VERSION ""

NS_ :

BS_:

BU_: EBOOST_HS CGM_HS BSM_HS HCP_B_HS AVM_HS PFAF_HS LVMPC_HS DCDC_HS TRCM_HS AMP_HS VICM2_HS FICM_HS ARS_HS MCP_B_HS MCP_A_HS ICCM_OBD_HS SAS_HS ACCM_HS VLBS_HS EBCM_OBD_HS HCP_T_HS EDI_HS HPCC_HS VITM_OBD_HS VICM_HS HCP_HS APPS_HS ICCM_HS EOCM_F_HS GPCM_HS VCM_HS HMIM_HS VES_HS Dummy_HS MCP_C_HS ONSTAR_HS EPS_HS TestTool_HS MCP_HS BCP_HS ALC_HS AHL_AFL_HS SADS_HS EPB_HS FCM_HS TCCM_HS RDCM_HS PTO_HS EBCM_HS ACC_HS BCM_HS TCM_HS ECM_HS
VAL_TABLE_ vt_BooleanValues 1 "true" 0 "false" ;
VAL_TABLE_ ChrgSysAudblIndRq 7 "Unused and Reserved3" 6 "Unused and Reserved2" 5 "Unused and Reserved1" 4 "Sequence 4" 3 "Sequence 3" 2 "Sequence 2" 1 "Sequence 1" 0 "Inactive" ;
VAL_TABLE_ EngPstnSnsngOpMode 2 "CAM Failed" 1 "Crank Failed" 0 "Normal" ;
VAL_TABLE_ EASSI_StrtTyp 7 "Type G" 6 "Type F" 5 "Type E" 4 "Type D" 3 "Type C" 2 "Type B" 1 "Type A" 0 "No Start" ;
VAL_TABLE_ EASSI_StrtStpSt 3 "Engine Stopping" 2 "Engine Starting" 1 "Engine Running" 0 "Engine Off" ;
VAL_TABLE_ TEPI_TrnsEngdPrFlwSt 7 "Unused and Reserved4" 6 "Unused and Reserved3" 5 "Unused and Reserved2" 4 "Unused and Reserved1" 3 "Reverse Engaged" 2 "Drive Engaged" 1 "No Powerflow" 0 "Unavailable " ;
VAL_TABLE_ TransActlRng 15 "Unused and Reserved2" 14 "Unused and Reserved1" 13 "Fourth Drive Position" 12 "Between Third and Fourth Drive Position" 11 "Third Drive Position" 10 "Between Second and Third Drive Position" 9 "Second Drive Position" 8 "Between First and Second Drive Position" 7 "First Drive Position" 6 "Between Neutral and First Drive Position" 5 "Neutral Position" 4 "Between Reverse and Neutral" 3 "Reverse Position" 2 "Between Park and Reverse" 1 "Park Position" 0 "Unknown Position" ;
VAL_TABLE_ ElcTransRngRq 7 "Unused and Reserved" 6 "Manual Range" 5 "Low Range" 4 "Drive" 3 "Neutral" 2 "Reverse" 1 "Park" 0 "No Request" ;
VAL_TABLE_ ESBR_AutoBrkgRqTyp 3 "Unused and Reserved" 2 "Hold Deny Driver Release" 1 "Hold Allow Driver Release" 0 "Release" ;
VAL_TABLE_ ESBR_AutoBrkgRqd 1 "Braking Requested" 0 "Braking Not Requested " ;
VAL_TABLE_ PndgTrnsfrCsRngShft 3 "Shift Out of Neutral Range" 2 "Shift Out of Low Range" 1 "Shift Out of High Range" 0 "None" ;
VAL_TABLE_ EngDetPndTrnCsRngShf 3 "Shift Out of Neutral Range" 2 "Shift Out of Low Range" 1 "Shift Out of High Range" 0 "None" ;
VAL_TABLE_ ElecShfRngDisp 15 "Unused & Reserved" 14 "Unused & Reserved" 13 "Unused & Reserved" 12 "Park Requested And Denied" 11 "Drive Requested And In Progress" 10 "Neutral Requested And In Progress" 9 "Reverse Requested And In Progress" 8 "Park Requested And In Progress" 7 "Reserved" 6 "Manual Nominal" 5 "Low Nominal" 4 "Drive Nominal" 3 "Neutral Nominal" 2 "Reverse Nominal" 1 "Park Nominal" 0 "No Display " ;
VAL_TABLE_ AVHSwtchStats 1 "Active" 0 "Not Active" ;
VAL_TABLE_ ThrmlRefCompStatFdbck 3 "Invalid" 2 "Inoperative" 1 "Degraded Operation" 0 "Normal Operation" ;
VAL_TABLE_ ManTransIndReq 3 "Indication 3" 2 "Indication 2" 1 "Indication 1" 0 "No Indication" ;
VAL_TABLE_ BCS2ERDTC_SysDesigntr 15 "U3-Network Codes Reserved" 14 "U2-Network Codes Reserved" 13 "U1-Network Codes MFG Controlled" 12 "U0-Network Codes SAE Controlled" 11 "B3-Body Codes Reserved" 10 "B2-Body Codes Reserved" 9 "B1-Body Codes MFG Controlled" 8 "B0-Body Codes SAE Controlled" 7 "C3-Chassis Codes Reserved" 6 "C2-Chassis Codes Reserved" 5 "C1-Chassis Codes MFG Controlled" 4 "C0-Chassis Codes SAE Controlled" 3 "P3-Powertrain Codes Reserved" 2 "P2-Powertrain Codes Reserved" 1 "P1-Powertrain Codes MFG Controlled" 0 "P0-Powertrain Codes SAE Controlled" ;
VAL_TABLE_ BCS1ERDTC_SysDesigntr 15 "U3-Network Codes Reserved" 14 "U2-Network Codes Reserved" 13 "U1-Network Codes MFG Controlled" 12 "U0-Network Codes SAE Controlled" 11 "B3-Body Codes Reserved" 10 "B2-Body Codes Reserved" 9 "B1-Body Codes MFG Controlled" 8 "B0-Body Codes SAE Controlled" 7 "C3-Chassis Codes Reserved" 6 "C2-Chassis Codes Reserved" 5 "C1-Chassis Codes MFG Controlled" 4 "C0-Chassis Codes SAE Controlled" 3 "P3-Powertrain Codes Reserved" 2 "P2-Powertrain Codes Reserved" 1 "P1-Powertrain Codes MFG Controlled" 0 "P0-Powertrain Codes SAE Controlled" ;
VAL_TABLE_ TIDCTR_TrqIntvTyp 3 "Reserved" 2 "Minimum Limit" 1 "Maximum Limit" 0 "No Request" ;
VAL_TABLE_ TIDCTR_TrqRespTyp 3 "Automatic Actuator Selection" 2 "Maximum Range" 1 "Pleasability Limited" 0 "Inactive" ;
VAL_TABLE_ ExtHlStrAssCsStRq 2 "Standard Hold" 1 "Extended Hold" 0 "No Action" ;
VAL_TABLE_ ExtHlStrAssCsCrStVal 2 "Standard Hold" 1 "Extended Hold" 0 "No Action" ;
VAL_TABLE_ BSMCT_Mult 3 "Multiplier Factor 256" 2 "Multiplier Factor 64" 1 "Multiplier Factor 8" 0 "Multiplier Factor 1" ;
VAL_TABLE_ CDP_HVDevShtdnCdARCSt 2 "Indeterminate" 1 "Fault" 0 "No Fault" ;
VAL_TABLE_ CDP_CmpSpdReqARCSt 2 "Indeterminate" 1 "Fault" 0 "No Fault" ;
VAL_TABLE_ CDSP_CmpOvrTmpSt 2 "Indeterminate" 1 "Fault" 0 "No Fault" ;
VAL_TABLE_ CDSP_CmpHVAbnrlOrVltSt 2 "Indeterminate" 1 "Fault" 0 "No Fault" ;
VAL_TABLE_ CDSP_CmpHVUndrVltgSt 2 "Indeterminate" 1 "Fault" 0 "No Fault" ;
VAL_TABLE_ CDSP_CmpHVOvrVltgSt 2 "Indeterminate" 1 "Fault" 0 "No Fault" ;
VAL_TABLE_ CDSP_CmpHVOvrCrntSt 2 "Indeterminate" 1 "Fault" 0 "No Fault" ;
VAL_TABLE_ CDSP_CmpIntShdwnFltSt 2 "Indeterminate" 1 "Fault" 0 "No Fault" ;
VAL_TABLE_ CDSP_CmpIntRecblFltSt 2 "Indeterminate" 1 "Fault" 0 "No Fault" ;
VAL_TABLE_ CDSP_CmpOpOvrldSt 2 "Indeterminate" 1 "Fault" 0 "No Fault" ;
VAL_TABLE_ CDSP_CmpDrCrctFltSt 2 "Indeterminate" 1 "Fault" 0 "No Fault" ;
VAL_TABLE_ CDSP_CmpMtrPerfFltSt 2 "Indeterminate" 1 "Fault" 0 "No Fault" ;
VAL_TABLE_ CDSP_CmpEEPROMFltSt 2 "Indeterminate" 1 "Fault" 0 "No Fault" ;
VAL_TABLE_ CDSP_CmpROMFltSt 2 "Indeterminate" 1 "Fault" 0 "No Fault" ;
VAL_TABLE_ CDSP_CmpRAMFltSt 2 "Indeterminate" 1 "Fault" 0 "No Fault" ;
VAL_TABLE_ CSSP_CmpIGBTTpOtRgLSt 2 "Indeterminate" 1 "Fault" 0 "No Fault" ;
VAL_TABLE_ CSSP_CmpIGBTTpOtRgHSt 2 "Indeterminate" 1 "Fault" 0 "No Fault" ;
VAL_TABLE_ CSSP_CmpCPUTmpOtRgLSt 2 "Indeterminate" 1 "Fault" 0 "No Fault" ;
VAL_TABLE_ CSSP_CmpCPUTmpOtRgHSt 2 "Indeterminate" 1 "Fault" 0 "No Fault" ;
VAL_TABLE_ CSSP_CmpHVSnsOtRgLSt 2 "Indeterminate" 1 "Fault" 0 "No Fault" ;
VAL_TABLE_ CSSP_CmpHVSnsOtRgHSt 2 "Indeterminate" 1 "Fault" 0 "No Fault" ;
VAL_TABLE_ CSSP_CmpPhCrntOtRgLSt 2 "Indeterminate" 1 "Fault" 0 "No Fault" ;
VAL_TABLE_ CSSP_CmpPhCrntOtRgHSt 2 "Indeterminate" 1 "Fault" 0 "No Fault" ;
VAL_TABLE_ PrtdEPBSwStat 3 "Active" 2 "Apply" 1 "Release" 0 "Not Active" ;
VAL_TABLE_ EBrkAstStat 7 "Faulted" 6 "Temporarily Failed" 5 "Not Used" 4 "Not Used" 3 "Not Used" 2 "Normal" 1 "Initializing" 0 "Not Initialized" ;
VAL_TABLE_ AdptCruzCtrlStg 7 "Performance Mode 7" 6 "Performance Mode 6" 5 "Performance Mode 5" 4 "Performance Mode 4" 3 "Performance Mode 3" 2 "Performance Mode 2" 1 "Performance Mode 1" 0 "No Action" ;
VAL_TABLE_ GFHBObjDirTrk8 1 "Ahead Traffic" 0 "Incoming Traffic" ;
VAL_TABLE_ GFHBObjDirTrk7 1 "Ahead Traffic" 0 "Incoming Traffic" ;
VAL_TABLE_ GFHBObjDirTrk6 1 "Ahead Traffic" 0 "Incoming Traffic" ;
VAL_TABLE_ GFHBObjDirTrk5 1 "Ahead Traffic" 0 "Incoming Traffic" ;
VAL_TABLE_ GFHBObjDirTrk4 1 "Ahead Traffic" 0 "Incoming Traffic" ;
VAL_TABLE_ GFHBObjDirTrk3 1 "Ahead Traffic" 0 "Incoming Traffic" ;
VAL_TABLE_ GFHBObjDirTrk2 1 "Ahead Traffic" 0 "Incoming Traffic" ;
VAL_TABLE_ GFHBObjDirTrk1 1 "Ahead Traffic" 0 "Incoming Traffic" ;
VAL_TABLE_ GFHBFwVsnRelLaneTrk8 3 "Left Lane" 2 "Right Lane" 1 "Host Lane" 0 "Unknown" ;
VAL_TABLE_ GFHBFwVsnRelLaneTrk7 3 "Left Lane" 2 "Right Lane" 1 "Host Lane" 0 "Unknown" ;
VAL_TABLE_ GFHBFwVsnRelLaneTrk6 3 "Left Lane" 2 "Right Lane" 1 "Host Lane" 0 "Unknown" ;
VAL_TABLE_ GFHBFwVsnRelLaneTrk5 3 "Left Lane" 2 "Right Lane" 1 "Host Lane" 0 "Unknown" ;
VAL_TABLE_ GFHBFwVsnRelLaneTrk4 3 "Left Lane" 2 "Right Lane" 1 "Host Lane" 0 "Unknown" ;
VAL_TABLE_ GFHBFwVsnRelLaneTrk3 3 "Left Lane" 2 "Right Lane" 1 "Host Lane" 0 "Unknown" ;
VAL_TABLE_ GFHBFwVsnRelLaneTrk2 3 "Left Lane" 2 "Right Lane" 1 "Host Lane" 0 "Unknown" ;
VAL_TABLE_ GFHBFwVsnRelLaneTrk1 3 "Left Lane" 2 "Right Lane" 1 "Host Lane" 0 "Unknown" ;
VAL_TABLE_ GFHBFwVsnMesStatTrk8 3 "Measured this cycle" 2 "Latent track not detected this cycle" 1 "New Object" 0 "No Object" ;
VAL_TABLE_ GFHBFwVsnMesStatTrk7 3 "Measured this cycle" 2 "Latent track not detected this cycle" 1 "New Object" 0 "No Object" ;
VAL_TABLE_ GFHBFwVsnMesStatTrk6 3 "Measured this cycle" 2 "Latent track not detected this cycle" 1 "New Object" 0 "No Object" ;
VAL_TABLE_ GFHBFwVsnMesStatTrk5 3 "Measured this cycle" 2 "Latent track not detected this cycle" 1 "New Object" 0 "No Object" ;
VAL_TABLE_ GFHBFwVsnMesStatTrk4 3 "Measured this cycle" 2 "Latent track not detected this cycle" 1 "New Object" 0 "No Object" ;
VAL_TABLE_ GFHBFwVsnMesStatTrk3 3 "Measured this cycle" 2 "Latent track not detected this cycle" 1 "New Object" 0 "No Object" ;
VAL_TABLE_ GFHBFwVsnMesStatTrk2 3 "Measured this cycle" 2 "Latent track not detected this cycle" 1 "New Object" 0 "No Object" ;
VAL_TABLE_ GFHBFwVsnMesStatTrk1 3 "Measured this cycle" 2 "Latent track not detected this cycle" 1 "New Object" 0 "No Object" ;
VAL_TABLE_ GFHBFwVsnCnfdncTrk8 3 "Confident" 2 "Speculative" 1 "Highly Speculative" 0 "Invalid" ;
VAL_TABLE_ GFHBFwVsnCnfdncTrk7 3 "Confident" 2 "Speculative" 1 "Highly Speculative" 0 "Invalid" ;
VAL_TABLE_ GFHBFwVsnCnfdncTrk6 3 "Confident" 2 "Speculative" 1 "Highly Speculative" 0 "Invalid" ;
VAL_TABLE_ GFHBFwVsnCnfdncTrk5 3 "Confident" 2 "Speculative" 1 "Highly Speculative" 0 "Invalid" ;
VAL_TABLE_ GFHBFwVsnCnfdncTrk4 3 "Confident" 2 "Speculative" 1 "Highly Speculative" 0 "Invalid" ;
VAL_TABLE_ GFHBFwVsnCnfdncTrk3 3 "Confident" 2 "Speculative" 1 "Highly Speculative" 0 "Invalid" ;
VAL_TABLE_ GFHBFwVsnCnfdncTrk2 3 "Confident" 2 "Speculative" 1 "Highly Speculative" 0 "Invalid" ;
VAL_TABLE_ GFHBFwVsnCnfdncTrk1 0 "Invalid" 3 "Confident" 2 "Speculative" 1 "Highly Speculative" ;
VAL_TABLE_ GFHBFVsnObjTypTrkRev8 12 "Cluster Object" 11 "Child Close to Danger Zone" 10 "Pedestrian Moving Out of Danger Zone" 9 "Pedestrian Moving Into Danger Zone" 8 "Pedestrian Standing Outside Danger Zone" 7 "No Object Present" 6 "Fixed Roadside Object" 5 "Fixed Overhead Object" 4 "Pedestrian" 3 "Motorcycle/ Bicycle" 2 "Large Vehicle (Semi)" 1 "4 Wheel Vehicle (Car)" 0 "Unknown" ;
VAL_TABLE_ GFHBFVsnObjTypTrkRev7 12 "Cluster Object" 11 "Child Close to Danger Zone" 10 "Pedestrian Moving Out of Danger Zone" 9 "Pedestrian Moving Into Danger Zone" 8 "Pedestrian Standing Outside Danger Zone" 7 "No Object Present" 6 "Fixed Roadside Object" 5 "Fixed Overhead Object" 4 "Pedestrian" 3 "Motorcycle/ Bicycle" 2 "Large Vehicle (Semi)" 1 "4 Wheel Vehicle (Car)" 0 "Unknown" ;
VAL_TABLE_ GFHBFVsnObjTypTrkRev6 12 "Cluster Object" 11 "Child Close to Danger Zone" 10 "Pedestrian Moving Out of Danger Zone" 9 "Pedestrian Moving Into Danger Zone" 8 "Pedestrian Standing Outside Danger Zone" 7 "No Object Present" 6 "Fixed Roadside Object" 5 "Fixed Overhead Object" 4 "Pedestrian" 3 "Motorcycle/ Bicycle" 2 "Large Vehicle (Semi)" 1 "4 Wheel Vehicle (Car)" 0 "Unknown" ;
VAL_TABLE_ GFHBFVsnObjTypTrkRev5 12 "Cluster Object" 11 "Child Close to Danger Zone" 10 "Pedestrian Moving Out of Danger Zone" 9 "Pedestrian Moving Into Danger Zone" 8 "Pedestrian Standing Outside Danger Zone" 7 "No Object Present" 6 "Fixed Roadside Object" 5 "Fixed Overhead Object" 4 "Pedestrian" 3 "Motorcycle/ Bicycle" 2 "Large Vehicle (Semi)" 1 "4 Wheel Vehicle (Car)" 0 "Unknown" ;
VAL_TABLE_ GFHBFVsnObjTypTrkRev4 12 "Cluster Object" 11 "Child Close to Danger Zone" 10 "Pedestrian Moving Out of Danger Zone" 9 "Pedestrian Moving Into Danger Zone" 8 "Pedestrian Standing Outside Danger Zone" 7 "No Object Present" 6 "Fixed Roadside Object" 5 "Fixed Overhead Object" 4 "Pedestrian" 3 "Motorcycle/ Bicycle" 2 "Large Vehicle (Semi)" 1 "4 Wheel Vehicle (Car)" 0 "Unknown" ;
VAL_TABLE_ GFHBFVsnObjTypTrkRev3 12 "Cluster Object" 11 "Child Close to Danger Zone" 10 "Pedestrian Moving Out of Danger Zone" 9 "Pedestrian Moving Into Danger Zone" 8 "Pedestrian Standing Outside Danger Zone" 7 "No Object Present" 6 "Fixed Roadside Object" 5 "Fixed Overhead Object" 4 "Pedestrian" 3 "Motorcycle/ Bicycle" 2 "Large Vehicle (Semi)" 1 "4 Wheel Vehicle (Car)" 0 "Unknown" ;
VAL_TABLE_ GFHBFVsnObjTypTrkRev2 12 "Cluster Object" 11 "Child Close to Danger Zone" 10 "Pedestrian Moving Out of Danger Zone" 9 "Pedestrian Moving Into Danger Zone" 8 "Pedestrian Standing Outside Danger Zone" 7 "No Object Present" 6 "Fixed Roadside Object" 5 "Fixed Overhead Object" 4 "Pedestrian" 3 "Motorcycle/ Bicycle" 2 "Large Vehicle (Semi)" 1 "4 Wheel Vehicle (Car)" 0 "Unknown" ;
VAL_TABLE_ GFHBFVsnObjTypTrkRev1 12 "Cluster Object" 11 "Child Close to Danger Zone" 10 "Pedestrian Moving Out of Danger Zone" 9 "Pedestrian Moving Into Danger Zone" 8 "Pedestrian Standing Outside Danger Zone" 7 "No Object Present" 6 "Fixed Roadside Object" 5 "Fixed Overhead Object" 4 "Pedestrian" 3 "Motorcycle/ Bicycle" 2 "Large Vehicle (Semi)" 1 "4 Wheel Vehicle (Car" 0 "Unknown" ;
VAL_TABLE_ SpdLmtrSttngTypAct 3 "Reserved" 2 "Auto" 1 "Manual" 0 "Off" ;
VAL_TABLE_ SetSpdLmtRchd 3 "Reserved" 2 "Low limit reached" 1 "High limit reached" 0 "No limit reached" ;
VAL_TABLE_ HybCrpCstCrvRq 7 "Creep Coast Curve 7" 6 "Creep Coast Curve 6" 5 "Creep Coast Curve 5" 4 "Creep Coast Curve 4" 3 "Creep Coast Curve 3" 2 "Creep Coast Curve 2" 1 "Creep Coast Curve 1" 0 "Creep Coast Curve 0" ;
VAL_TABLE_ CrpCstCrvCmd 7 "Creep Coast Curve 7" 6 "Creep Coast Curve 6" 5 "Creep Coast Curve 5" 4 "Creep Coast Curve 4" 3 "Creep Coast Curve 3" 2 "Creep Coast Curve 2" 1 "Creep Coast Curve 1" 0 "Creep Coast Curve 0" ;
VAL_TABLE_ RdGasFuelDevDisStat 3 "Reserved" 2 "Fault" 1 "Not Faulted" 0 "Indeterminate" ;
VAL_TABLE_ RdDistFuelMdReq 5 "Fault Transition Required" 4 "Fault Transition Requested" 3 "FICM" 2 "Dual" 1 "ECM" 0 "Indeterminate" ;
VAL_TABLE_ RdDistFuelMdCmdRes 3 "FICM" 2 "Dual" 1 "ECM" 0 "Indeterminate" ;
VAL_TABLE_ RdAltFuelSysStat 3 "Reserved" 2 "Fuel System Ready" 1 "Fuel System Priming" 0 "Fuel System Inactive" ;
VAL_TABLE_ RdDistFuelMdCmd 3 "FICM" 2 "Dual" 1 "ECM" 0 "Indeterminate" ;
VAL_TABLE_ PetrolFuelSysReqAval 3 "Not Available" 2 "Fault Transition Required" 1 "Fault Transition Requests" 0 "Available" ;
VAL_TABLE_ AltFuelInjHCmdLwRes 1 "FICM" 0 "ECM" ;
VAL_TABLE_ AltFuelInjGCmdLwRes 1 "FICM" 0 "ECM" ;
VAL_TABLE_ AltFuelInjFCmdLwRes 1 "FICM" 0 "ECM" ;
VAL_TABLE_ AltFuelInjECmdLwRes 1 "FICM" 0 "ECM" ;
VAL_TABLE_ AltFuelInjDCmdLwRes 1 "FICM" 0 "ECM" ;
VAL_TABLE_ AltFuelInjCCmdLwRes 1 "FICM" 0 "ECM" ;
VAL_TABLE_ AltFuelInjBCmdLwRes 1 "FICM" 0 "ECM" ;
VAL_TABLE_ AltFuelInjACmdLwRes 1 "FICM" 0 "ECM" ;
VAL_TABLE_ AdptPsngrSeatStng 7 "Performance Mode 7" 6 "Performance Mode 6" 5 "Performance Mode 5" 4 "Performance Mode 4" 3 "Performance Mode 3" 2 "Performance Mode 2" 1 "Performance Mode 1" 0 "No Action" ;
VAL_TABLE_ AdptDrvrSeatStng 7 "Performance Mode 7" 6 "Performance Mode 6" 5 "Performance Mode 5" 4 "Performance Mode 4" 3 "Performance Mode 3" 2 "Performance Mode 2" 1 "Performance Mode 1" 0 "No Action" ;
VAL_TABLE_ NAHrDisChrgM 1 "Use Data" 0 "Don't Use Data" ;
VAL_TABLE_ NAHrChgM 1 "Use Data" 0 "Don't Use Data" ;
VAL_TABLE_ MinCrnkCrntVltStat 1 "Use Data" 0 "Don't Use Data" ;
VAL_TABLE_ BattTempM 1 "Use Data" 0 "Don't Use Data" ;
VAL_TABLE_ BatVltHiResM 1 "Use Data" 0 "Don't Use Data" ;
VAL_TABLE_ BatCrntExtRngM 1 "Use Data" 0 "Don't Use Data" ;
VAL_TABLE_ CRL_Cnfdnc 7 "Reserved4" 6 "Reserved3" 5 "Reserved2" 4 "Reserved1" 3 "Best" 2 "Marking Present" 1 "Weak Marking" 0 "No Lane" ;
VAL_TABLE_ CLL_Cnfdnc 7 "Reserved4" 6 "Reserved3" 5 "Reserved2" 4 "Reserved1" 3 "Best" 2 "Marking Present" 1 "Weak Marking" 0 "No Lane" ;
VAL_TABLE_ PerfMdMainMenuType 7 "Reserved" 6 "Reserved" 5 "Reserved" 4 "Reserved" 3 "Main Menu Type 3" 2 "Main Menu Type 2" 1 "Main Menu Type 1" 0 "No Action" ;
VAL_TABLE_ PMVSS_Trans 7 "Visualization Type 7" 6 "Visualization Type 6" 5 "Visualization Type 5" 4 "Visualization Type 4" 3 "Visualization Type 3" 2 "Visualization Type 2" 1 "Visualization Type 1" 0 "No Action" ;
VAL_TABLE_ PMVSS_Susp 7 "Visualization Type 7" 6 "Visualization Type 6" 5 "Visualization Type 5" 4 "Visualization Type 4" 3 "Visualization Type 3" 2 "Visualization Type 2" 1 "Visualization Type 1" 0 "No Action" ;
VAL_TABLE_ PMVSS_Strng 7 "Visualization Type 7" 6 "Visualization Type 6" 5 "Visualization Type 5" 4 "Visualization Type 4" 3 "Visualization Type 3" 2 "Visualization Type 2" 1 "Visualization Type 1" 0 "No Action" ;
VAL_TABLE_ PMVSS_Snd 7 "Visualization Type 7" 6 "Visualization Type 6" 5 "Visualization Type 5" 4 "Visualization Type 4" 3 "Visualization Type 3" 2 "Visualization Type 2" 1 "Visualization Type 1" 0 "No Action" ;
VAL_TABLE_ PMVSS_PsngrSeat 7 "Visualization Type 7" 6 "Visualization Type 6" 5 "Visualization Type 5" 4 "Visualization Type 4" 3 "Visualization Type 3" 2 "Visualization Type 2" 1 "Visualization Type 1" 0 "No Action" ;
VAL_TABLE_ PMVSS_Exhst 7 "Visualization Type 7" 6 "Visualization Type 6" 5 "Visualization Type 5" 4 "Visualization Type 4" 3 "Visualization Type 3" 2 "Visualization Type 2" 1 "Visualization Type 1" 0 "No Action" ;
VAL_TABLE_ PMVSS_Eng 7 "Visualization Type 7" 6 "Visualization Type 6" 5 "Visualization Type 5" 4 "Visualization Type 4" 3 "Visualization Type 3" 2 "Visualization Type 2" 1 "Visualization Type 1" 0 "No Action" ;
VAL_TABLE_ PMVSS_DrvrSeat 7 "Visualization Type 7" 6 "Visualization Type 6" 5 "Visualization Type 5" 4 "Visualization Type 4" 3 "Visualization Type 3" 2 "Visualization Type 2" 1 "Visualization Type 1" 0 "No Action" ;
VAL_TABLE_ PMVSS_Drvln 7 "Visualization Type 7" 6 "Visualization Type 6" 5 "Visualization Type 5" 4 "Visualization Type 4" 3 "Visualization Type 3" 2 "Visualization Type 2" 1 "Visualization Type 1" 0 "No Action" ;
VAL_TABLE_ PMVSS_Disps 7 "Visualization Type 7" 6 "Visualization Type 6" 5 "Visualization Type 5" 4 "Visualization Type 4" 3 "Visualization Type 3" 2 "Visualization Type 2" 1 "Visualization Type 1" 0 "No Action" ;
VAL_TABLE_ PMVSS_AdptCrsCnt 7 "Visualization Type 7" 6 "Visualization Type 6" 5 "Visualization Type 5" 4 "Visualization Type 4" 3 "Visualization Type 3" 2 "Visualization Type 2" 1 "Visualization Type 1" 0 "No Action" ;
VAL_TABLE_ PsngStPerfMdCsStReq 7 "Auto" 6 "Performance Mode 6" 5 "Performance Mode 5" 4 "Performance Mode 4" 3 "Performance Mode 3" 2 "Performance Mode 2" 1 "Performance Mode 1" 0 "No Action" ;
VAL_TABLE_ PsngStPerfMdCsCrStVal 7 "Auto" 6 "Performance Mode 6" 5 "Performance Mode 5" 4 "Performance Mode 4" 3 "Performance Mode 3" 2 "Performance Mode 2" 1 "Performance Mode 1" 0 "No Action" ;
VAL_TABLE_ DrvrStPerfMdCsStReq 7 "Auto" 6 "Performance Mode 6" 5 "Performance Mode 5" 4 "Performance Mode 4" 3 "Performance Mode 3" 2 "Performance Mode 2" 1 "Performance Mode 1" 0 "No Action" ;
VAL_TABLE_ DrvrStPerfMdCsCrStVal 7 "Auto" 6 "Performance Mode 6" 5 "Performance Mode 5" 4 "Performance Mode 4" 3 "Performance Mode 3" 2 "Performance Mode 2" 1 "Performance Mode 1" 0 "No Action" ;
VAL_TABLE_ DrvStyPerfMdCsStReq 7 "Performance Mode 7" 6 "Performance Mode 6" 5 "Performance Mode 5" 4 "Performance Mode 4" 3 "Performance Mode 3" 2 "Performance Mode 2" 1 "Performance Mode 1" 0 "No Action" ;
VAL_TABLE_ DrvStyPerfMdCsCrStVal 7 "Performance Mode 7" 6 "Performance Mode 6" 5 "Performance Mode 5" 4 "Performance Mode 4" 3 "Performance Mode 3" 2 "Performance Mode 2" 1 "Performance Mode 1" 0 "No Action" ;
VAL_TABLE_ ACCPerfMdCsStReq 7 "Auto" 6 "Performance Mode 6" 5 "Performance Mode 5" 4 "Performance Mode 4" 3 "Performance Mode 3" 2 "Performance Mode 2" 1 "Performance Mode 1" 0 "No Action" ;
VAL_TABLE_ ACCPerfMdCsCrStVal 7 "Auto" 6 "Performance Mode 6" 5 "Performance Mode 5" 4 "Performance Mode 4" 3 "Performance Mode 3" 2 "Performance Mode 2" 1 "Performance Mode 1" 0 "No Action" ;
VAL_TABLE_ TCTPIR_DrvNotfn 15 "Indication 15" 14 "Indication 14" 13 "Indication 13" 12 "Indication 12" 11 "Indication 11" 10 "Indication 10" 9 "Indication 9" 8 "Indication 8" 7 "Indication 7" 6 "Indication 6" 5 "Indication 5" 4 "Indication 4" 3 "Indication 3" 2 "Indication 2" 1 "Indication 1" 0 "No Indication" ;
VAL_TABLE_ PltfrmEngSpdCmmndSt 3 "Request Denied" 2 "Lost Arbitration" 1 "Request Honored" 0 "No Request" ;
VAL_TABLE_ TrStPTGrdBrkDsMdOvr 3 "Unused and Reserved" 2 "To Grade Braking Disable" 1 "To Not Grade Braking Disable" 0 "No Override" ;
VAL_TABLE_ HiPresFuelPmpCntMd 6 "Zero Flow Mode" 5 "Noise Control Max Mode" 4 "Noise Control Disable Mode" 3 "Start Mode" 2 "Normal Mode" 1 "DFCO Mode" 0 "Disable Mode" ;
VAL_TABLE_ ClmtCtrlHtrEngRunRq 1 "Engine Run Requested" 0 "No Action" ;
VAL_TABLE_ TrnsStWntrMdOvrd 2 "Override To Winter" 1 "Override To Not Winter" 0 "No Override" ;
VAL_TABLE_ TrnsStTwHaulMdOvrd 2 "Override To Tow Haul" 1 "Override To Not Tow Haul" 0 "No Override" ;
VAL_TABLE_ TrnsStSprtMdOvrd 2 "Override To Sport" 1 "Override To Not Sport" 0 "No Override" ;
VAL_TABLE_ TrnsStEconMdOvrd 2 "Override To Economy" 1 "Override To Not Economy" 0 "No Override" ;
VAL_TABLE_ StgSysPerfMdRq 7 "Performance Mode 7" 6 "Performance Mode 6" 5 "Performance Mode 5" 4 "Performance Mode 4" 3 "Performance Mode 3" 2 "Performance Mode 2" 1 "Performance Mode 1" 0 "No Action" ;
VAL_TABLE_ SndEnhcmtPerfMdRq 7 "Performance Mode 7" 6 "Performance Mode 6" 5 "Performance Mode 5" 4 "Performance Mode 4" 3 "Performance Mode 3" 2 "Performance Mode 2" 1 "Performance Mode 1" 0 "No Action" ;
VAL_TABLE_ RideCntrlPerfMdRq 7 "Performance Mode 7" 6 "Performance Mode 6" 5 "Performance Mode 5" 4 "Performance Mode 4" 3 "Performance Mode 3" 2 "Performance Mode 2" 1 "Performance Mode 1" 0 "No Action" ;
VAL_TABLE_ ExhstPerfMdRq 7 "Performance Mode 7" 6 "Performance Mode 6" 5 "Performance Mode 5" 4 "Performance Mode 4" 3 "Performance Mode 3" 2 "Performance Mode 2" 1 "Performance Mode 1" 0 "No Action" ;
VAL_TABLE_ DsplyPerfMdRq 7 "Performance Mode 7" 6 "Performance Mode 6" 5 "Performance Mode 5" 4 "Performance Mode 4" 3 "Performance Mode 3" 2 "Performance Mode 2" 1 "Performance Mode 1" 0 "No Action" ;
VAL_TABLE_ DiffPerfMdRq 7 "Performance Mode 7" 6 "Performance Mode 6" 5 "Performance Mode 5" 4 "Performance Mode 4" 3 "Performance Mode 3" 2 "Performance Mode 2" 1 "Performance Mode 1" 0 "No Action" ;
VAL_TABLE_ AWDPerfMdRq 7 "Performance Mode 7" 6 "Performance Mode 6" 5 "Performance Mode 5" 4 "Performance Mode 4" 3 "Performance Mode 3" 2 "Performance Mode 2" 1 "Performance Mode 1" 0 "No Action" ;
VAL_TABLE_ RdHVltBatPckVltM 1 "Use Data" 0 "Don't Use Data" ;
VAL_TABLE_ RdHVltBatPckCrntM 1 "Use Data" 0 "Don't Use Data" ;
VAL_TABLE_ RdHVltBatMinClVltM 1 "Use Data" 0 "Don't Use Data" ;
VAL_TABLE_ RdHVltBatMaxClVltM 1 "Use Data" 0 "Don't Use Data" ;
VAL_TABLE_ AFRP_SnsTyp 3 "Gauge Pressure" 2 "Absolute Pressure" 1 "Pressure Relative Manifold Vacuum" 0 "Not Supported" ;
VAL_TABLE_ FICMDS3_DTCStatus 4 "Diagnostic Failed" 3 "Diagnostic Passed" 2 "No Status to Report" 1 "Critically Disabled" 0 "Not Supported" ;
VAL_TABLE_ FICMDS2_DTCStatus 4 "Diagnostic Failed" 3 "Diagnostic Passed" 2 "No Status to Report" 1 "Critically Disabled" 0 "Not Supported" ;
VAL_TABLE_ FICMDS1_DTCStatus 4 "Diagnostic Failed" 3 "Diagnostic Passed" 2 "No Status to Report" 1 "Critically Disabled" 0 "Not Supported" ;
VAL_TABLE_ PropSysOffTmeM 1 "Use Data" 0 "Don't Use Data" ;
VAL_TABLE_ OffBrdChrgOffTmeM 1 "Use Data" 0 "Don't Use Data" ;
VAL_TABLE_ BattThrmlCondOffTmeM 1 "Use Data" 0 "Don't Use Data" ;
VAL_TABLE_ CrsSecSwStat 15 "Unused and Reserved 7" 14 "Unused and Reserved 6" 13 "Unused and Reserved 5" 12 "Unused and Reserved 4" 11 "Unused and Reserved 3" 10 "Unused and Reserved 2" 9 "Between Ranges" 8 "Short to Power" 7 "Open/Short to Ground" 6 "Speed Decrease High" 5 "Speed Increase High" 4 "Gap Up" 3 "Gap Down" 2 "Unused and Reserved 1" 1 "No Activation" 0 "Indeterminate" ;
VAL_TABLE_ EDADS_RcmndtFwdGr 15 "Unused and Reserved 7" 14 "Unused and Reserved 6" 13 "Unused and Reserved 5" 12 "Unused and Reserved 4" 11 "Unused and Reserved 3" 10 "Unused and Reserved 2" 9 "Unused and Reserved 1" 8 "Eighth Gear" 7 "Seventh Gear" 6 "Sixth Gear" 5 "Fifth Gear" 4 "Fourth Gear" 3 "Third Gear" 2 "Second Gear" 1 "First Gear" 0 "None" ;
VAL_TABLE_ EDADS_CrntFwdMsdG 15 "Unused and Reserved 7" 14 "Unused and Reserved 6" 13 "Unused and Reserved 5" 12 "Unused and Reserved 4" 11 "Unused and Reserved 3" 10 "Unused and Reserved 2" 9 "Unused and Reserved 1" 8 "Eighth Gear" 7 "Seventh Gear" 6 "Sixth Gear" 5 "Fifth Gear" 4 "Fourth Gear" 3 "Third Gear" 2 "Second Gear" 1 "First Gear" 0 "None" ;
VAL_TABLE_ EDADS_ShftIndStat 2 "No Shift" 1 "Shift Up" 0 "Shift Down" ;
VAL_TABLE_ GPCMDS2_DTCStatus 4 "Diagnostic Failed" 3 "Diagnostic Passed" 2 "No Status to Report" 1 "Critically Disabled" 0 "Not Supported" ;
VAL_TABLE_ EngPwrCnfg 15 "Configuration 15" 14 "Configuration 14" 13 "Configuration 13" 12 "Configuration 12" 11 "Configuration 11" 10 "Configuration 10" 9 "Configuration 9" 8 "Configuration 8" 7 "Configuration 7" 6 "Configuration 6" 5 "Configuration 5" 4 "Configuration 4" 3 "Configuration 3" 2 "Configuration 2" 1 "Configuration 1" 0 "Default" ;
VAL_TABLE_ CTSS_StbltyLvl 7 "Level 7" 6 "Level 6" 5 "Level 5" 4 "Level 4" 3 "Level 3" 2 "Level 2" 1 "Level 1" 0 "Level 0" ;
VAL_TABLE_ CTSS_StbltyTyp 7 "Unused and Reserved 4" 6 "Unused and Reserved 3" 5 "Unused and Reserved 2" 4 "Unused and Reserved 1" 3 "Torque Increase Pending" 2 "Torque Decrease Pending" 1 "Torque High Pulsation" 0 "Normal Stability" ;
VAL_TABLE_ DslExhFldWrngIdRqER 15 "Warning Level 15" 14 "Warning Level 14" 13 "Warning Level 13" 12 "Warning Level 12" 11 "Warning Level 11" 10 "Warning Level 10" 9 "Warning Level 9" 8 "Warning Level 8" 7 "Warning Level 7" 6 "Warning Level 6" 5 "Warning Level 5" 4 "Warning Level 4" 3 "Warning Level 3" 2 "Warning Level 2" 1 "Warning Level 1" 0 "No Indication" ;
VAL_TABLE_ DslExhFldQlyWrngIReq 15 "Warning Level 15" 14 "Warning Level 14" 13 "Warning Level 13" 12 "Warning Level 12" 11 "Warning Level 11" 10 "Warning Level 10" 9 "Warning Level 9" 8 "Warning Level 8" 7 "Warning Level 7" 6 "Warning Level 6" 5 "Warning Level 5" 4 "Warning Level 4" 3 "Warning Level 3" 2 "Warning Level 2" 1 "Warning Level 1" 0 "No Indication" ;
VAL_TABLE_ DslExNxEmWrngIndRq 15 "Warning Level 15" 14 "Warning Level 14" 13 "Warning Level 13" 12 "Warning Level 12" 11 "Warning Level 11" 10 "Warning Level 10" 9 "Warning Level 9" 8 "Warning Level 8" 7 "Warning Level 7" 6 "Warning Level 6" 5 "Warning Level 5" 4 "Warning Level 4" 3 "Warning Level 3" 2 "Warning Level 2" 1 "Warning Level 1" 0 "No Indication" ;
VAL_TABLE_ DslExFldTpWrngIndRq 15 "Warning Level 15" 14 "Warning Level 14" 13 "Warning Level 13" 12 "Warning Level 12" 11 "Warning Level 11" 10 "Warning Level 10" 9 "Warning Level 9" 8 "Warning Level 8" 7 "Warning Level 7" 6 "Warning Level 6" 5 "Warning Level 5" 4 "Warning Level 4" 3 "Warning Level 3" 2 "Warning Level 2" 1 "Warning Level 1" 0 "No Indication" ;
VAL_TABLE_ DslExFldCnWrngIndRq 15 "Warning Level 15" 14 "Warning Level 14" 13 "Warning Level 13" 12 "Warning Level 12" 11 "Warning Level 11" 10 "Warning Level 10" 9 "Warning Level 9" 8 "Warning Level 8" 7 "Warning Level 7" 6 "Warning Level 6" 5 "Warning Level 5" 4 "Warning Level 4" 3 "Warning Level 3" 2 "Warning Level 2" 1 "Warning Level 1" 0 "No Indication" ;
VAL_TABLE_ DrvSelMdSw3Sta 1 "Active" 0 "Inactive" ;
VAL_TABLE_ DrvSelMdSw2Sta 1 "Active" 0 "Inactive" ;
VAL_TABLE_ DrvSelMd8Stat 1 "Active" 0 "Inactive" ;
VAL_TABLE_ DrvSelMd7Stat 1 "Active" 0 "Inactive" ;
VAL_TABLE_ DrvSelMd6Stat 1 "Active" 0 "Inactive" ;
VAL_TABLE_ DrvSelMd5Stat 1 "Active" 0 "Inactive" ;
VAL_TABLE_ DrvSelMd4Stat 1 "Active" 0 "Inactive" ;
VAL_TABLE_ DrvSelMd3Stat 1 "Active" 0 "Inactive" ;
VAL_TABLE_ DrvSelMd2Stat 1 "Active" 0 "Inactive" ;
VAL_TABLE_ A6ERRAlrmReq 2 "Cancel Alarm" 1 "Set Alarm" 0 "No Action" ;
VAL_TABLE_ MntnceMdDsplyRq 15 "Unused and Reserved" 14 "Continue FM" 13 "Force FM" 12 "FM 1 Day Warning" 11 "FM 2 Day Warning" 10 "FM 3 Day Warning" 9 "FM 4 Day Warning" 8 "FM 5 Day Warning" 7 "Continue EM" 6 "Force EM" 5 "EM 1 Day Warning" 4 "EM 2 Day Warning" 3 "EM 3 Day Warning" 2 "EM 4 Day Warning" 1 "EM 5 Day Warning" 0 "No Request" ;
VAL_TABLE_ HybACCompRq 3 "Reserved" 2 "Disengage" 1 "Engage" 0 "No Action" ;
VAL_TABLE_ TrnsInpDvcStat 7 "Unused and Reserved 5" 6 "Unused and Reserved 4" 5 "Unused and Reserved 3" 4 "Unused and Reserved 2" 3 "Unused and Reserved 1" 2 "Permanent Isolation" 1 "Temporary Isolation" 0 "Normal Control" ;
VAL_TABLE_ AuxClntHtrVlvStat 7 "Unused and Reserved 2" 6 "De-Aeration Routine Active" 5 "Diagnostic Override" 4 "Re-Calibration" 3 "Fault Active" 2 "Engine Link" 1 "Transition" 0 "Engine Bypass" ;
VAL_TABLE_ DrvSelMdSw1Sta 1 "Active" 0 "Inactive" ;
VAL_TABLE_ DrvSelMd1Stat 1 "Active" 0 "Inactive" ;
VAL_TABLE_ ETC_EngOpMd 1 "Half Cylinders" 0 "All cylinders" ;
VAL_TABLE_ EngCntrlUtldTrnCsRng 3 "Neutral" 2 "Unused and Reserved" 1 "Low" 0 "High" ;
VAL_TABLE_ CSTATRS_ReqStat 6 "Control System Failure Permanent" 5 "Control System Failure Temporary" 4 "Serial Data Failure Permanent" 3 "Serial Data Failure Temporary" 2 "Lost Arbitration" 1 "Request Honored" 0 "No Request" ;
VAL_TABLE_ CSTATRS_LmtgStat 3 "Rate and Value Limited" 2 "Value Limited" 1 "Rate Limited" 0 "Not Limited" ;
VAL_TABLE_ PTTrnsfrCseMd 3 "Neutral" 2 "4 Wheel Drive Low" 1 "4 Wheel Drive High" 0 "2 Wheel Drive High" ;
VAL_TABLE_ TrnsHybEngSrtStpOvrd 2 "Engine Off" 1 "Engine On" 0 "No Override" ;
VAL_TABLE_ EngCntrlDtrmdTrfCRng 3 "Neutral" 2 "Unused and Reserved" 1 "Low" 0 "High" ;
VAL_TABLE_ ElecPrkBrkAvailStat 7 "Unused and Reserved 3" 6 "Unused and Reserved 2" 5 "Unused and Reserved 1" 4 "Unavailable, Failed other" 3 "Unavailable, Failed Released" 2 "Unavailable, Failed Applied" 1 "Available, Not Failed" 0 "Unavailable, Not Failed" ;
VAL_TABLE_ ElecPrkBrkApplStat 3 "Park Brake Application in Progress" 2 "Park brake Released" 1 "Park Brake Applied" 0 "Unknown" ;
VAL_TABLE_ BCHR_BattCrntRwVlMu 3 "Multiplier Factor 256" 2 "Multiplier Factor 64" 1 "Multiplier Factor 8" 0 "Multiplier Factor 1" ;
VAL_TABLE_ BattSOXStat 1 "Use SOC,SOH, & SOF" 0 "Don't Use SOC,SOH, & SOF" ;
VAL_TABLE_ CSPATR_TrqIntrvnTyp 3 "Minimum and Maximum Limit" 2 "Minimum Limit" 1 "Maximum Limit" 0 "No Intervention" ;
VAL_TABLE_ CSPATR_TrqRqTyp 0 "Absolute Torque Request" ;
VAL_TABLE_ ChsSysAxlTqRqRspTyp 4 "Braking Torque Request" 3 "Automatic Actuator Selection" 2 "Maximum Range Request" 1 "Pleasability Limited Request" 0 "Inactive" ;
VAL_TABLE_ EngOffTmPTM 1 "Use Data" 0 "Don't Use Data" ;
VAL_TABLE_ HybMdDisp 15 "Engine Charging Battery While Idle" 14 "Engine Charging Battery Moving" 13 "Engine Power Load Sharing" 12 "Battery Power Load Sharing" 11 "Undetermined" 10 "Charging With Engine On" 9 "Charging With Engine Off" 8 "Hybrid Power 4WD" 7 "Hybrid Power 2WD" 6 "Engine Power 4WD" 5 "Engine Power 2WD" 4 "Battery Power 4WD" 3 "Battery Power 2WD" 2 "Auto Stop" 1 "Engine Idle" 0 "Default / Accessory" ;
VAL_TABLE_ PerfTrcTrqRqStat 6 "Control System Failure Permanent" 5 "Control System Failure Temporary" 4 "Serial Data Failure Permanent" 3 "Serial Data Failure Temporary" 2 "Lost Arbitration" 1 "Request Honored" 0 "No Request" ;
VAL_TABLE_ PTTR_TrqRedRlzSugg 1 "Transient Optimized" 0 "No Suggestion" ;
VAL_TABLE_ PTTR_TrqInvTyp 1 "Maximum Limit" 0 "No Intervention" ;
VAL_TABLE_ PerfTrcTrqLmtStat 3 "Rate & Value Limited" 2 "Value Limited" 1 "Rate Limited" 0 "Not Limited" ;
VAL_TABLE_ PerfTrcEngSpdRqStat 6 "Control System Failure Permanent" 5 "Control System Failure Temporary" 4 "Serial Data Failure Permanent" 3 "Serial Data Failure Temporary" 2 "Lost Arbitration" 1 "Request Honored" 0 "No Request" ;
VAL_TABLE_ PTESR_EngSpdCntlRs 3 "Stability Optimized Cond 2" 2 "Stability Optimized Cond 1" 1 "Transient Optimized" 0 "No Suggestion" ;
VAL_TABLE_ PTESR_EngSpdIntTyp 1 "Engine Speed Max Limit" 0 "No Intervention" ;
VAL_TABLE_ PerfTrcEngSpdLmtStat 3 "Rate & Value Limited" 2 "Value Limited" 1 "Rate Limited" 0 "Not Limited" ;
VAL_TABLE_ TPCTR_TrqIntrvnTyp 3 "Unused and Reserved" 2 "Minimum Limit" 1 "Maximum Limit" 0 "No Request" ;
VAL_TABLE_ EngCrsCntrlMode 5 "Tap" 4 "Coast" 3 "Accel" 2 "Resume" 1 "Engaged" 0 "Inactive" ;
VAL_TABLE_ EngPrdctTrqTnsRqStat 7 "Unused and Reserved" 6 "Control System Failure Permanent" 5 "Control System Failure Temporary" 4 "Serial Data Failure Permanent" 3 "Serial Data Failure Temporary" 2 "Lost Arbitration" 1 "Request Honored" 0 "No Request" ;
VAL_TABLE_ EngPrdctTrqTnsRqLmS 7 "Unused and Reserved 4" 6 "Unused and Reserved 3" 5 "Unused and Reserved 2" 4 "Unused and Reserved 1" 3 "Value Limited High" 2 "Value Limited Low" 1 "Rate Limited" 0 "Not Limited" ;
VAL_TABLE_ EngImmTrqTnsRqStat 0 "No Request" 7 "Unused and Reserved" 6 "Control System Failure Permanent" 5 "Control System Failure Temporary" 4 "Serial Data Failure Permanent" 3 "Serial Data Failure Temporary" 2 "Lost Arbitration" 1 "Request Honored" ;
VAL_TABLE_ EngImmTrqTnsRqLmSt 7 "Unused and Reserved 4" 6 "Unused and Reserved 3" 5 "Unused and Reserved 2" 4 "Unused and Reserved 1" 3 "Value Limited High" 2 "Value Limited Low" 1 "Rate Limited" 0 "Not Limited" ;
VAL_TABLE_ CrsSpdLmtrSwStat 9 "Between Ranges" 8 "Short to Power" 7 "Open/Short to Ground" 6 "Cancel" 5 "Cruise On/Off" 4 "SL/SW On/Off/GAP" 3 "Set" 2 "Resume" 1 "No Activation" 0 "Indeterminate" ;
VAL_TABLE_ RrAxlSta 3 "Permanently Failed" 2 "Temporary Limited" 1 "Temporary Inhibit" 0 "Normal" ;
VAL_TABLE_ SecAxlStat 3 "Permanently Failed" 2 "Temporary Limited" 1 "Temporary Inhibit" 0 "Normal" ;
VAL_TABLE_ HESSI_EngStrtTyp 9 "Compression Test" 8 "Auto Start Generic" 7 "Auto Start Aggressive" 6 "Auto Start Normal" 5 "Auto Start Smooth" 4 "Key Start Generic" 3 "Key Start Low Power B" 2 "Key Start Low Power" 1 "Key Start Normal" 0 "No Start" ;
VAL_TABLE_ HESSI_EngStrtStpMd 7 "Start Failed" 6 "Stop Pending" 5 "Disable Fuel" 4 "Producing Torque" 3 "Enable Fuel" 2 "Start Pending" 1 "Immediate Stop" 0 "Stop" ;
VAL_TABLE_ HybDFCOReq 1 "DFCO Requested" 0 "DFCO Not Requested" ;
VAL_TABLE_ EngCntlSenPTRlyVltM 1 "Use Data" 0 "Don't Use Data" ;
VAL_TABLE_ GPCMDS_DTCStatus 4 "Diagnostic Failed" 3 "Diagnostic Passed" 2 "No Status to Report" 1 "Critically Disabled" 0 "Not Supported" ;
VAL_TABLE_ IQAI_InjIdInd 7 "Injector 8" 6 "Injector 7" 5 "Injector 6" 4 "Injector 5" 3 "Injector 4" 2 "Injector 3" 1 "Injector 2" 0 "Injector 1" ;
VAL_TABLE_ IQAI_DataStat 1 "IQA Data Byte Stored" 0 "IQA Data Byte Not Stored" ;
VAL_TABLE_ ACCATC_DrvAstdGoSt 2 "Apply Acc Pedal or Resume Sw To Go" 1 "Apply Accel Pedal to Go" 0 "Not Stopped" ;
VAL_TABLE_ WhlSlpSt 3 "Slip Detection Fault" 2 "Positive Slip Detected" 1 "Negative Slip Detected" 0 "No Slip Detected" ;
VAL_TABLE_ EnhSvVehTopSpdLmR 2 "Inactive" 1 "Active" 0 "No Action" ;
VAL_TABLE_ ACCmEngRunReq 1 "Engine Run Requested" 0 "No Action" ;
VAL_TABLE_ FuelMdSwAct 1 "True" 0 "False" ;
VAL_TABLE_ FuelMdStat 3 "Alternative Fuel Cut-off Active" 2 "Liquified Petroleum Gas Mode" 1 "Natural Gas Mode" 0 "Gasoline Mode" ;
VAL_TABLE_ WrmUpShftPtrnRq 1 "Active" 0 "Inactive" ;
VAL_TABLE_ EngCntrlRunCrnkTrmSt 1 "Active" 0 "Inactive" ;
VAL_TABLE_ ACCATC_ACCTyp 2 "Full Speed Range ACC with Booster" 1 "Full Speed Range ACC" 0 "Adaptive Cruise Control" ;
VAL_TABLE_ ACCATCS_RqStat 4 "Request Suspended Till Driver Input" 3 "Request Denied" 2 "Lost Arbitration" 1 "Request Honored" 0 "No Request" ;
VAL_TABLE_ ACCATCS_LmtgStat 3 "Request Rate Limited" 2 "Request Value Limited Maximum" 1 "Request Value Limited Minimum" 0 "Request Not Limited" ;
VAL_TABLE_ EPBSysWrnIndReq 3 "Flash Rate #2 Indication" 2 "Flash Rate #1 Indication" 1 "Continuous Indication" 0 "No Indication" ;
VAL_TABLE_ ClmnLckStat 2 "Locked unsuccessful" 1 "Unlocked" 0 "Locked" 3 "Unlocked unsuccessful" ;
VAL_TABLE_ VehSpeSta 3 "Invalid" 2 "Fast" 1 "Slow" 0 "Stationary" ;
VAL_TABLE_ DslPartFltrClngAlgActM 1 "Use Data" 0 "Don't Use Data" ;
VAL_TABLE_ SecAxlOpeMod 3 "Active All Wheel Drive (High)" 2 "4 Wheel Drive Low Locked" 1 "4 Wheel Drive High Locked" 0 "2 Wheel Drive High" 15 "Neutral" 14 "Unknown" 7 "2 Wheel Drive Low" 6 "Active All Wheel Drive (Low)" 5 "4 Wheel Drive Low Open" 4 "4 Wheel Drive High Open" ;
VAL_TABLE_ SecAxlCtrlMod 1 "External" 0 "Internal" ;
VAL_TABLE_ RrAxlOpeMod 3 "Unknown" 2 "Locked" 1 "Active" 0 "Open" ;
VAL_TABLE_ RrAxlCtrlMod 1 "External" 0 "Internal" ;
VAL_TABLE_ EPBSwSta 3 "Active" 2 "Apply" 1 "Release" 0 "NotActive" ;
VAL_TABLE_ EPBSta 2 "Fault" 1 "Applied" 0 "Released" ;
VAL_TABLE_ FlPmpEDscOtptCmdSta 1 "Fuel Pump Enabled" 0 "Fuel Pump Disabled" ;
VAL_TABLE_ TransTUDMdStat 2 "Electronic Range Select Active" 1 "Driver Shift Control Active" 0 "No Activation" ;
VAL_TABLE_ TrnShftPtrnActStat 6 "PT Protection Pattern Active" 5 "PT Non-Protection Pattern Active" 4 "Shift Pattern 4 Active" 3 "Shift Pattern 3 Active" 2 "Shift Pattern 2 Active" 1 "Shift Pattern 1 Active" 0 "Default Shift Pattern Active" ;
VAL_TABLE_ EPBSysAudWarnReq 2 "Warning #2" 1 "Warning #1" 0 "Off" ;
VAL_TABLE_ NotEventSta 2 "Pretensioner Deployment Event" 1 "Near Deployment Event" 0 "No Event" 3 "Airbag Deployment Event" ;
VAL_TABLE_ VehMovSta 4 "Invalid" 3 "Reverse" 2 "Forward" 1 "Neutral" 0 "Parked" ;
VAL_TABLE_ PFTrnsTUDSwSt 3 "Illegal Up/Down Switch State Active" 2 "Decrement Switch Active" 1 "Increment Switch Active" 0 "No Activation" ;
VAL_TABLE_ PFTrnsTUDEnSwSt 3 "Illegal Enable Switch State" 2 "Electronic Range Select Enable Sw" 1 "Driver Shift Control Enable Switch" 0 "No Activation" ;
VAL_TABLE_ AuxHtrRq 1 "On" 0 "Off" ;
VAL_TABLE_ TrnsEngdState 3 "Operating State Not Reached" 2 "Transmission Engaged in Reverse" 1 "Transmission Engaged in Forward" 0 "Transmission Not Engaged" ;
VAL_TABLE_ EPBSysDspMsgReq 7 "Message #7" 6 "Message #6" 5 "Message #5" 4 "Message #4" 3 "Message #3" 2 "Message #2" 1 "Message #1" 0 "Off" ;
VAL_TABLE_ OtsdAmbtLtLvlStat 2 "Day" 1 "Night" 0 "Unknown" ;
VAL_TABLE_ RdSpdCatType 3 "all speed categories 0 - 50 km/h" 2 "all speed categories 51-80 km/h" 1 "all speed categories 81-130 km/h" 0 "all speed categories > 130 km/h" ;
VAL_TABLE_ LnCat 3 "Four Or More Lanes" 2 "Two Or Three Lanes" 1 "One lane" 0 "no info available" ;
VAL_TABLE_ FncRdClass 7 "COLLECTOR" 6 "ALLEY" 5 "ARTERIAL" 4 "HIGHWAY" 3 "PED-MALL" 2 "FREEWAY" 1 "SFREEWAY" 0 "LOCAL (Residential Road)" ;
VAL_TABLE_ CustomizationSettingRequest 7 "Auto" 6 "Performance Mode 6" 5 "Performance Mode 5" 4 "Performance Mode 4" 3 "Performance Mode 3" 2 "Performance Mode 2" 1 "Performance Mode 1" 0 "No Action" ;
VAL_TABLE_ RstrCustFctrDef 1 "Restore Defaults" 0 "No Action" ;
VAL_TABLE_ PFTrnsTUDSecSwSt 3 "Illegal Up/Down Switch State Active" 2 "Decrement Switch Active" 1 "Increment Switch Active" 0 "No Activation" ;
VAL_TABLE_ AdvFrntLghtSysIndRq 7 "Indication 7" 6 "Indication 6" 5 "Indication 5" 4 "Indication 4" 3 "Indication 3" 2 "Indication 2" 1 "Indication 1" 0 "No Indication" ;
VAL_TABLE_ CustomizationCurrentSettingValue 7 "Auto" 6 "Performance Mode 6" 5 "Performance Mode 5" 4 "Performance Mode 4" 3 "Performance Mode 3" 0 "No Action" 1 "Performance Mode 1" 2 "Performance Mode 2" ;
VAL_TABLE_ EPBSysStatIndReq 3 "Flash Rate 2 Indication" 2 "Flash Rate 1 Indication" 1 "Continuous Indication" 0 "No Indication" ;
VAL_TABLE_ AllNodesVNA 1 "Activate Virtual Network" 0 "No Activation" ;
VAL_TABLE_ ClntCircPmpRq 1 "On" 0 "Off" ;
VAL_TABLE_ ImoIdSt 1 "Info valid" 0 "No info" ;
VAL_TABLE_ LrnEnvIdSt 1 "Info_valid" 0 "No_info" ;
VAL_TABLE_ EnvIdRspSt4 3 "Environment_id_request" 2 "Incorrect_immo_id" 1 "Info_valid" 0 "No_info" ;
VAL_TABLE_ VDAvailability 1 "VirtualDeviceAvailable" 0 "VirtualDeviceUnavailable" ;
VAL_TABLE_ AlrmStat 4 "Arming Delay" 3 "Alarm Active" 2 "Disarmed" 1 "Armed" 0 "Off" ;
VAL_TABLE_ RstVTDTmprDtctd 1 "Reset" 0 "No Action" ;
VAL_TABLE_ RstIllDrIdDevDtctd 1 "Reset" 0 "No Action" ;
VAL_TABLE_ RstDrIdDevLrnd 1 "Reset" 0 "No Action" ;
VAL_TABLE_ CldrMth 12 "December" 11 "November" 10 "October" 9 "September" 8 "August" 7 "July" 6 "June" 5 "May" 4 "April" 3 "March" 2 "February" 1 "January" 0 "Unknown" ;
VAL_TABLE_ TrnSwAct 2 "Right" 1 "Left" 0 "No Activation" ;
VAL_TABLE_ VehHghtStat 4 "Maximum Height" 3 "Kneeling Height" 2 "Aerodynamic Height" 1 "Normal Design Ride Height" 0 "Unknown" ;
VAL_TABLE_ HdlmpBmSelectStat 2 "High Beams" 1 "Low Beams" 0 "Unknown" ;
VAL_TABLE_ ACSAlarm9 2 "Expired" 1 "Active" 0 "Inactive" ;
VAL_TABLE_ ACSAlarm8 2 "Expired" 1 "Active" 0 "Inactive" ;
VAL_TABLE_ ACSAlarm7 2 "Expired" 1 "Active" 0 "Inactive" ;
VAL_TABLE_ ACSAlarm6 2 "Expired" 1 "Active" 0 "Inactive" ;
VAL_TABLE_ ACSAlarm5 2 "Expired" 1 "Active" 0 "Inactive" ;
VAL_TABLE_ ACSAlarm4 2 "Expired" 1 "Active" 0 "Inactive" ;
VAL_TABLE_ ACSAlarm3 2 "Expired" 1 "Active" 0 "Inactive" ;
VAL_TABLE_ ACSAlarm2 2 "Expired" 1 "Active" 0 "Inactive" ;
VAL_TABLE_ ACSAlarm15 2 "Expired" 1 "Active" 0 "Inactive" ;
VAL_TABLE_ ACSAlarm14 2 "Expired" 1 "Active" 0 "Inactive" ;
VAL_TABLE_ ACSAlarm13 2 "Expired" 1 "Active" 0 "Inactive" ;
VAL_TABLE_ ACSAlarm12 2 "Expired" 1 "Active" 0 "Inactive" ;
VAL_TABLE_ ACSAlarm11 2 "Expired" 1 "Active" 0 "Inactive" ;
VAL_TABLE_ ACSAlarm10 2 "Expired" 1 "Active" 0 "Inactive" ;
VAL_TABLE_ ACSAlarm1 2 "Expired" 1 "Active" 0 "Inactive" ;
VAL_TABLE_ ACSAlarm0 2 "Expired" 1 "Active" 0 "Inactive" ;
VAL_TABLE_ ACCHdwyStg 7 "Headway Setting 7" 6 "Headway Setting 6" 5 "Headway Setting 5" 4 "Headway Setting 4" 3 "Headway Setting 3" 2 "Headway Setting 2" 1 "Headway Setting 1" 0 "Minimum Headway Setting" ;
VAL_TABLE_ VehStabEnhmntMd 2 "Competitive" 1 "Normal" 0 "Off" ;
VAL_TABLE_ VehStabEnhmntStat 4 "Not Ready" 3 "Warming Up" 2 "Fault" 1 "Active" 0 "Inactive" ;
VAL_TABLE_ TCSysOpMd 2 "Off Road" 1 "Normal" 0 "Off" ;
VAL_TABLE_ TCSysOpStat 2 "Fault" 1 "Active" 0 "Inactive" ;
VAL_TABLE_ HillDscntCntlSysStat 4 "Temporarily Inhibited" 3 "Failed" 2 "Active" 1 "Enabled" 0 "Normal" ;
VAL_TABLE_ EnrgMgtLdShdRq 4 "Load Shed Level 4" 3 "Load Shed Level 3" 2 "Load Shed Level 2" 1 "Load Shed Level 1" 0 "No Load Shedding" ;
VAL_TABLE_ DrId 7 "Unknown" 6 "Driver #7" 5 "Driver #6" 4 "Driver #5" 3 "Driver #4" 2 "Driver #3" 1 "Driver #2" 0 "Driver #1" ;
VAL_TABLE_ TireRRPrsStat 5 "High" 4 "Low - Extended Mobility" 3 "Low" 2 "Low - Service Now" 1 "Nominal" 0 "Unknown" ;
VAL_TABLE_ TireRFPrsStat 5 "High" 4 "Low - Extended Mobility" 3 "Low" 2 "Low - Service Now" 1 "Nominal" 0 "Unknown" ;
VAL_TABLE_ TireLRPrsStat 5 "High" 4 "Low - Extended Mobility" 3 "Low" 2 "Low - Service Now" 1 "Nominal" 0 "Unknown" ;
VAL_TABLE_ TireLFPrsStat 5 "High" 4 "Low - Extended Mobility" 3 "Low" 2 "Low - Service Now" 1 "Nominal" 0 "Unknown" ;
VAL_TABLE_ DTCI_DTCFaultType 3 "Type C" 2 "Type B" 1 "Type A" 0 "Not Supported" ;
VAL_TABLE_ DistRollCntAvgDrvnSrc 1 "Wheel Speed" 0 "Transmission Output Speed" ;
VAL_TABLE_ VehSpdAvgDrvnSrc 1 "Wheel Speed" 0 "Transmission Output Speed" ;
VAL_TABLE_ TORSLstTransType 3 "Undefined" 2 "Falling Transition" 1 "Rising Transition" 0 "Single Edge Sensor" ;
VAL_TABLE_ TORSRotDir 3 "Undefined" 2 "Reverse" 1 "Forward" 0 "Unknown" ;
VAL_TABLE_ TrnsThrmlMngmntStat 2 "Driver Intervention Requested" 1 "Countermeasures Active" 0 "Normal" ;
VAL_TABLE_ TrnsSftMdStat 3 "Automatic Grade Braking Mode" 2 "Lift-Foot Cornering Mode" 1 "Performance Mode" 0 "No Override Mode" ;
VAL_TABLE_ TrnsRngInhbtStat 4 "Diagnostic Inhibit Active" 3 "Driveline Not Engaged" 2 "Transmission Range Re-Selection Req" 1 "Transmission Inhibit Active" 0 "No Range Inhibit Active" ;
VAL_TABLE_ DrvtShftCntrlTrgtGear 8 "Eighth Gear" 7 "Seventh Gear" 6 "Sixth Gear" 5 "Fifth Gear" 4 "Fourth Gear" 3 "Third Gear" 2 "Second Gear" 1 "First Gear" 0 "Not Supported" ;
VAL_TABLE_ StrWhlAngSenCalStat 2 "Calibrated" 1 "Estimated" 0 "Unknown" ;
VAL_TABLE_ PTOTGRReqdGear 8 "Eighth Gear" 7 "Seventh Gear" 6 "Sixth Gear" 5 "Fifth Gear" 4 "Fourth Gear" 3 "Third Gear" 2 "Second Gear" 1 "First Gear" 0 "No Action" ;
VAL_TABLE_ PTOTGRReqType 3 "Hold Gear" 2 "Min Gear Request" 1 "Max Gear Request" 0 "No Action" ;
VAL_TABLE_ PTORmtEngStrtReq 1 "PTO Remote Start Requested" 0 "PTO Remote Start Not Requested" ;
VAL_TABLE_ FSERDTC_SysDes 15 "U3-Network Codes Reserved" 14 "U2-Network Codes Reserved" 13 "U1-Network Codes MFG Controlled" 12 "U0-Network Codes SAE Controlled" 11 "B3-Body Codes Reserved" 10 "B2-Body Codes Reserved" 9 "B1-Body Codes MFG Controlled" 8 "B0-Body Codes SAE Controlled" 7 "C3-Chassis Codes Reserved" 6 "C2-Chassis Codes Reserved" 5 "C1-Chassis Codes MFG Controlled" 4 "C0-Chassis Codes SAE Controlled" 3 "P3-Powertrain Codes Reserved" 2 "P2-Powertrain Codes Reserved" 1 "P1-Powertrain Codes MFG Controlled" 0 "P0-Powertrain Codes SAE Controlled" ;
VAL_TABLE_ EngFuelCntlState 2 "Stoichiometric Closed Loop" 1 "Non-Stoichiometric Closed Loop" 0 "Open Loop" ;
VAL_TABLE_ EngTrqRdFlrSt 4 "Torq Reduction Communication Failed" 3 "Torque Reduction Limited" 2 "Torque Reduction Permanently Failed" 1 "Torque Reduction Temporarily Failed" 0 "Torque Reduction OK" ;
VAL_TABLE_ ParkNeutralSwStat 1 "Not Park/Neutral" 0 "Park/Neutral" ;
VAL_TABLE_ EngBrkStat 2 "Active Absorbing Torque" 1 "Active Not Absorbing Torque" 0 "Inactive" ;
VAL_TABLE_ ETGRReqdGear 8 "Eighth Gear" 7 "Seventh Gear" 6 "Sixth Gear" 5 "Fifth Gear" 4 "Fourth Gear" 3 "Third Gear" 2 "Second Gear" 1 "First Gear" 0 "No Action" ;
VAL_TABLE_ ETGRReqType 0 "No Action" 3 "Hold Gear" 2 "Min Gear Request" 1 "Max Gear Request" ;
VAL_TABLE_ OAT_PT_EstM 1 "Use Data" 0 "Don't Use Data" ;
VAL_TABLE_ ACCompCmnd 1 "On" 0 "Off" ;
VAL_TABLE_ EngEmsRelMalfIndReq 4 "Flashing 0.5 Hertz Indication" 3 "Flashing 2 Hertz Indication" 2 "Flashing 1 Hertz Indication" 1 "No Indication" 0 "Continuous Indication" ;
VAL_TABLE_ EngCylDeactMd 3 "Reactivation In Progress" 2 "Half of Total Cylinders Active" 1 "Deactivation In Progress" 0 "All Cylinders Active" ;
VAL_TABLE_ PltfrmEngSpdCmdInhtRq 1 "Inhibit Platform Eng. Speed Control" 0 "Allow Platform Engine Speed Control" ;
VAL_TABLE_ PT_BrkPedDscrtInpStat 1 "Brake Applied" 0 "Brake Not Applied" ;
VAL_TABLE_ EngSpdStat 3 "Invalid" 1 "Degraded Operation" 0 "Normal Operation" ;
VAL_TABLE_ TrnsCyDactTransStat 2 "Ready for Half of TotalCylinders" 1 "Ready for All Cylinders" 0 "Not Ready" ;
VAL_TABLE_ ACCompSysVDM 1 "Use Data" 0 "Don't Use Data" ;
VAL_TABLE_ BkupPwrModeMstrVDM 1 "Use Data" 0 "Don't Use Data" ;
VAL_TABLE_ PrkBrkVDM 1 "Use Data" 0 "Don't Use Data" ;
VAL_TABLE_ DispMeasSys 1 "English" 0 "Metric" ;
VAL_TABLE_ ACCompModReq 3 "No Action" 2 "Engage" 1 "Disengage" 0 "Disengage Immediately" ;
VAL_TABLE_ TransNtrlCntrlMdStat 3 "Exiting Neutral Control" 2 "Neutral Control Active" 1 "Entering Neutral Control" 0 "Neutral Control Not Active" ;
VAL_TABLE_ TrnsShftLvrPos 15 "Lever Position Unknown" 11 "Forward Range H" 10 "Forward Range G" 9 "Forward Range F" 8 "Forward Range E" 7 "Forward Range D" 6 "Forward Range C" 5 "Forward Range B" 4 "Forward Range A" 3 "Neutral Range" 2 "Reverse Range" 1 "Park Range" 0 "Between Ranges" ;
VAL_TABLE_ TrnsTrqCnvCltCmndMd 7 "Not Supported" 3 "Locked" 2 "Controlled Slip" 1 "Transitioning" 0 "Unlocked" ;
VAL_TABLE_ AutoTransComndGear 15 "Park Gear" 14 "Reverse Gear" 13 "Neutral Gear" 12 "CVT Forward Gear" 11 "EVT Mode 2" 10 "EVT Mode 1" 8 "Eighth Gear" 7 "Seventh Gear" 6 "Sixth Gear" 5 "Fifth Gear" 4 "Fourth Gear" 3 "Third Gear" 2 "Second Gear" 1 "First Gear" 0 "Not Supported" ;
VAL_TABLE_ AutoTransGrSftDirect 2 "Downshift in Progress" 1 "Upshift in Progress" 0 "No Shift in Progress" ;
VAL_TABLE_ TransEstGear 15 "Park Gear" 14 "Reverse Gear" 13 "Neutral Gear" 12 "CVT Forward Gear" 11 "EVT Mode 2" 10 "EVT Mode 1" 8 "Eighth Gear" 7 "Seventh Gear" 6 "Sixth Gear" 5 "Fifth Gear" 4 "Fourth Gear" 3 "Third Gear" 2 "Second Gear" 1 "First Gear" 0 "Not Supported" ;
VAL_TABLE_ TERDTC_SysDes 15 "U3-Network Codes Reserved" 14 "U2-Network Codes Reserved" 13 "U1-Network Codes MFG Controlled" 12 "U0-Network Codes SAE Controlled" 11 "B3-Body Codes Reserved" 10 "B2-Body Codes Reserved" 9 "B1-Body Codes MFG Controlled" 8 "B0-Body Codes SAE Controlled" 7 "C3-Chassis Codes Reserved" 6 "C2-Chassis Codes Reserved" 5 "C1-Chassis Codes MFG Controlled" 4 "C0-Chassis Codes SAE Controlled" 3 "P3-Powertrain Codes Reserved" 2 "P2-Powertrain Codes Reserved" 1 "P1-Powertrain Codes MFG Controlled" 0 "P0-Powertrain Codes SAE Controlled" ;
VAL_TABLE_ TESR_EngSpdCntlRsp 3 "Stability Optimized Condition 2" 2 "Stability Optimized Condition 1" 1 "Transient Optimized" 0 "No Suggestion" ;
VAL_TABLE_ TESR_EngSpdIntTyp 3 "Engine Speed Max and Min Limit" 2 "Engine Speed Min Limit" 1 "Engine Speed Max Limit" 0 "No Intervention" ;
VAL_TABLE_ TTRLT_TqRdnRlznSgg 3 "Stability Optimized 2" 2 "Stability Optimized 1" 1 "Transient Optimized" 0 "No Suggestion" ;
VAL_TABLE_ TTRLT_TorqInvntnTyp 2 "Minimum Limit" 1 "Maximum Limit" 0 "No Intervention" ;
VAL_TABLE_ TTRST_TorqInvntnTyp 1 "Maximum Limit" 0 "No Intervention" ;
VAL_TABLE_ PTORmStMsEngStRq 1 "PTO Remote Start Requested" 0 "PTO Remote Start Not Requested" ;
VAL_TABLE_ PFESpdCmdSwDIntg 2 "Failure Detected" 1 "Data Invalid" 0 "Data Valid" ;
VAL_TABLE_ RmVehStrRq 1 "Remote Start Requested" 0 "Remote Start Not Requested" ;
VAL_TABLE_ VehSpdCntlSystmType 2 "Adaptive Cruise Control" 1 "Conventional Cruise Control" 0 "No Vehicle Speed Control" ;
VAL_TABLE_ PF_MinIdlBstLvlReq 3 "Boost Level 3" 2 "Boost Level 2" 1 "Boost Level 1" 0 "No Boost Requested" ;
VAL_TABLE_ PltfrmEngSpdCmdSysTp 6 "Auto Elevated Idle" 5 "Enhanced Fast Idle" 4 "Fast Idle" 3 "Mobile Variable PTO" 2 "Stationary Variable PTO" 1 "Stationary PTO" 0 "No Platform Eng. Speed Command Sys." ;
VAL_TABLE_ ThrtlPrgrsnReq 2 "Map C" 1 "Map B" 0 "Map A" ;
VAL_TABLE_ PMMAccTrmSt 1 "Active" 0 "Inactive" ;
VAL_TABLE_ PMMRunCrkTrmSt 1 "Active" 0 "Inactive" ;
VAL_TABLE_ SysBkUpPwrMd 3 "Crank Request" 2 "Run" 1 "Accessory" 0 "Off" ;
VAL_TABLE_ SysPwrMd 3 "Crank Request" 2 "Run" 1 "Accessory" 0 "Off" ;
VAL_TABLE_ ImmblzrPreRelPswdStat 1 "Information Valid" 0 "No Information" ;
VAL_TABLE_ AdptCrsGapSwAct 2 "Increase Gap" 1 "Decrease Gap" 0 "No Activation" ;
VAL_TABLE_ CrsCntrlSwStSwDataIntgty 3 "Illegal Range" 2 "Failure Detected" 1 "Data Invalid" 0 "Data Valid" ;
VAL_TABLE_ CrsCntCncRq 1 "Cancel" 0 "Do Not Cancel" ;
VAL_TABLE_ WhlSpdSnsgDTCStat 4 "Diagnostic Failed" 3 "Diagnostic Passed" 2 "No Status to Report" 1 "Critically Disabled" 0 "Not Supported" ;
VAL_TABLE_ SprTireSt 2 "Spare Detected" 1 "No Spare Detected" 0 "Undetermined" ;
VAL_TABLE_ BSTGRReqdGear 8 "Eighth Gear" 7 "Seventh Gear" 6 "Sixth Gear" 5 "Fifth Gear" 4 "Fourth Gear" 3 "Third Gear" 2 "Second Gear" 1 "First Gear" 0 "No Action" ;
VAL_TABLE_ BSTGRReqType 3 "Hold Gear" 2 "Min Gear Request" 1 "Max Gear Request" 0 "No Action" ;
VAL_TABLE_ VhDynCntlSysSt 7 "Driver Disabled" 6 "Enhanced Operation" 5 "Calibrating" 4 "Warming Up" 3 "Permanently Failed" 2 "Temporarily Inhibited" 1 "Reduced Function" 0 "Normal Operation" ;
VAL_TABLE_ TracCntrlSysDrIntnt 1 "Enabled" 0 "Disabled" ;
VAL_TABLE_ ValidityStates 1 "Invalid" 0 "Valid" ;
VAL_TABLE_ MainLghtSw 3 "HEADLAMP" 2 "PARKLAMP" 1 "OFF" 0 "AUTO" ;
VAL_TABLE_ ExhPrsRgVlvPos 1 "Closed" 0 "Open" ;
VAL_TABLE_ CSETRER_TqIntvnTyp 2 "Increase Torque" 1 "Reduce Torque" 0 "No Intervention" ;

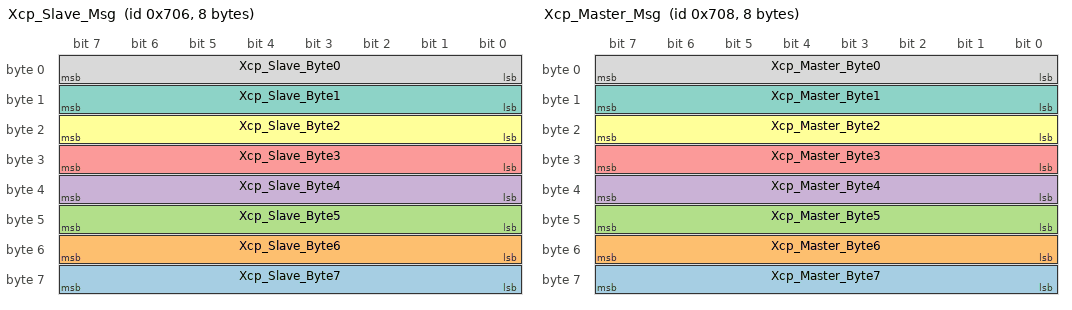
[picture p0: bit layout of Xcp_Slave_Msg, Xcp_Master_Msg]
BO_ 1798 Xcp_Slave_Msg: 8 EPS_HS
 SG_ Xcp_Slave_Byte7 : 63|8@0+ (1,0) [0|255] ""  TestTool_HS
 SG_ Xcp_Slave_Byte6 : 55|8@0+ (1,0) [0|255] ""  TestTool_HS
 SG_ Xcp_Slave_Byte5 : 47|8@0+ (1,0) [0|255] ""  TestTool_HS
 SG_ Xcp_Slave_Byte4 : 39|8@0+ (1,0) [0|255] ""  TestTool_HS
 SG_ Xcp_Slave_Byte3 : 31|8@0+ (1,0) [0|255] ""  TestTool_HS
 SG_ Xcp_Slave_Byte2 : 23|8@0+ (1,0) [0|255] ""  TestTool_HS
 SG_ Xcp_Slave_Byte1 : 15|8@0+ (1,0) [0|255] ""  TestTool_HS
 SG_ Xcp_Slave_Byte0 : 7|8@0+ (1,0) [0|255] ""  TestTool_HS

BO_ 1800 Xcp_Master_Msg: 8 TestTool_HS
 SG_ Xcp_Master_Byte7 : 63|8@0+ (1,0) [0|255] ""  EPS_HS
 SG_ Xcp_Master_Byte6 : 55|8@0+ (1,0) [0|255] ""  EPS_HS
 SG_ Xcp_Master_Byte5 : 47|8@0+ (1,0) [0|255] ""  EPS_HS
 SG_ Xcp_Master_Byte4 : 39|8@0+ (1,0) [0|255] ""  EPS_HS
 SG_ Xcp_Master_Byte3 : 31|8@0+ (1,0) [0|255] ""  EPS_HS
 SG_ Xcp_Master_Byte2 : 23|8@0+ (1,0) [0|0] ""  EPS_HS
 SG_ Xcp_Master_Byte1 : 15|8@0+ (1,0) [0|255] ""  EPS_HS
 SG_ Xcp_Master_Byte0 : 7|8@0+ (1,0) [0|255] ""  EPS_HS

BO_ 1995 T1_HostToTarget: 8 Vector__XXX
 SG_ T1_HostToTarget : 0|64@1- (1,0) [0|0] ""  EPS_HS

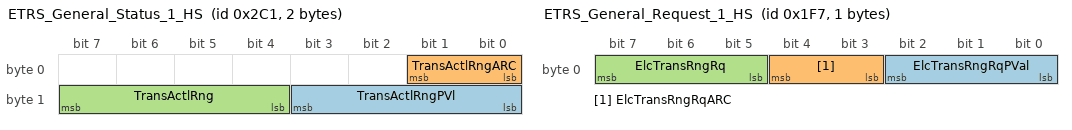
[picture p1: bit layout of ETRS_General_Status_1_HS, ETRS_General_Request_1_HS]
BO_ 705 ETRS_General_Status_1_HS: 2 TCM_HS
 SG_ TransActlRngPVl : 11|4@0+ (1,0) [0|15] ""  ICCM_HS
 SG_ TransActlRngARC : 1|2@0+ (1,0) [0|3] ""  ICCM_HS
 SG_ TransActlRng : 15|4@0+ (1,0) [0|15] ""  ICCM_HS

BO_ 503 ETRS_General_Request_1_HS: 1 ICCM_HS
 SG_ ElcTransRngRqPVal : 2|3@0+ (1,0) [0|7] ""  TRCM_HS,TCM_HS
 SG_ ElcTransRngRqARC : 4|2@0+ (1,0) [0|3] ""  TRCM_HS,TCM_HS
 SG_ ElcTransRngRq : 7|3@0+ (1,0) [0|7] ""  TRCM_HS,TCM_HS

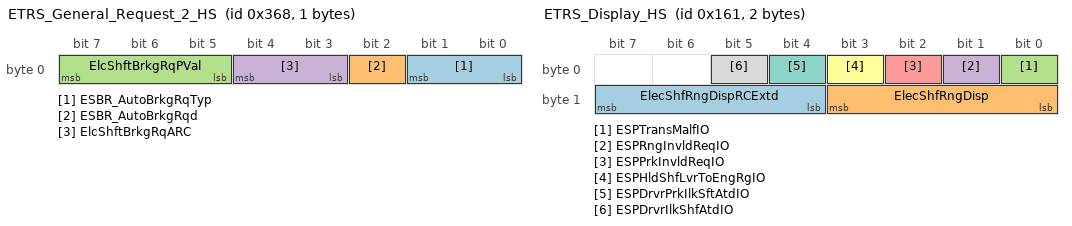
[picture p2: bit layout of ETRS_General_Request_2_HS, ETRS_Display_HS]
BO_ 872 ETRS_General_Request_2_HS: 1 ICCM_HS
 SG_ ESBR_AutoBrkgRqTyp : 1|2@0+ (1,0) [0|3] ""  CGM_HS,EBCM_OBD_HS,EBCM_HS,EPB_HS
 SG_ ESBR_AutoBrkgRqd : 2|1@0+ (1,0) [0|1] ""  CGM_HS,EBCM_OBD_HS,EBCM_HS,EPB_HS
 SG_ ElcShftBrkgRqPVal : 7|3@0+ (1,0) [0|7] ""  EBCM_OBD_HS,EBCM_HS,EPB_HS,CGM_HS
 SG_ ElcShftBrkgRqARC : 4|2@0+ (1,0) [0|3] ""  EBCM_OBD_HS,EBCM_HS,EPB_HS,CGM_HS

BO_ 353 ETRS_Display_HS: 2 ICCM_HS
 SG_ ElecShfRngDispRCExtd : 15|4@0+ (1,0) [0|15] ""  BCM_HS
 SG_ ElecShfRngDisp : 11|4@0+ (1,0) [0|15] ""  BCM_HS
 SG_ ESPTransMalfIO : 0|1@0+ (1,0) [0|1] ""  BCM_HS
 SG_ ESPRngInvldReqIO : 1|1@0+ (1,0) [0|1] ""  BCM_HS
 SG_ ESPPrkInvldReqIO : 2|1@0+ (1,0) [0|1] ""  BCM_HS
 SG_ ESPHldShfLvrToEngRgIO : 3|1@0+ (1,0) [0|1] ""  BCM_HS
 SG_ ESPDrvrPrkIlkSftAtdIO : 4|1@0+ (1,0) [0|1] ""  BCM_HS
 SG_ ESPDrvrIlkShfAtdIO : 5|1@0+ (1,0) [0|1] ""  BCM_HS

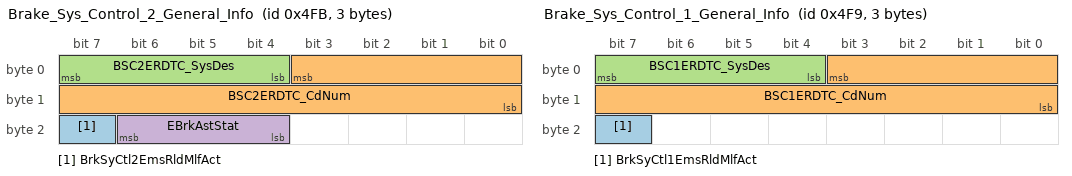
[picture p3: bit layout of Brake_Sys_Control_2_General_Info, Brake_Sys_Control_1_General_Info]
BO_ 1275 Brake_Sys_Control_2_General_Info: 3 EBOOST_HS
 SG_ BrkSyCtl2EmsRldMlfAct : 23|1@0+ (1,0) [0|1] ""  ECM_HS
 SG_ BSC2ERDTC_CdNum : 3|12@0+ (1,0) [0|4095] ""  ECM_HS
 SG_ BSC2ERDTC_SysDes : 7|4@0+ (1,0) [0|15] ""  ECM_HS
 SG_ EBrkAstStat : 22|3@0+ (1,0) [0|7] ""  EBCM_OBD_HS,EBCM_HS

BO_ 1273 Brake_Sys_Control_1_General_Info: 3 EBCM_HS
 SG_ BrkSyCtl1EmsRldMlfAct : 23|1@0+ (1,0) [0|1] ""  ECM_HS
 SG_ BSC1ERDTC_CdNum : 3|12@0+ (1,0) [0|4095] ""  ECM_HS
 SG_ BSC1ERDTC_SysDes : 7|4@0+ (1,0) [0|15] ""  ECM_HS

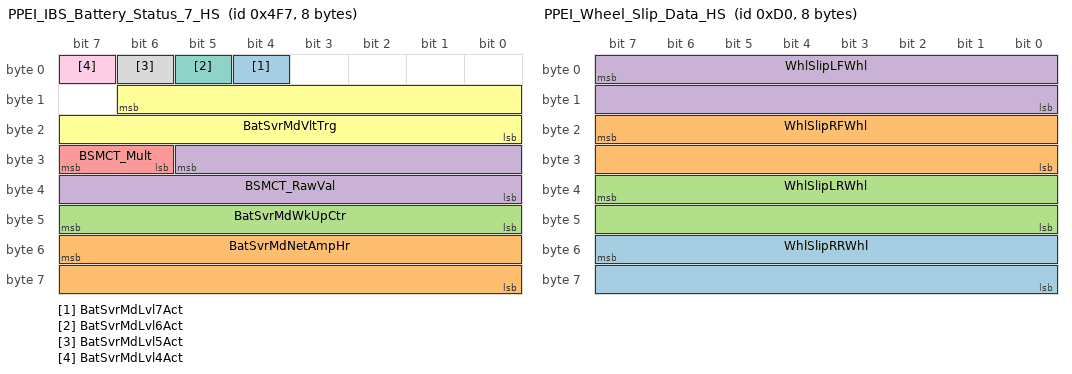
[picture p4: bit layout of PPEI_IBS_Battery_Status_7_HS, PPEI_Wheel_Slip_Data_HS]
BO_ 1271 PPEI_IBS_Battery_Status_7_HS: 8 ECM_HS
 SG_ BatSvrMdLvl7Act : 4|1@0+ (1,0) [0|1] ""  BCM_HS
 SG_ BatSvrMdNetAmpHr : 55|16@0+ (0.01,-327.67) [-327.67|327.68] "AmpHours"  BCM_HS
 SG_ BatSvrMdWkUpCtr : 47|8@0+ (1,0) [0|255] ""  BCM_HS
 SG_ BSMCT_RawVal : 29|14@0+ (0.001,-8.192) [-8.192|8.191] "A"  BCM_HS
 SG_ BSMCT_Mult : 31|2@0+ (1,0) [0|3] ""  BCM_HS
 SG_ BatSvrMdVltTrg : 14|15@0+ (0.001,0) [0|32.767] "V"  BCM_HS
 SG_ BatSvrMdLvl6Act : 5|1@0+ (1,0) [0|1] ""  BCM_HS
 SG_ BatSvrMdLvl5Act : 6|1@0+ (1,0) [0|1] ""  BCM_HS
 SG_ BatSvrMdLvl4Act : 7|1@0+ (1,0) [0|1] ""  BCM_HS

BO_ 558 Air_Cmpresor_Ctrl_Data2_HS: 8 ACCM_HS
 SG_ CmpDataPktARC : 57|2@0+ (1,0) [0|3] "N/A"  BSM_HS,VICM_HS
 SG_ CDP_HVDevShtdnCdARCSt : 49|2@0+ (1,0) [0|3] ""  BSM_HS,VICM_HS
 SG_ CDP_CmpSpdReqARCSt : 51|2@0+ (1,0) [0|3] ""  BSM_HS,VICM_HS
 SG_ CDP_CmpLossCommOcc : 52|1@0+ (1,0) [0|1] ""  BSM_HS,VICM_HS
 SG_ CDP_CmpWkUp : 53|1@0+ (1,0) [0|1] ""  BSM_HS,VICM_HS
 SG_ CDP_CmpRunCrnk : 54|1@0+ (1,0) [0|1] ""  BSM_HS,VICM_HS
 SG_ CmpSnsrDevStPktARC : 5|2@0+ (1,0) [0|3] "N/A"  BSM_HS,VICM_HS
 SG_ CDSP_CmpOvrTmpSt : 11|2@0+ (1,0) [0|3] ""  BSM_HS,VICM_HS
 SG_ CDSP_CmpHVAbnrlOrVltSt : 13|2@0+ (1,0) [0|3] ""  BSM_HS,VICM_HS
 SG_ CDSP_CmpHVUndrVltgSt : 15|2@0+ (1,0) [0|3] ""  BSM_HS,VICM_HS
 SG_ CDSP_CmpHVOvrVltgSt : 1|2@0+ (1,0) [0|3] ""  BSM_HS,VICM_HS
 SG_ CDSP_CmpHVOvrCrntSt : 3|2@0+ (1,0) [0|3] ""  BSM_HS,VICM_HS
 SG_ CDSP_OvrTempWrnInd : 24|1@0+ (1,0) [0|1] ""  BSM_HS,VICM_HS
 SG_ CDSP_CmpDgrdOp : 25|1@0+ (1,0) [0|1] ""  BSM_HS,VICM_HS
 SG_ CDSP_CmpIntShdwnFltSt : 27|2@0+ (1,0) [0|3] ""  BSM_HS,VICM_HS
 SG_ CDSP_CmpIntRecblFltSt : 29|2@0+ (1,0) [0|3] ""  BSM_HS,VICM_HS
 SG_ CDSP_CmpOpOvrldSt : 31|2@0+ (1,0) [0|3] ""  BSM_HS,VICM_HS
 SG_ CDSP_CmpDrCrctFltSt : 17|2@0+ (1,0) [0|3] ""  BSM_HS,VICM_HS
 SG_ CDSP_CmpMtrPerfFltSt : 19|2@0+ (1,0) [0|3] ""  BSM_HS,VICM_HS
 SG_ CDSP_CmpEEPROMFltSt : 21|2@0+ (1,0) [0|3] ""  BSM_HS,VICM_HS
 SG_ CDSP_CmpROMFltSt : 23|2@0+ (1,0) [0|3] ""  BSM_HS,VICM_HS
 SG_ CDSP_CmpRAMFltSt : 9|2@0+ (1,0) [0|3] ""  BSM_HS,VICM_HS
 SG_ CmpSnsrStPktARC : 7|2@0+ (1,0) [0|3] "N/A"  BSM_HS,VICM_HS
 SG_ CSSP_CmpIGBTTpOtRgLSt : 41|2@0+ (1,0) [0|3] ""  BSM_HS,VICM_HS
 SG_ CSSP_CmpIGBTTpOtRgHSt : 43|2@0+ (1,0) [0|3] ""  BSM_HS,VICM_HS
 SG_ CSSP_CmpCPUTmpOtRgLSt : 45|2@0+ (1,0) [0|3] ""  BSM_HS,VICM_HS
 SG_ CSSP_CmpCPUTmpOtRgHSt : 47|2@0+ (1,0) [0|3] ""  BSM_HS,VICM_HS
 SG_ CSSP_CmpHVSnsOtRgLSt : 33|2@0+ (1,0) [0|3] ""  BSM_HS,VICM_HS
 SG_ CSSP_CmpHVSnsOtRgHSt : 35|2@0+ (1,0) [0|3] ""  BSM_HS,VICM_HS
 SG_ CSSP_CmpPhCrntOtRgLSt : 37|2@0+ (1,0) [0|3] ""  BSM_HS,VICM_HS
 SG_ CSSP_CmpPhCrntOtRgHSt : 39|2@0+ (1,0) [0|3] ""  BSM_HS,VICM_HS

BO_ 208 PPEI_Wheel_Slip_Data_HS: 8 EBCM_HS
 SG_ WhlSlipRRWhl : 55|16@0+ (0.390625,-12800) [-12800|12799.609375] "%"  TCM_HS
 SG_ WhlSlipRFWhl : 23|16@0+ (0.390625,-12800) [-12800|12799.609375] "%"  TCM_HS
 SG_ WhlSlipLRWhl : 39|16@0+ (0.390625,-12800) [-12800|12799.609375] "%"  TCM_HS
 SG_ WhlSlipLFWhl : 7|16@0+ (0.390625,-12800) [-12800|12799.609375] "%"  TCM_HS

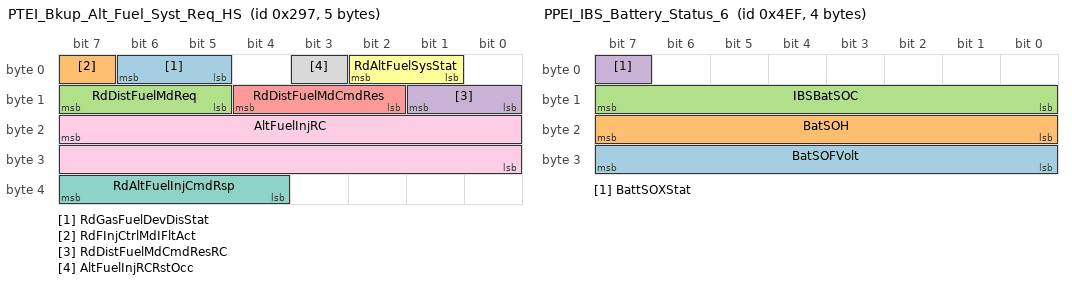
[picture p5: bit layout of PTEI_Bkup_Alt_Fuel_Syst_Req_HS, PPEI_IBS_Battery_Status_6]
BO_ 663 PTEI_Bkup_Alt_Fuel_Syst_Req_HS: 5 FICM_HS
 SG_ RdGasFuelDevDisStat : 6|2@0+ (1,0) [0|3] ""  ECM_HS
 SG_ RdFInjCtrlMdIFltAct : 7|1@0+ (1,0) [0|1] ""  ECM_HS
 SG_ RdDistFuelMdReq : 15|3@0+ (1,0) [0|7] ""  ECM_HS
 SG_ RdDistFuelMdCmdResRC : 9|2@0+ (1,0) [0|3] ""  ECM_HS
 SG_ RdDistFuelMdCmdRes : 12|3@0+ (1,0) [0|7] ""  ECM_HS
 SG_ RdAltFuelSysStat : 2|2@0+ (1,0) [0|3] ""  ECM_HS
 SG_ RdAltFuelInjCmdRsp : 39|4@0+ (1,0) [0|15] ""  ECM_HS
 SG_ AltFuelInjRCRstOcc : 3|1@0+ (1,0) [0|1] ""  ECM_HS
 SG_ AltFuelInjRC : 23|16@0+ (3.0517578125E-005,0) [0|1.99996948242188] "liters"  ECM_HS

BO_ 1263 PPEI_IBS_Battery_Status_6: 4 ECM_HS
 SG_ BatSOFVolt : 31|8@0+ (0.05,0) [0|12.75] "volts"  BCM_HS
 SG_ BatSOH : 23|8@0+ (0.392157,0) [0|100.000035] "%"  BCM_HS
 SG_ IBSBatSOC : 15|8@0+ (0.392157,0) [0|100.000035] "%"  BCM_HS
 SG_ BattSOXStat : 7|1@0+ (1,0) [0|1] ""  BCM_HS

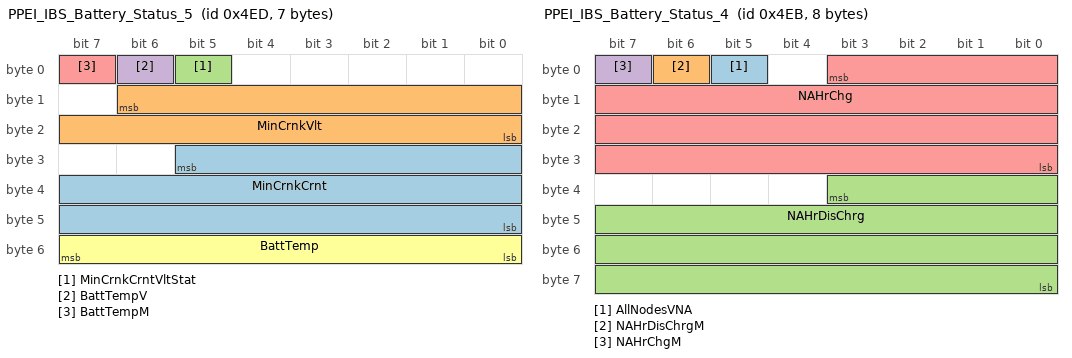
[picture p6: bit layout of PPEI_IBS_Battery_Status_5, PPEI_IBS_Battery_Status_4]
BO_ 1261 PPEI_IBS_Battery_Status_5: 7 ECM_HS
 SG_ MinCrnkCrnt : 29|22@0+ (0.001,-2097.152) [-2097.152|2097.151] "amps"  BCM_HS
 SG_ MinCrnkVlt : 14|15@0+ (0.001,0) [0|32.767] "volts"  BCM_HS
 SG_ MinCrnkCrntVltStat : 5|1@0+ (1,0) [0|1] ""  BCM_HS
 SG_ BattTempV : 6|1@0+ (1,0) [0|1] ""  BCM_HS
 SG_ BattTempM : 7|1@0+ (1,0) [0|1] ""  BCM_HS
 SG_ BattTemp : 55|8@0+ (1,-40) [-40|215] "deg C"  BCM_HS

BO_ 1259 PPEI_IBS_Battery_Status_4: 8 ECM_HS
 SG_ AllNodesVNA : 5|1@0+ (1,0) [0|1] ""  BCM_HS
 SG_ NAHrDisChrgM : 6|1@0+ (1,0) [0|1] ""  BCM_HS
 SG_ NAHrDisChrg : 35|28@0+ (0.001,0) [0|268435.455] "AmpHours"  BCM_HS
 SG_ NAHrChgM : 7|1@0+ (1,0) [0|1] ""  BCM_HS
 SG_ NAHrChg : 3|28@0+ (0.001,0) [0|268435.455] "AmpHours"  BCM_HS

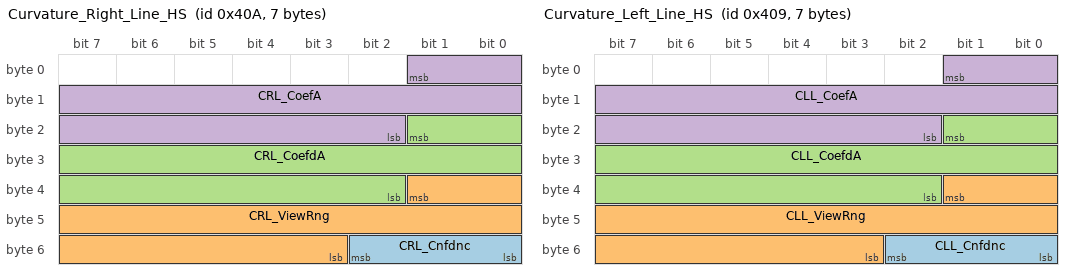
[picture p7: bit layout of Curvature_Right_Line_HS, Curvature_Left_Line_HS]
BO_ 1034 Curvature_Right_Line_HS: 7 EOCM_F_HS
 SG_ CRL_Cnfdnc : 50|3@0+ (1,0) [0|7] ""  EBCM_OBD_HS,EBCM_HS
 SG_ CRL_ViewRng : 33|15@0+ (0.0039064,0) [0|128.0010088] "m"  EBCM_OBD_HS,EBCM_HS
 SG_ CRL_CoefdA : 17|16@0- (3.6622E-009,0) [-0.0001200029696|0.0001199993074] "1/m^2"  EBCM_OBD_HS,EBCM_HS
 SG_ CRL_CoefA : 1|16@0- (6.1036E-007,0) [-0.02000027648|0.01999966612] "1/m"  EBCM_OBD_HS,EBCM_HS

BO_ 1033 Curvature_Left_Line_HS: 7 EOCM_F_HS
 SG_ CLL_Cnfdnc : 50|3@0+ (1,0) [0|7] ""  EBCM_OBD_HS,EBCM_HS
 SG_ CLL_ViewRng : 33|15@0+ (0.0039064,0) [0|128.0010088] "m"  EBCM_OBD_HS,EBCM_HS
 SG_ CLL_CoefdA : 17|16@0- (3.6622E-009,0) [-0.0001200029696|0.0001199993074] "1/m^2"  EBCM_OBD_HS,EBCM_HS
 SG_ CLL_CoefA : 1|16@0- (6.1036E-007,0) [-0.02000027648|0.01999966612] "1/m"  EBCM_OBD_HS,EBCM_HS

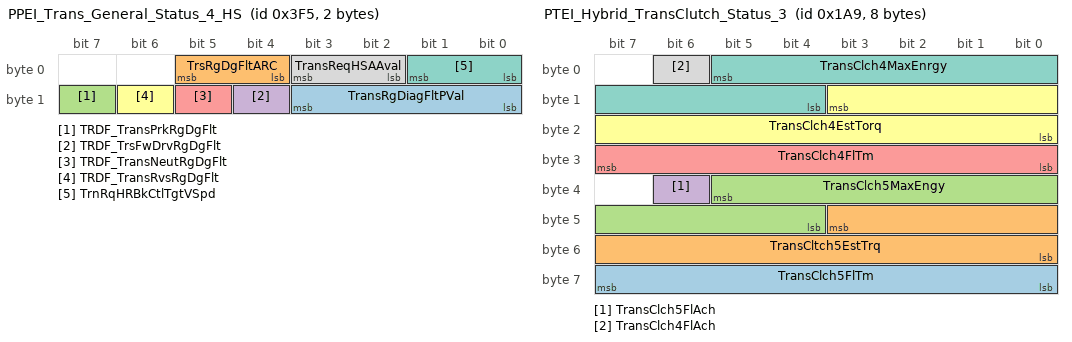
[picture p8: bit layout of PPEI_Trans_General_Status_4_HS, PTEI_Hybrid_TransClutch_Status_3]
BO_ 1013 PPEI_Trans_General_Status_4_HS: 2 TCM_HS
 SG_ TransRgDiagFltPVal : 11|4@0+ (1,0) [0|15] ""  ICCM_HS
 SG_ TrsRgDgFltARC : 5|2@0+ (1,0) [0|3] ""  ICCM_HS
 SG_ TRDF_TransPrkRgDgFlt : 15|1@0+ (1,0) [0|1] ""  ICCM_HS
 SG_ TRDF_TrsFwDrvRgDgFlt : 12|1@0+ (1,0) [0|1] ""  ICCM_HS
 SG_ TRDF_TransNeutRgDgFlt : 13|1@0+ (1,0) [0|1] ""  ICCM_HS
 SG_ TRDF_TransRvsRgDgFlt : 14|1@0+ (1,0) [0|1] ""  ICCM_HS
 SG_ TrnRqHRBkCtlTgtVSpd : 1|2@0+ (1,0) [0|3] ""  EBCM_OBD_HS,EBCM_HS
 SG_ TransReqHSAAval : 3|2@0+ (1,0) [0|3] ""  EBCM_OBD_HS,EBCM_HS

BO_ 425 PTEI_Hybrid_TransClutch_Status_3: 8 TCM_HS
 SG_ TransClch5FlTm : 63|8@0+ (0.0125,0) [0|3.1875] "s"  HCP_HS
 SG_ TransCltch5EstTrq : 43|12@0+ (0.5,-5) [-5|2042.5] "Nm"  HCP_HS
 SG_ TransClch5MaxEngy : 37|10@0+ (50,0) [0|51150] "J"  HCP_HS
 SG_ TransClch5FlAch : 38|1@0+ (1,0) [0|1] ""  HCP_HS
 SG_ TransClch4FlTm : 31|8@0+ (0.0125,0) [0|3.1875] "s"  HCP_HS
 SG_ TransClch4EstTorq : 11|12@0+ (0.5,-5) [-5|2042.5] "Nm"  HCP_HS
 SG_ TransClch4MaxEnrgy : 5|10@0+ (50,0) [0|51150] "J"  HCP_HS
 SG_ TransClch4FlAch : 6|1@0+ (1,0) [0|1] ""  HCP_HS

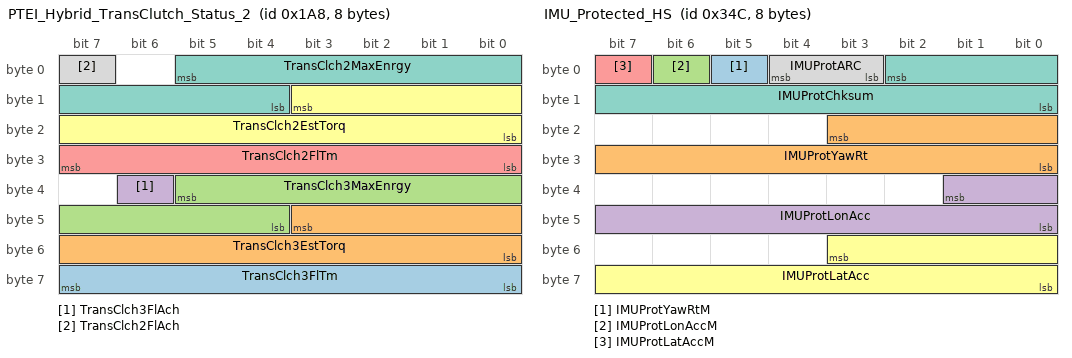
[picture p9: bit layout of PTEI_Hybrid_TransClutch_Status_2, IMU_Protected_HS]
BO_ 424 PTEI_Hybrid_TransClutch_Status_2: 8 TCM_HS
 SG_ TransClch3FlTm : 63|8@0+ (0.0125,0) [0|3.1875] "s"  HCP_HS
 SG_ TransClch3EstTorq : 43|12@0+ (0.5,-5) [-5|2042.5] "Nm"  HCP_HS
 SG_ TransClch3MaxEnrgy : 37|10@0+ (50,0) [0|51150] "J"  HCP_HS
 SG_ TransClch3FlAch : 38|1@0+ (1,0) [0|1] ""  HCP_HS
 SG_ TransClch2FlTm : 31|8@0+ (0.0125,0) [0|3.1875] "s"  HCP_HS
 SG_ TransClch2EstTorq : 11|12@0+ (0.5,-5) [-5|2042.5] "Nm"  HCP_HS
 SG_ TransClch2MaxEnrgy : 5|10@0+ (50,0) [0|51150] "J"  HCP_HS
 SG_ TransClch2FlAch : 7|1@0+ (1,0) [0|1] ""  HCP_HS

BO_ 324 Active_Vbn_CntrlMalfunctn_Ind_HS: 1 AVM_HS
 SG_ ActVbnCtrlMlfIO : 0|1@0+ (1,0) [0|1] ""  BCM_HS

BO_ 844 IMU_Protected_HS: 8 EBCM_HS
 SG_ IMUProtYawRtM : 5|1@0+ (1,0) [0|1] ""  CGM_HS,FCM_HS,EPS_HS
 SG_ IMUProtYawRt : 19|12@0- (0.0625,0) [-128|127.9375] "deg/sec"  CGM_HS,FCM_HS,EPS_HS
 SG_ IMUProtLonAccM : 6|1@0+ (1,0) [0|1] ""  CGM_HS,FCM_HS,EPS_HS
 SG_ IMUProtLonAcc : 33|10@0- (0.03,0) [-15.36|15.33] "m/s^2"  CGM_HS,FCM_HS,EPS_HS
 SG_ IMUProtLatAccM : 7|1@0+ (1,0) [0|1] ""  CGM_HS,FCM_HS,EPS_HS
 SG_ IMUProtLatAcc : 51|12@0- (0.015625,0) [-32|31.984375] "m/s^2"  CGM_HS,FCM_HS,EPS_HS
 SG_ IMUProtChksum : 2|11@0+ (1,0) [0|2047] ""  CGM_HS,FCM_HS,EPS_HS
 SG_ IMUProtARC : 4|2@0+ (1,0) [0|3] ""  CGM_HS,FCM_HS,EPS_HS

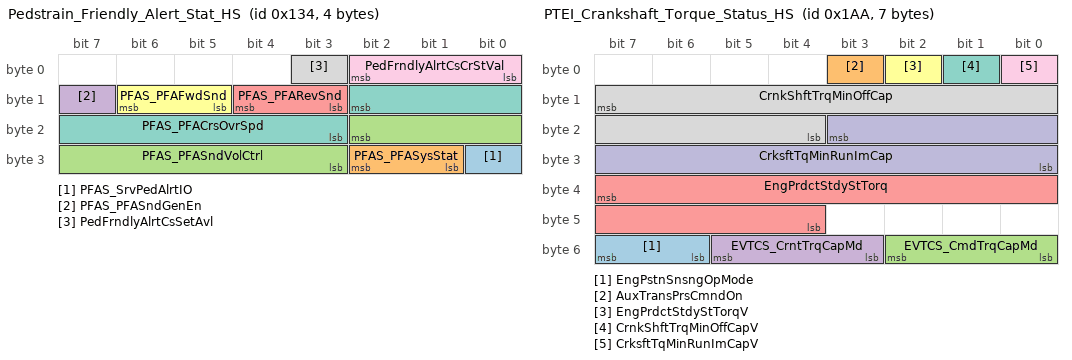
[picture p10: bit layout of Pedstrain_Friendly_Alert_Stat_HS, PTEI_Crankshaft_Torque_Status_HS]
BO_ 308 Pedstrain_Friendly_Alert_Stat_HS: 4 PFAF_HS
 SG_ PFAS_SrvPedAlrtIO : 24|1@0+ (1,0) [0|1] ""  BCM_HS
 SG_ PFAS_PFASysStat : 26|2@0+ (1,0) [0|3] ""  BCM_HS
 SG_ PFAS_PFASndVolCtrl : 18|8@0+ (0.392157,0) [0|100.000035] "%"  BCM_HS
 SG_ PFAS_PFASndGenEn : 15|1@0+ (1,0) [0|1] ""  BCM_HS
 SG_ PFAS_PFARevSnd : 12|2@0+ (1,0) [0|3] ""  BCM_HS
 SG_ PFAS_PFAFwdSnd : 14|2@0+ (1,0) [0|3] ""  BCM_HS
 SG_ PFAS_PFACrsOvrSpd : 10|8@0+ (1,0) [0|255] "km/h"  BCM_HS
 SG_ PedFrndlyAlrtCsSetAvl : 3|1@0+ (1,0) [0|1] ""  BCM_HS
 SG_ PedFrndlyAlrtCsCrStVal : 2|3@0+ (1,0) [0|7] ""  BCM_HS

BO_ 806 DC_Converter_Stabilization_HS: 1 DCDC_HS
 SG_ DCCnvStblznErrIO : 0|1@0+ (1,0) [0|1] ""  BCM_HS

BO_ 426 PTEI_Crankshaft_Torque_Status_HS: 7 ECM_HS
 SG_ EngPstnSnsngOpMode : 55|2@0+ (1,0) [0|3] ""  HCP_T_HS,HCP_HS,HCP_B_HS
 SG_ AuxTransPrsCmndOn : 3|1@0+ (1,0) [0|1] ""  TCM_HS
 SG_ EVTCS_CmdTrqCapMd : 50|3@0+ (1,0) [0|7] ""  HCP_T_HS,TCM_HS,HCP_HS,HCP_B_HS
 SG_ EVTCS_CrntTrqCapMd : 53|3@0+ (1,0) [0|7] ""  HCP_T_HS,TCM_HS,HCP_HS,HCP_B_HS
 SG_ EngPrdctStdyStTorq : 39|12@0+ (0.5,-848) [-848|1199.5] "Nm"  TCM_HS
 SG_ EngPrdctStdyStTorqV : 2|1@0+ (1,0) [0|1] ""  TCM_HS
 SG_ CrnkShftTrqMinOffCapV : 1|1@0+ (1,0) [0|1] ""  TCM_HS
 SG_ CrnkShftTrqMinOffCap : 15|12@0+ (0.5,-848) [-848|1199.5] "Nm"  TCM_HS
 SG_ CrksftTqMinRunImCapV : 0|1@0+ (1,0) [0|1] ""  TCM_HS
 SG_ CrksftTqMinRunImCap : 19|12@0+ (0.5,-848) [-848|1199.5] "Nm"  TCM_HS

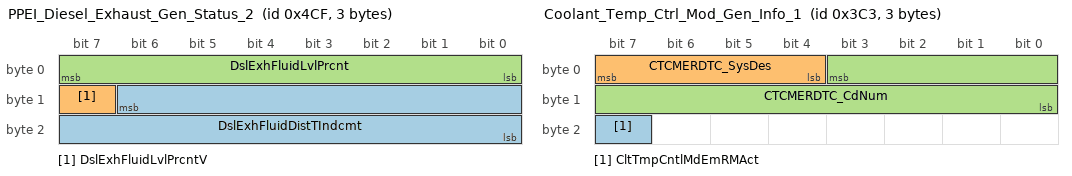
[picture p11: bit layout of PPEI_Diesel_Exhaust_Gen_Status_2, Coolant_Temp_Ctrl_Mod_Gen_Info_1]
BO_ 1231 PPEI_Diesel_Exhaust_Gen_Status_2: 3 ECM_HS
 SG_ DslExhFluidDistTIndcmt : 14|15@0+ (2,0) [0|65534] "km"  BCM_HS
 SG_ DslExhFluidLvlPrcntV : 15|1@0+ (1,0) [0|1] ""  BCM_HS
 SG_ DslExhFluidLvlPrcnt : 7|8@0+ (0.392157,0) [0|100.000035] "%"  BCM_HS

BO_ 963 Coolant_Temp_Ctrl_Mod_Gen_Info_1: 3 VICM2_HS
 SG_ CltTmpCntlMdEmRMAct : 23|1@0+ (1,0) [0|1] ""  ECM_HS
 SG_ CTCMERDTC_SysDes : 7|4@0+ (1,0) [0|15] ""  ECM_HS
 SG_ CTCMERDTC_CdNum : 3|12@0+ (1,0) [0|4095] ""  ECM_HS

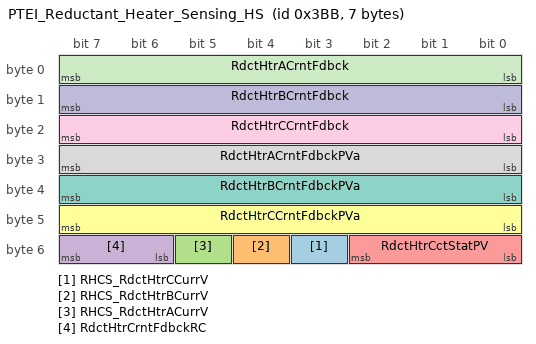
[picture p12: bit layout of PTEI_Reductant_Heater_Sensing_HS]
BO_ 955 PTEI_Reductant_Heater_Sensing_HS: 7 GPCM_HS
 SG_ RHCS_RdctHtrCCurrV : 51|1@0+ (1,0) [0|1] ""  ECM_HS
 SG_ RHCS_RdctHtrBCurrV : 52|1@0+ (1,0) [0|1] ""  ECM_HS
 SG_ RHCS_RdctHtrACurrV : 53|1@0+ (1,0) [0|1] ""  ECM_HS
 SG_ RdctHtrCrntFdbckRC : 55|2@0+ (1,0) [0|3] ""  ECM_HS
 SG_ RdctHtrCctStatPV : 50|3@0+ (1,0) [0|7] ""  ECM_HS
 SG_ RdctHtrCCrntFdbckPVa : 47|8@0+ (1,0) [0|255] ""  ECM_HS
 SG_ RdctHtrBCrntFdbckPVa : 39|8@0+ (1,0) [0|255] ""  ECM_HS
 SG_ RdctHtrACrntFdbckPVa : 31|8@0+ (1,0) [0|255] ""  ECM_HS
 SG_ RdctHtrCCrntFdbck : 23|8@0+ (0.117647,0) [0|29.999985] "A"  ECM_HS
 SG_ RdctHtrBCrntFdbck : 15|8@0+ (0.117647,0) [0|29.999985] "A"  ECM_HS
 SG_ RdctHtrACrntFdbck : 7|8@0+ (0.117647,0) [0|29.999985] "A"  ECM_HS

BO_ 423 PTEI_Hybrid_TransClutch_Status_1: 8 TCM_HS
 SG_ TrnsInpDvcStat : 38|3@0+ (1,0) [0|7] ""  HCP_HS
 SG_ TrnsPTSysShtdwnRq : 39|1@0+ (1,0) [0|1] ""  HCP_HS
 SG_ TransClch1FlTm : 31|8@0+ (0.0125,0) [0|3.1875] "s"  HCP_HS
 SG_ TransClch1EstTorq : 11|12@0+ (0.5,-5) [-5|2042.5] "Nm"  HCP_HS
 SG_ TransClch1MaxEnrgy : 5|10@0+ (50,0) [0|51150] "J"  HCP_HS
 SG_ TransClch1FlAch : 6|1@0+ (1,0) [0|1] ""  HCP_HS
 SG_ TransHydrlcDfltgAct : 7|1@0+ (1,0) [0|1] ""  HCP_HS
 SG_ TCFS_Cltch5FltStat : 58|3@0+ (1,0) [0|7] ""  HCP_HS
 SG_ TCFS_Cltch4FltStat : 61|3@0+ (1,0) [0|7] ""  HCP_HS
 SG_ TCFS_Cltch3FltStat : 48|3@0+ (1,0) [0|7] ""  HCP_HS
 SG_ TCFS_Cltch2FltStat : 51|3@0+ (1,0) [0|7] ""  HCP_HS
 SG_ TCFS_Cltch1FltStat : 54|3@0+ (1,0) [0|7] ""  HCP_HS
 SG_ TCAS_Cltch5AvlbltyStat : 41|2@0+ (1,0) [0|3] ""  HCP_HS
 SG_ TCAS_Cltch4AvlbltyStat : 43|2@0+ (1,0) [0|3] ""  HCP_HS
 SG_ TCAS_Cltch3AvlbltyStat : 45|2@0+ (1,0) [0|3] ""  HCP_HS
 SG_ TCAS_Cltch2AvlbltyStat : 47|2@0+ (1,0) [0|3] ""  HCP_HS
 SG_ TCAS_Cltch1AvlbltyStat : 33|2@0+ (1,0) [0|3] ""  HCP_HS

BO_ 2034 CCP_Data_Transmission_Object_HS: 8 PTO_HS
 SG_ DgnInf : 7|64@0+ (1,0) [0|1.84467440737096E+019] ""  TestTool_HS

BO_ 2032 CCP_Command_Receive_Object_HS: 8 TestTool_HS
 SG_ DgnInf : 7|64@0+ (1,0) [0|1.84467440737096E+019] ""  FCM_HS,PTO_HS

BO_TX_BU_ 1273 : EBCM_OBD_HS,EBCM_HS;
BO_TX_BU_ 208 : EBCM_OBD_HS,EBCM_HS;
BO_TX_BU_ 1034 : CGM_HS,FCM_HS,EOCM_F_HS;
BO_TX_BU_ 1033 : CGM_HS,FCM_HS,EOCM_F_HS;
BO_TX_BU_ 1013 : HCP_T_HS,TCM_HS;
BO_TX_BU_ 844 : EBCM_OBD_HS,EBCM_HS;
BO_TX_BU_ 308 : CGM_HS,PFAF_HS;
BO_TX_BU_ 2034 : FCM_HS,PTO_HS;

CM_ "Primary High Speed GMLAN
HS bus is affected in Version 17.17.107  [Lakshmi Udaya,13 Sept 2013]";
CM_ BU_ EBOOST_HS "Electric Brake Booster";
CM_ BU_ CGM_HS "Communication Gateway";
CM_ BU_ BSM_HS "Battery State Manager";
CM_ BU_ HCP_B_HS "Hybrid Control Processor for BAS";
CM_ BU_ AVM_HS "Active Vibration Module";
CM_ BU_ PFAF_HS "Pedestrian Friendly Alert Function";
CM_ BU_ LVMPC_HS "Low Volume Module (Performance Computer )";
CM_ BU_ DCDC_HS "DC/DC Converter";
CM_ BU_ TRCM_HS "Transmission Range Control Module";
CM_ BU_ AMP_HS "Audio Amplifier";
CM_ BU_ VICM2_HS "Vehicle Integration Control Module 2 (CTCM - Coolant Temperature Control Module)";
CM_ BU_ FICM_HS "Fuel Injection Control Module";
CM_ BU_ ARS_HS "Active Rear Steering";
CM_ BU_ MCP_B_HS "Motor Control Processor B(part of TPIM-Traction Powertrain Inverter Module)";
CM_ BU_ MCP_A_HS "Motor Control Processor A(part of TPIM-Traction Powertrain Inverter Module)";
CM_ BU_ ICCM_OBD_HS "Integrated Chassis Control Module";
CM_ BU_ SAS_HS "Steering Angle Sensor";
CM_ BU_ ACCM_HS "Air Conditioning Control Module";
CM_ BU_ VLBS_HS "Vehicle Location & Blocking System";
CM_ BU_ EBCM_OBD_HS "Electronic Brake Control Module";
CM_ BU_ HCP_T_HS "Hybrid Control Processor with up-integrated Trans and Motor Controls";
CM_ BU_ EDI_HS "Enhanced Driver Interface";
CM_ BU_ HPCC_HS "High Power Charging Contactor";
CM_ BU_ VITM_OBD_HS "Voltage, Current, Temperature Module BAS+";
CM_ BU_ VICM_HS "Vehicle Integration Control Module 4Mode";
CM_ BU_ HCP_HS "Hybrid Control Processor";
CM_ BU_ APPS_HS "Active Pedestrian Protection System";
CM_ BU_ ICCM_HS "Integrated Chassis Control Module";
CM_ BU_ EOCM_F_HS "External Object Control Module - Front";
CM_ BU_ GPCM_HS "Glow Plug Control Module";
CM_ BU_ VCM_HS "Vaporizer Control Module";
CM_ BU_ HMIM_HS "Next-Gen Infotainment HMIModule ";
CM_ BU_ VES_HS "Variable Effort Steering";
CM_ BU_ Dummy_HS "This is for avoid signle ended signalling";
CM_ BU_ MCP_C_HS "Motor control processor C";
CM_ BU_ ONSTAR_HS "OnStar Module";
CM_ BU_ EPS_HS "Electronic Power Steering";
CM_ BU_ MCP_HS "Motor Control Processor";
CM_ BU_ BCP_HS "BAS+";
CM_ BU_ ALC_HS "Automatic Level Control";
CM_ BU_ AHL_AFL_HS "Automatic Headlamp Levelling";
CM_ BU_ SADS_HS "Semi Active Damping System";
CM_ BU_ EPB_HS "Electronic Park Brake";
CM_ BU_ FCM_HS "Front Camera Module";
CM_ BU_ TCCM_HS "Transfer Case Control Module";
CM_ BU_ RDCM_HS "Rear Drive Control Module";
CM_ BU_ PTO_HS "Power TakeOff Module";
CM_ BU_ EBCM_HS "Electronic Brake Control Module";
CM_ BU_ ACC_HS "Adaptive Cruise Control";
CM_ BU_ BCM_HS "HS Side Global Architecture Gateway and Body Control Module";
CM_ BU_ TCM_HS "Transmission Control Module";
CM_ BU_ ECM_HS "Engine Control Module";
CM_ SG_ 1263 BatSOH "State of Health = the aging state of the Battery";
BA_DEF_  "BusType" STRING ;
BA_DEF_ SG_  "VNSigSLHS_VNReq" ENUM  "No","Yes";
BA_DEF_ SG_  "VNSigSLHSSharedDiagnostic" ENUM  "No","Yes";
BA_DEF_ SG_  "SignalType" STRING ;
BA_DEF_ SG_  "PacketOrder" INT 0 65535;
BA_DEF_ SG_  "SignalLongName" STRING ;
BA_DEF_ SG_  "GenSigStartValue" INT 0 65535;
BA_DEF_ SG_  "VNSigAllNodes" ENUM  "No","Yes";
BA_DEF_ SG_  "GenSigDeltaValue" INT 0 0;
BA_DEF_ SG_  "GenSigSendType" ENUM  "not used","not used","not used","not used","not used","not used","not used","NoSigSendType","not used","not used","OnAnyChange","OnChangeIfActive","OnDelta";
BA_DEF_ SG_  "GenSigSendOnInit" ENUM  "Not Initialized","Application","Handler";
BA_DEF_ BO_  "AppGenMsgCycleTime" INT 0 0;
BA_DEF_ BO_  "GenMsgILSupport" ENUM  "No","Yes";
BA_DEF_ BO_  "TpApplType" STRING ;
BA_DEF_ BO_  "Prio" INT 0 7;
BA_DEF_ BO_  "MessageSubnet" ENUM  "LS","MS","HS","CE","PE","HV","FO","S1","HE","LE","HE2";
BA_DEF_ BO_  "DiagState" ENUM  "No","Yes";
BA_DEF_ BO_  "GenMsgStartDelayTime" INT 0 100000;
BA_DEF_ BO_  "GenMsgDelayTime" INT 0 100000;
BA_DEF_ BO_  "GenMsgCycleTime" INT 0 100000;
BA_DEF_ BO_  "GenMsgSendType" ENUM  "cyclicX","spontanX","cyclicIfActiveX","spontanWithDelay","cyclicAndSpontanX","cyclicAndSpontanWithDelay","spontanWithRepitition","cyclicIfActiveAndSpontanWD";
BA_DEF_ BO_  "DiagResponse" ENUM  "No","Yes";
BA_DEF_ BO_  "DiagRequest" ENUM  "No","Yes";
BA_DEF_ BO_  "NmMessage" ENUM  "No","Yes";
BA_DEF_ BU_  "MessageManagerUsed" ENUM  "No","Yes";
BA_DEF_ BU_  "NmNode" ENUM  "No","Yes";
BA_DEF_ BU_  "ILUsed" ENUM  "No","Yes";
BA_DEF_ BU_  "NodeLayerModules" STRING ;
BA_DEF_ BU_  "VNECUSLHS_VNReq" ENUM  "None","Activator","Remoted","Activator and Remoted","Shared Local";
BA_DEF_ BU_  "VNECUSLHSSharedDiagnostic" ENUM  "None","Activator","Remoted","Activator and Remoted","Shared Local";
BA_DEF_ BU_  "VNECUAllNodes" ENUM  "None","Activator","Remoted","Activator and Remoted","Shared Local";
BA_DEF_ BU_  "ECU_Id" HEX 0 255;
BA_DEF_ BU_  "SourceId" HEX 0 253;
BA_DEF_  "SyncJumpWidthMax" INT 0 255;
BA_DEF_  "SyncJumpWidthMin" INT 0 255;
BA_DEF_  "SamplePointMax" FLOAT 0 100;
BA_DEF_  "SamplePointMin" FLOAT 0 100;
BA_DEF_  "Baudrate" INT 0 1000000;
BA_DEF_  "VehicleArchitecture" STRING ;
BA_DEF_  "VNInitActSLHS_VNReq" ENUM  "No","Yes";
BA_DEF_  "VN_SLHS_VNReq" INT 0 255;
BA_DEF_  "VNInitActSLHSSharedDiagnostic" ENUM  "No","Yes";
BA_DEF_  "VN_SLHSSharedDiagnostic" INT 0 255;
BA_DEF_  "NmMessageCount" INT 0 32;
BA_DEF_  "NmBaseAddress" HEX 0 2032;
BA_DEF_  "NetworkType" STRING ;
BA_DEF_  "VNMFPeriodicInterval" INT 0 65535;
BA_DEF_  "BusWakeUpDelay" INT 0 65535;
BA_DEF_  "BusOffRecoveryTime" INT 0 65535;
BA_DEF_  "NodeStatusMsgID" HEX 0 536870911;
BA_DEF_  "NodeStatusMsgCycleTime" INT 0 65535;
BA_DEF_  "NodeStatusMsgTimeoutTime" INT 0 65535;
BA_DEF_  "UseGMParameterIDs" INT 0 1;
BA_DEF_  "VersionWeek" INT 0 255;
BA_DEF_  "VersionYear" INT 0 255;
BA_DEF_  "VN_AllNodes" INT 0 255;
BA_DEF_  "Manufacturer" ENUM  "DBAG","VAG","BMW","PAG","GM";
BA_DEF_  "NmType" STRING ;
BA_DEF_REL_ BU_SG_REL_  "GenSigSuprvRespComment" STRING ;
BA_DEF_REL_ BU_SG_REL_  "GenSigVBitResp" ENUM  "No","Yes";
BA_DEF_REL_ BU_SG_REL_  "GenSigVBitRespComment" STRING ;
BA_DEF_REL_ BU_SG_REL_  "GenSigVDAFailComment" STRING ;
BA_DEF_REL_ BU_SG_REL_  "GenSigVDAFailResp" ENUM  "No","Yes";
BA_DEF_REL_ BU_SG_REL_  "GenSigRxStartValue" STRING ;
BA_DEF_REL_ BU_SG_REL_  "GenSigSuprvRespSubValue" INT 0 65535;
BA_DEF_REL_ BU_SG_REL_  "GenSigSuprvResp" ENUM  "None","Notify App","Substitute Default";
BA_DEF_REL_ BU_SG_REL_  "GenSigTimeoutMsg" HEX -2147483648 268435455;
BA_DEF_REL_ BU_SG_REL_  "GenSigTimeoutTime" INT 0 15000;
BA_DEF_DEF_  "BusType" "";
BA_DEF_DEF_  "VNSigSLHS_VNReq" "No";
BA_DEF_DEF_  "VNSigSLHSSharedDiagnostic" "No";
BA_DEF_DEF_  "SignalType" "";
BA_DEF_DEF_  "PacketOrder" 0;
BA_DEF_DEF_  "SignalLongName" "";
BA_DEF_DEF_  "GenSigStartValue" 0;
BA_DEF_DEF_  "VNSigAllNodes" "No";
BA_DEF_DEF_  "GenSigDeltaValue" 0;
BA_DEF_DEF_  "GenSigSendType" "NoSigSendType";
BA_DEF_DEF_  "GenSigSendOnInit" "Not Initialized";
BA_DEF_DEF_  "AppGenMsgCycleTime" 0;
BA_DEF_DEF_  "GenMsgILSupport" "Yes";
BA_DEF_DEF_  "TpApplType" "";
BA_DEF_DEF_  "Prio" 4;
BA_DEF_DEF_  "MessageSubnet" "FO";
BA_DEF_DEF_  "DiagState" "No";
BA_DEF_DEF_  "GenMsgStartDelayTime" 0;
BA_DEF_DEF_  "GenMsgDelayTime" 0;
BA_DEF_DEF_  "GenMsgCycleTime" 0;
BA_DEF_DEF_  "GenMsgSendType" "spontanX";
BA_DEF_DEF_  "DiagResponse" "No";
BA_DEF_DEF_  "DiagRequest" "No";
BA_DEF_DEF_  "NmMessage" "No";
BA_DEF_DEF_  "MessageManagerUsed" "Yes";
BA_DEF_DEF_  "NmNode" "Yes";
BA_DEF_DEF_  "ILUsed" "Yes";
BA_DEF_DEF_  "NodeLayerModules" "gmlan02.dll";
BA_DEF_DEF_  "VNECUSLHS_VNReq" "None";
BA_DEF_DEF_  "VNECUSLHSSharedDiagnostic" "None";
BA_DEF_DEF_  "VNECUAllNodes" "None";
BA_DEF_DEF_  "ECU_Id" 0;
BA_DEF_DEF_  "SourceId" 0;
BA_DEF_DEF_  "SyncJumpWidthMax" 0;
BA_DEF_DEF_  "SyncJumpWidthMin" 0;
BA_DEF_DEF_  "SamplePointMax" 0;
BA_DEF_DEF_  "SamplePointMin" 0;
BA_DEF_DEF_  "Baudrate" 0;
BA_DEF_DEF_  "VehicleArchitecture" "";
BA_DEF_DEF_  "VNInitActSLHS_VNReq" "No";
BA_DEF_DEF_  "VN_SLHS_VNReq" 2;
BA_DEF_DEF_  "VNInitActSLHSSharedDiagnostic" "No";
BA_DEF_DEF_  "VN_SLHSSharedDiagnostic" 0;
BA_DEF_DEF_  "NmMessageCount" 32;
BA_DEF_DEF_  "NmBaseAddress" 1568;
BA_DEF_DEF_  "NetworkType" "";
BA_DEF_DEF_  "VNMFPeriodicInterval" 3000;
BA_DEF_DEF_  "BusWakeUpDelay" 100;
BA_DEF_DEF_  "BusOffRecoveryTime" 0;
BA_DEF_DEF_  "NodeStatusMsgID" 268427264;
BA_DEF_DEF_  "NodeStatusMsgCycleTime" 1200;
BA_DEF_DEF_  "NodeStatusMsgTimeoutTime" 0;
BA_DEF_DEF_  "UseGMParameterIDs" 1;
BA_DEF_DEF_  "VersionWeek" 0;
BA_DEF_DEF_  "VersionYear" 0;
BA_DEF_DEF_  "VN_AllNodes" 1;
BA_DEF_DEF_  "Manufacturer" "GM";
BA_DEF_DEF_  "NmType" "GMLAN";
BA_DEF_DEF_REL_ "GenSigSuprvRespComment" "";
BA_DEF_DEF_REL_ "GenSigVBitResp" "No";
BA_DEF_DEF_REL_ "GenSigVBitRespComment" "";
BA_DEF_DEF_REL_ "GenSigVDAFailComment" "";
BA_DEF_DEF_REL_ "GenSigVDAFailResp" "No";
BA_DEF_DEF_REL_ "GenSigRxStartValue" "";
BA_DEF_DEF_REL_ "GenSigSuprvRespSubValue" 0;
BA_DEF_DEF_REL_ "GenSigSuprvResp" "None";
BA_DEF_DEF_REL_ "GenSigTimeoutMsg" 0;
BA_DEF_DEF_REL_ "GenSigTimeoutTime" 0;
BA_ "SyncJumpWidthMax" 4;
BA_ "SyncJumpWidthMin" 3;
BA_ "SamplePointMax" 81.25;
BA_ "SamplePointMin" 80;
BA_ "Baudrate" 500000;
BA_ "VehicleArchitecture" "Global A";
BA_ "VNInitActSLHS_VNReq" 1;
BA_ "VNInitActSLHSSharedDiagnostic" 1;
BA_ "NmMessageCount" 16;
BA_ "NmBaseAddress" 1536;
BA_ "NetworkType" "Powertrain";
BA_ "BusOffRecoveryTime" 160;
BA_ "NodeStatusMsgID" 0;
BA_ "UseGMParameterIDs" 0;
BA_ "VersionWeek" 107;
BA_ "VersionYear" 17;
BA_ "BusType" "CAN";
BA_ "VNECUSLHS_VNReq" BU_ EBOOST_HS 4;
BA_ "VNECUSLHSSharedDiagnostic" BU_ EBOOST_HS 4;
BA_ "VNECUAllNodes" BU_ EBOOST_HS 4;
BA_ "ECU_Id" BU_ EBOOST_HS 230;
BA_ "SourceId" BU_ EBOOST_HS 43;
BA_ "VNECUSLHS_VNReq" BU_ CGM_HS 4;
BA_ "VNECUSLHSSharedDiagnostic" BU_ CGM_HS 4;
BA_ "VNECUAllNodes" BU_ CGM_HS 4;
BA_ "ECU_Id" BU_ CGM_HS 31;
BA_ "SourceId" BU_ CGM_HS 69;
BA_ "VNECUSLHS_VNReq" BU_ BSM_HS 4;
BA_ "VNECUSLHSSharedDiagnostic" BU_ BSM_HS 4;
BA_ "VNECUAllNodes" BU_ BSM_HS 4;
BA_ "ECU_Id" BU_ BSM_HS 228;
BA_ "SourceId" BU_ BSM_HS 203;
BA_ "VNECUSLHS_VNReq" BU_ HCP_B_HS 4;
BA_ "VNECUSLHSSharedDiagnostic" BU_ HCP_B_HS 4;
BA_ "VNECUAllNodes" BU_ HCP_B_HS 4;
BA_ "ECU_Id" BU_ HCP_B_HS 225;
BA_ "SourceId" BU_ HCP_B_HS 23;
BA_ "VNECUSLHS_VNReq" BU_ AVM_HS 4;
BA_ "VNECUSLHSSharedDiagnostic" BU_ AVM_HS 4;
BA_ "VNECUAllNodes" BU_ AVM_HS 4;
BA_ "ECU_Id" BU_ AVM_HS 16;
BA_ "SourceId" BU_ AVM_HS 39;
BA_ "VNECUSLHS_VNReq" BU_ PFAF_HS 4;
BA_ "VNECUSLHSSharedDiagnostic" BU_ PFAF_HS 4;
BA_ "VNECUAllNodes" BU_ PFAF_HS 4;
BA_ "ECU_Id" BU_ PFAF_HS 12;
BA_ "SourceId" BU_ PFAF_HS 87;
BA_ "VNECUSLHS_VNReq" BU_ LVMPC_HS 4;
BA_ "VNECUSLHSSharedDiagnostic" BU_ LVMPC_HS 4;
BA_ "VNECUAllNodes" BU_ LVMPC_HS 4;
BA_ "VNECUSLHS_VNReq" BU_ DCDC_HS 4;
BA_ "VNECUSLHSSharedDiagnostic" BU_ DCDC_HS 4;
BA_ "VNECUAllNodes" BU_ DCDC_HS 4;
BA_ "ECU_Id" BU_ DCDC_HS 4;
BA_ "SourceId" BU_ DCDC_HS 204;
BA_ "VNECUSLHS_VNReq" BU_ TRCM_HS 4;
BA_ "VNECUSLHSSharedDiagnostic" BU_ TRCM_HS 4;
BA_ "VNECUAllNodes" BU_ TRCM_HS 4;
BA_ "ECU_Id" BU_ TRCM_HS 21;
BA_ "SourceId" BU_ TRCM_HS 28;
BA_ "VNECUSLHS_VNReq" BU_ AMP_HS 4;
BA_ "VNECUSLHSSharedDiagnostic" BU_ AMP_HS 4;
BA_ "VNECUAllNodes" BU_ AMP_HS 4;
BA_ "ECU_Id" BU_ AMP_HS 19;
BA_ "SourceId" BU_ AMP_HS 129;
BA_ "VNECUSLHS_VNReq" BU_ VICM2_HS 4;
BA_ "VNECUSLHSSharedDiagnostic" BU_ VICM2_HS 4;
BA_ "VNECUAllNodes" BU_ VICM2_HS 4;
BA_ "ECU_Id" BU_ VICM2_HS 230;
BA_ "SourceId" BU_ VICM2_HS 206;
BA_ "VNECUSLHS_VNReq" BU_ FICM_HS 4;
BA_ "VNECUSLHSSharedDiagnostic" BU_ FICM_HS 4;
BA_ "VNECUAllNodes" BU_ FICM_HS 4;
BA_ "ECU_Id" BU_ FICM_HS 230;
BA_ "SourceId" BU_ FICM_HS 19;
BA_ "VNECUSLHS_VNReq" BU_ ARS_HS 4;
BA_ "VNECUSLHSSharedDiagnostic" BU_ ARS_HS 4;
BA_ "VNECUAllNodes" BU_ ARS_HS 4;
BA_ "ECU_Id" BU_ ARS_HS 29;
BA_ "SourceId" BU_ ARS_HS 50;
BA_ "VNECUSLHS_VNReq" BU_ MCP_B_HS 4;
BA_ "VNECUSLHSSharedDiagnostic" BU_ MCP_B_HS 4;
BA_ "VNECUAllNodes" BU_ MCP_B_HS 4;
BA_ "ECU_Id" BU_ MCP_B_HS 24;
BA_ "SourceId" BU_ MCP_B_HS 30;
BA_ "VNECUSLHS_VNReq" BU_ MCP_A_HS 4;
BA_ "VNECUSLHSSharedDiagnostic" BU_ MCP_A_HS 4;
BA_ "VNECUAllNodes" BU_ MCP_A_HS 4;
BA_ "ECU_Id" BU_ MCP_A_HS 23;
BA_ "SourceId" BU_ MCP_A_HS 29;
BA_ "VNECUSLHS_VNReq" BU_ ICCM_OBD_HS 4;
BA_ "VNECUSLHSSharedDiagnostic" BU_ ICCM_OBD_HS 4;
BA_ "VNECUAllNodes" BU_ ICCM_OBD_HS 4;
BA_ "ECU_Id" BU_ ICCM_OBD_HS 227;
BA_ "SourceId" BU_ ICCM_OBD_HS 19;
BA_ "VNECUSLHS_VNReq" BU_ SAS_HS 4;
BA_ "VNECUSLHSSharedDiagnostic" BU_ SAS_HS 4;
BA_ "VNECUAllNodes" BU_ SAS_HS 4;
BA_ "ECU_Id" BU_ SAS_HS 23;
BA_ "SourceId" BU_ SAS_HS 52;
BA_ "VNECUSLHS_VNReq" BU_ ACCM_HS 4;
BA_ "VNECUSLHSSharedDiagnostic" BU_ ACCM_HS 4;
BA_ "VNECUAllNodes" BU_ ACCM_HS 4;
BA_ "ECU_Id" BU_ ACCM_HS 53;
BA_ "SourceId" BU_ ACCM_HS 156;
BA_ "VNECUSLHS_VNReq" BU_ VLBS_HS 4;
BA_ "VNECUSLHSSharedDiagnostic" BU_ VLBS_HS 4;
BA_ "VNECUAllNodes" BU_ VLBS_HS 4;
BA_ "ECU_Id" BU_ VLBS_HS 31;
BA_ "SourceId" BU_ VLBS_HS 144;
BA_ "VNECUSLHS_VNReq" BU_ EBCM_OBD_HS 4;
BA_ "VNECUSLHSSharedDiagnostic" BU_ EBCM_OBD_HS 4;
BA_ "VNECUAllNodes" BU_ EBCM_OBD_HS 4;
BA_ "ECU_Id" BU_ EBCM_OBD_HS 3;
BA_ "SourceId" BU_ EBCM_OBD_HS 40;
BA_ "VNECUSLHS_VNReq" BU_ HCP_T_HS 4;
BA_ "VNECUSLHSSharedDiagnostic" BU_ HCP_T_HS 4;
BA_ "VNECUAllNodes" BU_ HCP_T_HS 4;
BA_ "ECU_Id" BU_ HCP_T_HS 225;
BA_ "SourceId" BU_ HCP_T_HS 23;
BA_ "VNECUSLHS_VNReq" BU_ EDI_HS 4;
BA_ "VNECUSLHSSharedDiagnostic" BU_ EDI_HS 4;
BA_ "VNECUAllNodes" BU_ EDI_HS 4;
BA_ "VNECUSLHS_VNReq" BU_ HPCC_HS 4;
BA_ "VNECUSLHSSharedDiagnostic" BU_ HPCC_HS 4;
BA_ "VNECUAllNodes" BU_ HPCC_HS 4;
BA_ "ECU_Id" BU_ HPCC_HS 3;
BA_ "SourceId" BU_ HPCC_HS 200;
BA_ "VNECUSLHS_VNReq" BU_ VITM_OBD_HS 4;
BA_ "VNECUSLHSSharedDiagnostic" BU_ VITM_OBD_HS 4;
BA_ "VNECUAllNodes" BU_ VITM_OBD_HS 4;
BA_ "ECU_Id" BU_ VITM_OBD_HS 231;
BA_ "SourceId" BU_ VITM_OBD_HS 205;
BA_ "VNECUSLHS_VNReq" BU_ VICM_HS 4;
BA_ "VNECUSLHSSharedDiagnostic" BU_ VICM_HS 4;
BA_ "VNECUAllNodes" BU_ VICM_HS 4;
BA_ "ECU_Id" BU_ VICM_HS 228;
BA_ "SourceId" BU_ VICM_HS 203;
BA_ "VNECUSLHS_VNReq" BU_ HCP_HS 4;
BA_ "VNECUSLHSSharedDiagnostic" BU_ HCP_HS 4;
BA_ "VNECUAllNodes" BU_ HCP_HS 4;
BA_ "ECU_Id" BU_ HCP_HS 225;
BA_ "SourceId" BU_ HCP_HS 23;
BA_ "VNECUSLHS_VNReq" BU_ APPS_HS 4;
BA_ "VNECUSLHSSharedDiagnostic" BU_ APPS_HS 4;
BA_ "VNECUAllNodes" BU_ APPS_HS 4;
BA_ "ECU_Id" BU_ APPS_HS 6;
BA_ "SourceId" BU_ APPS_HS 93;
BA_ "VNECUSLHS_VNReq" BU_ ICCM_HS 4;
BA_ "VNECUSLHSSharedDiagnostic" BU_ ICCM_HS 4;
BA_ "VNECUAllNodes" BU_ ICCM_HS 4;
BA_ "ECU_Id" BU_ ICCM_HS 227;
BA_ "SourceId" BU_ ICCM_HS 34;
BA_ "VNECUSLHS_VNReq" BU_ EOCM_F_HS 4;
BA_ "VNECUSLHSSharedDiagnostic" BU_ EOCM_F_HS 4;
BA_ "VNECUAllNodes" BU_ EOCM_F_HS 4;
BA_ "ECU_Id" BU_ EOCM_F_HS 75;
BA_ "SourceId" BU_ EOCM_F_HS 108;
BA_ "VNECUSLHS_VNReq" BU_ GPCM_HS 4;
BA_ "VNECUSLHSSharedDiagnostic" BU_ GPCM_HS 4;
BA_ "VNECUAllNodes" BU_ GPCM_HS 4;
BA_ "ECU_Id" BU_ GPCM_HS 230;
BA_ "SourceId" BU_ GPCM_HS 22;
BA_ "VNECUSLHS_VNReq" BU_ VCM_HS 4;
BA_ "VNECUSLHSSharedDiagnostic" BU_ VCM_HS 4;
BA_ "VNECUAllNodes" BU_ VCM_HS 4;
BA_ "ECU_Id" BU_ VCM_HS 30;
BA_ "SourceId" BU_ VCM_HS 20;
BA_ "VNECUSLHS_VNReq" BU_ HMIM_HS 4;
BA_ "VNECUSLHSSharedDiagnostic" BU_ HMIM_HS 4;
BA_ "VNECUAllNodes" BU_ HMIM_HS 4;
BA_ "ECU_Id" BU_ HMIM_HS 18;
BA_ "SourceId" BU_ HMIM_HS 143;
BA_ "VNECUSLHS_VNReq" BU_ VES_HS 4;
BA_ "VNECUSLHSSharedDiagnostic" BU_ VES_HS 4;
BA_ "VNECUAllNodes" BU_ VES_HS 4;
BA_ "ECU_Id" BU_ VES_HS 2;
BA_ "SourceId" BU_ VES_HS 49;
BA_ "VNECUSLHSSharedDiagnostic" BU_ Dummy_HS 4;
BA_ "VNECUAllNodes" BU_ Dummy_HS 4;
BA_ "VNECUSLHS_VNReq" BU_ MCP_C_HS 4;
BA_ "VNECUSLHSSharedDiagnostic" BU_ MCP_C_HS 4;
BA_ "VNECUAllNodes" BU_ MCP_C_HS 4;
BA_ "ECU_Id" BU_ MCP_C_HS 25;
BA_ "SourceId" BU_ MCP_C_HS 31;
BA_ "VNECUSLHS_VNReq" BU_ ONSTAR_HS 4;
BA_ "VNECUSLHSSharedDiagnostic" BU_ ONSTAR_HS 4;
BA_ "VNECUAllNodes" BU_ ONSTAR_HS 4;
BA_ "ECU_Id" BU_ ONSTAR_HS 13;
BA_ "SourceId" BU_ ONSTAR_HS 151;
BA_ "VNECUSLHS_VNReq" BU_ EPS_HS 4;
BA_ "VNECUSLHSSharedDiagnostic" BU_ EPS_HS 4;
BA_ "VNECUAllNodes" BU_ EPS_HS 4;
BA_ "ECU_Id" BU_ EPS_HS 2;
BA_ "SourceId" BU_ EPS_HS 49;
BA_ "VNECUSLHS_VNReq" BU_ TestTool_HS 4;
BA_ "VNECUSLHSSharedDiagnostic" BU_ TestTool_HS 4;
BA_ "VNECUAllNodes" BU_ TestTool_HS 4;
BA_ "SourceId" BU_ TestTool_HS 253;
BA_ "VNECUSLHS_VNReq" BU_ MCP_HS 4;
BA_ "VNECUSLHSSharedDiagnostic" BU_ MCP_HS 4;
BA_ "VNECUAllNodes" BU_ MCP_HS 4;
BA_ "ECU_Id" BU_ MCP_HS 23;
BA_ "SourceId" BU_ MCP_HS 29;
BA_ "VNECUSLHS_VNReq" BU_ BCP_HS 4;
BA_ "VNECUSLHSSharedDiagnostic" BU_ BCP_HS 4;
BA_ "VNECUAllNodes" BU_ BCP_HS 4;
BA_ "ECU_Id" BU_ BCP_HS 225;
BA_ "SourceId" BU_ BCP_HS 23;
BA_ "VNECUSLHS_VNReq" BU_ ALC_HS 4;
BA_ "VNECUSLHSSharedDiagnostic" BU_ ALC_HS 4;
BA_ "VNECUAllNodes" BU_ ALC_HS 4;
BA_ "ECU_Id" BU_ ALC_HS 14;
BA_ "SourceId" BU_ ALC_HS 58;
BA_ "VNECUSLHS_VNReq" BU_ AHL_AFL_HS 4;
BA_ "VNECUSLHSSharedDiagnostic" BU_ AHL_AFL_HS 4;
BA_ "VNECUAllNodes" BU_ AHL_AFL_HS 4;
BA_ "ECU_Id" BU_ AHL_AFL_HS 9;
BA_ "SourceId" BU_ AHL_AFL_HS 114;
BA_ "VNECUSLHS_VNReq" BU_ SADS_HS 4;
BA_ "VNECUSLHSSharedDiagnostic" BU_ SADS_HS 4;
BA_ "VNECUAllNodes" BU_ SADS_HS 4;
BA_ "ECU_Id" BU_ SADS_HS 14;
BA_ "SourceId" BU_ SADS_HS 56;
BA_ "VNECUSLHS_VNReq" BU_ EPB_HS 4;
BA_ "VNECUSLHSSharedDiagnostic" BU_ EPB_HS 4;
BA_ "VNECUAllNodes" BU_ EPB_HS 4;
BA_ "ECU_Id" BU_ EPB_HS 20;
BA_ "SourceId" BU_ EPB_HS 43;
BA_ "VNECUSLHS_VNReq" BU_ FCM_HS 4;
BA_ "VNECUSLHSSharedDiagnostic" BU_ FCM_HS 4;
BA_ "VNECUAllNodes" BU_ FCM_HS 4;
BA_ "ECU_Id" BU_ FCM_HS 11;
BA_ "SourceId" BU_ FCM_HS 188;
BA_ "VNECUSLHS_VNReq" BU_ TCCM_HS 4;
BA_ "VNECUSLHSSharedDiagnostic" BU_ TCCM_HS 4;
BA_ "VNECUAllNodes" BU_ TCCM_HS 4;
BA_ "ECU_Id" BU_ TCCM_HS 22;
BA_ "SourceId" BU_ TCCM_HS 26;
BA_ "VNECUSLHS_VNReq" BU_ RDCM_HS 4;
BA_ "VNECUSLHSSharedDiagnostic" BU_ RDCM_HS 4;
BA_ "VNECUAllNodes" BU_ RDCM_HS 4;
BA_ "ECU_Id" BU_ RDCM_HS 15;
BA_ "SourceId" BU_ RDCM_HS 27;
BA_ "VNECUSLHS_VNReq" BU_ PTO_HS 4;
BA_ "VNECUSLHSSharedDiagnostic" BU_ PTO_HS 4;
BA_ "VNECUAllNodes" BU_ PTO_HS 4;
BA_ "ECU_Id" BU_ PTO_HS 7;
BA_ "SourceId" BU_ PTO_HS 25;
BA_ "VNECUSLHS_VNReq" BU_ EBCM_HS 4;
BA_ "VNECUSLHSSharedDiagnostic" BU_ EBCM_HS 4;
BA_ "VNECUAllNodes" BU_ EBCM_HS 4;
BA_ "ECU_Id" BU_ EBCM_HS 3;
BA_ "SourceId" BU_ EBCM_HS 40;
BA_ "VNECUSLHS_VNReq" BU_ ACC_HS 4;
BA_ "VNECUSLHSSharedDiagnostic" BU_ ACC_HS 4;
BA_ "VNECUAllNodes" BU_ ACC_HS 4;
BA_ "ECU_Id" BU_ ACC_HS 27;
BA_ "SourceId" BU_ ACC_HS 33;
BA_ "VNECUSLHS_VNReq" BU_ BCM_HS 4;
BA_ "VNECUSLHSSharedDiagnostic" BU_ BCM_HS 4;
BA_ "VNECUAllNodes" BU_ BCM_HS 4;
BA_ "ECU_Id" BU_ BCM_HS 1;
BA_ "SourceId" BU_ BCM_HS 64;
BA_ "VNECUSLHS_VNReq" BU_ TCM_HS 4;
BA_ "VNECUSLHSSharedDiagnostic" BU_ TCM_HS 4;
BA_ "VNECUAllNodes" BU_ TCM_HS 4;
BA_ "ECU_Id" BU_ TCM_HS 226;
BA_ "SourceId" BU_ TCM_HS 24;
BA_ "VNECUSLHS_VNReq" BU_ ECM_HS 4;
BA_ "VNECUSLHSSharedDiagnostic" BU_ ECM_HS 4;
BA_ "VNECUAllNodes" BU_ ECM_HS 4;
BA_ "ECU_Id" BU_ ECM_HS 224;
BA_ "SourceId" BU_ ECM_HS 17;
BA_ "Prio" BO_ 1798 0;
BA_ "Prio" BO_ 1800 0;
BA_ "Prio" BO_ 1995 0;
BA_ "MessageSubnet" BO_ 1995 2;
BA_ "GenMsgCycleTime" BO_ 1995 10;
BA_ "Prio" BO_ 705 0;
BA_ "MessageSubnet" BO_ 705 2;
BA_ "GenMsgCycleTime" BO_ 705 50;
BA_ "GenMsgSendType" BO_ 705 0;
BA_ "Prio" BO_ 503 0;
BA_ "MessageSubnet" BO_ 503 2;
BA_ "GenMsgCycleTime" BO_ 503 25;
BA_ "GenMsgSendType" BO_ 503 0;
BA_ "Prio" BO_ 872 0;
BA_ "MessageSubnet" BO_ 872 2;
BA_ "GenMsgCycleTime" BO_ 872 25;
BA_ "GenMsgSendType" BO_ 872 0;
BA_ "Prio" BO_ 353 0;
BA_ "MessageSubnet" BO_ 353 2;
BA_ "GenMsgCycleTime" BO_ 353 100;
BA_ "GenMsgSendType" BO_ 353 0;
BA_ "Prio" BO_ 1275 0;
BA_ "MessageSubnet" BO_ 1275 2;
BA_ "GenMsgCycleTime" BO_ 1275 500;
BA_ "GenMsgSendType" BO_ 1275 0;
BA_ "Prio" BO_ 1273 0;
BA_ "MessageSubnet" BO_ 1273 2;
BA_ "GenMsgCycleTime" BO_ 1273 500;
BA_ "GenMsgSendType" BO_ 1273 0;
BA_ "Prio" BO_ 1271 0;
BA_ "MessageSubnet" BO_ 1271 2;
BA_ "GenMsgCycleTime" BO_ 1271 5000;
BA_ "GenMsgSendType" BO_ 1271 0;
BA_ "Prio" BO_ 558 0;
BA_ "MessageSubnet" BO_ 558 2;
BA_ "GenMsgCycleTime" BO_ 558 100;
BA_ "GenMsgSendType" BO_ 558 0;
BA_ "Prio" BO_ 208 0;
BA_ "MessageSubnet" BO_ 208 2;
BA_ "GenMsgCycleTime" BO_ 208 100;
BA_ "GenMsgSendType" BO_ 208 0;
BA_ "Prio" BO_ 663 0;
BA_ "MessageSubnet" BO_ 663 2;
BA_ "GenMsgCycleTime" BO_ 663 100;
BA_ "GenMsgSendType" BO_ 663 0;
BA_ "Prio" BO_ 1263 0;
BA_ "MessageSubnet" BO_ 1263 2;
BA_ "GenMsgCycleTime" BO_ 1263 1000;
BA_ "GenMsgSendType" BO_ 1263 0;
BA_ "Prio" BO_ 1261 0;
BA_ "MessageSubnet" BO_ 1261 2;
BA_ "GenMsgCycleTime" BO_ 1261 1000;
BA_ "GenMsgSendType" BO_ 1261 0;
BA_ "Prio" BO_ 1259 0;
BA_ "MessageSubnet" BO_ 1259 2;
BA_ "GenMsgCycleTime" BO_ 1259 500;
BA_ "GenMsgSendType" BO_ 1259 0;
BA_ "Prio" BO_ 1034 0;
BA_ "MessageSubnet" BO_ 1034 2;
BA_ "GenMsgCycleTime" BO_ 1034 100;
BA_ "GenMsgSendType" BO_ 1034 0;
BA_ "Prio" BO_ 1033 0;
BA_ "MessageSubnet" BO_ 1033 2;
BA_ "GenMsgCycleTime" BO_ 1033 100;
BA_ "GenMsgSendType" BO_ 1033 0;
BA_ "Prio" BO_ 1013 0;
BA_ "MessageSubnet" BO_ 1013 2;
BA_ "GenMsgCycleTime" BO_ 1013 250;
BA_ "GenMsgSendType" BO_ 1013 0;
BA_ "Prio" BO_ 425 0;
BA_ "MessageSubnet" BO_ 425 2;
BA_ "GenMsgCycleTime" BO_ 425 25;
BA_ "GenMsgSendType" BO_ 425 0;
BA_ "Prio" BO_ 424 0;
BA_ "MessageSubnet" BO_ 424 2;
BA_ "GenMsgCycleTime" BO_ 424 25;
BA_ "GenMsgSendType" BO_ 424 0;
BA_ "Prio" BO_ 324 0;
BA_ "MessageSubnet" BO_ 324 2;
BA_ "GenMsgCycleTime" BO_ 324 250;
BA_ "GenMsgSendType" BO_ 324 0;
BA_ "Prio" BO_ 844 0;
BA_ "MessageSubnet" BO_ 844 2;
BA_ "GenMsgCycleTime" BO_ 844 50;
BA_ "GenMsgSendType" BO_ 844 0;
BA_ "Prio" BO_ 308 0;
BA_ "MessageSubnet" BO_ 308 2;
BA_ "GenMsgCycleTime" BO_ 308 1000;
BA_ "GenMsgSendType" BO_ 308 0;
BA_ "Prio" BO_ 806 0;
BA_ "MessageSubnet" BO_ 806 2;
BA_ "GenMsgCycleTime" BO_ 806 500;
BA_ "GenMsgSendType" BO_ 806 0;
BA_ "Prio" BO_ 426 0;
BA_ "MessageSubnet" BO_ 426 2;
BA_ "GenMsgCycleTime" BO_ 426 25;
BA_ "GenMsgSendType" BO_ 426 0;
BA_ "Prio" BO_ 1231 0;
BA_ "MessageSubnet" BO_ 1231 2;
BA_ "GenMsgCycleTime" BO_ 1231 1000;
BA_ "GenMsgSendType" BO_ 1231 0;
BA_ "Prio" BO_ 963 0;
BA_ "MessageSubnet" BO_ 963 2;
BA_ "GenMsgCycleTime" BO_ 963 100;
BA_ "GenMsgSendType" BO_ 963 0;
BA_ "Prio" BO_ 955 0;
BA_ "MessageSubnet" BO_ 955 2;
BA_ "GenMsgCycleTime" BO_ 955 100;
BA_ "GenMsgSendType" BO_ 955 0;
BA_ "Prio" BO_ 423 0;
BA_ "MessageSubnet" BO_ 423 2;
BA_ "GenMsgCycleTime" BO_ 423 25;
BA_ "GenMsgSendType" BO_ 423 0;
BA_ "Prio" BO_ 2034 0;
BA_ "MessageSubnet" BO_ 2034 2;
BA_ "DiagResponse" BO_ 2034 1;
BA_ "Prio" BO_ 2032 0;
BA_ "MessageSubnet" BO_ 2032 2;
BA_ "DiagRequest" BO_ 2032 1;
BA_ "VNSigAllNodes" SG_ 1995 T1_HostToTarget 1;
BA_ "SignalType" SG_ 705 TransActlRngPVl "UNM";
BA_ "SignalLongName" SG_ 705 TransActlRngPVl "Transmission Actual Range Protection Value";
BA_ "VNSigAllNodes" SG_ 705 TransActlRngPVl 1;
BA_ "SignalType" SG_ 705 TransActlRngARC "UNM";
BA_ "SignalLongName" SG_ 705 TransActlRngARC "Transmission Actual Range Alive Rolling Count";
BA_ "VNSigAllNodes" SG_ 705 TransActlRngARC 1;
BA_ "SignalType" SG_ 705 TransActlRng "ENM";
BA_ "SignalLongName" SG_ 705 TransActlRng "Transmission Actual Range";
BA_ "VNSigAllNodes" SG_ 705 TransActlRng 1;
BA_ "SignalType" SG_ 503 ElcTransRngRqPVal "UNM";
BA_ "SignalLongName" SG_ 503 ElcTransRngRqPVal "Electronic Transmission Range Request Protection Value";
BA_ "VNSigAllNodes" SG_ 503 ElcTransRngRqPVal 1;
BA_ "SignalType" SG_ 503 ElcTransRngRqARC "UNM";
BA_ "SignalLongName" SG_ 503 ElcTransRngRqARC "Electronic Transmission Range Request Alive Rolling Count";
BA_ "VNSigAllNodes" SG_ 503 ElcTransRngRqARC 1;
BA_ "SignalType" SG_ 503 ElcTransRngRq "ENM";
BA_ "SignalLongName" SG_ 503 ElcTransRngRq "Electronic Transmission Range Request";
BA_ "VNSigAllNodes" SG_ 503 ElcTransRngRq 1;
BA_ "PacketOrder" SG_ 872 ESBR_AutoBrkgRqTyp 2;
BA_ "SignalType" SG_ 872 ESBR_AutoBrkgRqTyp "ENM";
BA_ "SignalLongName" SG_ 872 ESBR_AutoBrkgRqTyp "Electronic Shift Braking Request : Automatic Braking Request Type";
BA_ "VNSigAllNodes" SG_ 872 ESBR_AutoBrkgRqTyp 1;
BA_ "PacketOrder" SG_ 872 ESBR_AutoBrkgRqd 1;
BA_ "SignalType" SG_ 872 ESBR_AutoBrkgRqd "ENM";
BA_ "SignalLongName" SG_ 872 ESBR_AutoBrkgRqd "Electronic Shift Braking Request : Automatic Braking Requested";
BA_ "VNSigAllNodes" SG_ 872 ESBR_AutoBrkgRqd 1;
BA_ "SignalType" SG_ 872 ElcShftBrkgRqPVal "UNM";
BA_ "SignalLongName" SG_ 872 ElcShftBrkgRqPVal "Electronic Shift Braking Request Protection Value";
BA_ "VNSigAllNodes" SG_ 872 ElcShftBrkgRqPVal 1;
BA_ "SignalType" SG_ 872 ElcShftBrkgRqARC "UNM";
BA_ "SignalLongName" SG_ 872 ElcShftBrkgRqARC "Electronic Shift Braking Request Alive Rolling Count";
BA_ "VNSigAllNodes" SG_ 872 ElcShftBrkgRqARC 1;
BA_ "SignalType" SG_ 353 ElecShfRngDispRCExtd "UNM";
BA_ "SignalLongName" SG_ 353 ElecShfRngDispRCExtd "Electronic Shift Range Display Rolling Count Extended";
BA_ "VNSigAllNodes" SG_ 353 ElecShfRngDispRCExtd 1;
BA_ "SignalType" SG_ 353 ElecShfRngDisp "ENM";
BA_ "SignalLongName" SG_ 353 ElecShfRngDisp "Electronic Shift Range Display";
BA_ "VNSigAllNodes" SG_ 353 ElecShfRngDisp 1;
BA_ "SignalType" SG_ 353 ESPTransMalfIO "BLN";
BA_ "SignalLongName" SG_ 353 ESPTransMalfIO "Electronic Shift Primary Transmission Malfunction Indication On";
BA_ "VNSigAllNodes" SG_ 353 ESPTransMalfIO 1;
BA_ "SignalType" SG_ 353 ESPRngInvldReqIO "BLN";
BA_ "SignalLongName" SG_ 353 ESPRngInvldReqIO "Electronic Shift Primary Range Invalid Request Indication On";
BA_ "VNSigAllNodes" SG_ 353 ESPRngInvldReqIO 1;
BA_ "SignalType" SG_ 353 ESPPrkInvldReqIO "BLN";
BA_ "SignalLongName" SG_ 353 ESPPrkInvldReqIO "Electronic Shift Primary Park Invalid Request Indication On";
BA_ "VNSigAllNodes" SG_ 353 ESPPrkInvldReqIO 1;
BA_ "SignalType" SG_ 353 ESPHldShfLvrToEngRgIO "BLN";
BA_ "SignalLongName" SG_ 353 ESPHldShfLvrToEngRgIO "Electronic Shift Primary Hold Shift Lever to Engage Range Indication On";
BA_ "VNSigAllNodes" SG_ 353 ESPHldShfLvrToEngRgIO 1;
BA_ "SignalType" SG_ 353 ESPDrvrPrkIlkSftAtdIO "BLN";
BA_ "SignalLongName" SG_ 353 ESPDrvrPrkIlkSftAtdIO "Electronic Shift Primary Driver Park Interlock Shift Attempted Indication On";
BA_ "VNSigAllNodes" SG_ 353 ESPDrvrPrkIlkSftAtdIO 1;
BA_ "SignalType" SG_ 353 ESPDrvrIlkShfAtdIO "BLN";
BA_ "SignalLongName" SG_ 353 ESPDrvrIlkShfAtdIO "Electronic Shift Primary Driver Interlock Shift Attempted Indication On";
BA_ "VNSigAllNodes" SG_ 353 ESPDrvrIlkShfAtdIO 1;
BA_ "SignalType" SG_ 1275 BrkSyCtl2EmsRldMlfAct "BLN";
BA_ "SignalLongName" SG_ 1275 BrkSyCtl2EmsRldMlfAct "Brake System Control 2 Emissions Related Malfunction Active";
BA_ "VNSigAllNodes" SG_ 1275 BrkSyCtl2EmsRldMlfAct 1;
BA_ "PacketOrder" SG_ 1275 BSC2ERDTC_CdNum 2;
BA_ "SignalType" SG_ 1275 BSC2ERDTC_CdNum "UNM";
BA_ "SignalLongName" SG_ 1275 BSC2ERDTC_CdNum "Brake System Control 2 Emissions Related DTC : Code Number";
BA_ "VNSigAllNodes" SG_ 1275 BSC2ERDTC_CdNum 1;
BA_ "PacketOrder" SG_ 1275 BSC2ERDTC_SysDes 1;
BA_ "SignalType" SG_ 1275 BSC2ERDTC_SysDes "ENM";
BA_ "SignalLongName" SG_ 1275 BSC2ERDTC_SysDes "Brake System Control 2 Related DTC : System Designator";
BA_ "VNSigAllNodes" SG_ 1275 BSC2ERDTC_SysDes 1;
BA_ "SignalType" SG_ 1275 EBrkAstStat "ENM";
BA_ "SignalLongName" SG_ 1275 EBrkAstStat "EBrakeAssist Status";
BA_ "VNSigAllNodes" SG_ 1275 EBrkAstStat 1;
BA_ "SignalType" SG_ 1273 BrkSyCtl1EmsRldMlfAct "BLN";
BA_ "SignalLongName" SG_ 1273 BrkSyCtl1EmsRldMlfAct "Brake System Control 1 Emissions Related Malfunction Active";
BA_ "VNSigAllNodes" SG_ 1273 BrkSyCtl1EmsRldMlfAct 1;
BA_ "PacketOrder" SG_ 1273 BSC1ERDTC_CdNum 2;
BA_ "SignalType" SG_ 1273 BSC1ERDTC_CdNum "UNM";
BA_ "SignalLongName" SG_ 1273 BSC1ERDTC_CdNum "Brake System Control 1 Emissions Related DTC : Code Number";
BA_ "VNSigAllNodes" SG_ 1273 BSC1ERDTC_CdNum 1;
BA_ "PacketOrder" SG_ 1273 BSC1ERDTC_SysDes 1;
BA_ "SignalType" SG_ 1273 BSC1ERDTC_SysDes "ENM";
BA_ "SignalLongName" SG_ 1273 BSC1ERDTC_SysDes "Brake System Control 1 Related DTC : System Designator";
BA_ "VNSigAllNodes" SG_ 1273 BSC1ERDTC_SysDes 1;
BA_ "SignalType" SG_ 1271 BatSvrMdLvl7Act "BLN";
BA_ "SignalLongName" SG_ 1271 BatSvrMdLvl7Act "Battery Saver Mode Level 7 Active";
BA_ "VNSigAllNodes" SG_ 1271 BatSvrMdLvl7Act 1;
BA_ "SignalType" SG_ 1271 BatSvrMdNetAmpHr "UNM";
BA_ "SignalLongName" SG_ 1271 BatSvrMdNetAmpHr "Battery Saver Mode Net Amp Hour";
BA_ "VNSigAllNodes" SG_ 1271 BatSvrMdNetAmpHr 1;
BA_ "SignalType" SG_ 1271 BatSvrMdWkUpCtr "UNM";
BA_ "SignalLongName" SG_ 1271 BatSvrMdWkUpCtr "Battery Saver Mode Wake Up Counter";
BA_ "VNSigAllNodes" SG_ 1271 BatSvrMdWkUpCtr 1;
BA_ "SignalType" SG_ 1271 BSMCT_RawVal "UNM";
BA_ "PacketOrder" SG_ 1271 BSMCT_RawVal 2;
BA_ "SignalLongName" SG_ 1271 BSMCT_RawVal "Battery Saver Mode Current Trigger : Raw Value";
BA_ "VNSigAllNodes" SG_ 1271 BSMCT_RawVal 1;
BA_ "SignalType" SG_ 1271 BSMCT_Mult "ENM";
BA_ "PacketOrder" SG_ 1271 BSMCT_Mult 1;
BA_ "SignalLongName" SG_ 1271 BSMCT_Mult "Battery Saver Mode Current Trigger : Multiplier";
BA_ "VNSigAllNodes" SG_ 1271 BSMCT_Mult 1;
BA_ "SignalType" SG_ 1271 BatSvrMdVltTrg "UNM";
BA_ "SignalLongName" SG_ 1271 BatSvrMdVltTrg "Battery Saver Mode Voltage Trigger";
BA_ "VNSigAllNodes" SG_ 1271 BatSvrMdVltTrg 1;
BA_ "SignalType" SG_ 1271 BatSvrMdLvl6Act "BLN";
BA_ "SignalLongName" SG_ 1271 BatSvrMdLvl6Act "Battery Saver Mode Level 6 Active";
BA_ "VNSigAllNodes" SG_ 1271 BatSvrMdLvl6Act 1;
BA_ "SignalType" SG_ 1271 BatSvrMdLvl5Act "BLN";
BA_ "SignalLongName" SG_ 1271 BatSvrMdLvl5Act "Battery Saver Mode Level 5 Active";
BA_ "VNSigAllNodes" SG_ 1271 BatSvrMdLvl5Act 1;
BA_ "SignalType" SG_ 1271 BatSvrMdLvl4Act "BLN";
BA_ "SignalLongName" SG_ 1271 BatSvrMdLvl4Act "Battery Saver Mode Level 4 Active";
BA_ "VNSigAllNodes" SG_ 1271 BatSvrMdLvl4Act 1;
BA_ "SignalType" SG_ 558 CmpDataPktARC "UNM";
BA_ "SignalLongName" SG_ 558 CmpDataPktARC "Compressor Data Paket Alive Rolling Count";
BA_ "VNSigAllNodes" SG_ 558 CmpDataPktARC 1;
BA_ "SignalType" SG_ 558 CDP_HVDevShtdnCdARCSt "ENM";
BA_ "PacketOrder" SG_ 558 CDP_HVDevShtdnCdARCSt 5;
BA_ "SignalLongName" SG_ 558 CDP_HVDevShtdnCdARCSt "Compressor Data Packet : High Voltage Device Shutdown Commanded Alive Rolling Count State";
BA_ "VNSigAllNodes" SG_ 558 CDP_HVDevShtdnCdARCSt 1;
BA_ "SignalType" SG_ 558 CDP_CmpSpdReqARCSt "ENM";
BA_ "PacketOrder" SG_ 558 CDP_CmpSpdReqARCSt 4;
BA_ "SignalLongName" SG_ 558 CDP_CmpSpdReqARCSt "Compressor Data Packet : Compressor Speed Request Alive Rolling Count State";
BA_ "VNSigAllNodes" SG_ 558 CDP_CmpSpdReqARCSt 1;
BA_ "SignalType" SG_ 558 CDP_CmpLossCommOcc "BLN";
BA_ "PacketOrder" SG_ 558 CDP_CmpLossCommOcc 3;
BA_ "SignalLongName" SG_ 558 CDP_CmpLossCommOcc "Compressor Data Packet : Compressor Loss of Communication Occurred";
BA_ "VNSigAllNodes" SG_ 558 CDP_CmpLossCommOcc 1;
BA_ "SignalType" SG_ 558 CDP_CmpWkUp "BLN";
BA_ "PacketOrder" SG_ 558 CDP_CmpWkUp 2;
BA_ "SignalLongName" SG_ 558 CDP_CmpWkUp "Compressor Data Packet : Compressor Wake up";
BA_ "VNSigAllNodes" SG_ 558 CDP_CmpWkUp 1;
BA_ "SignalType" SG_ 558 CDP_CmpRunCrnk "BLN";
BA_ "PacketOrder" SG_ 558 CDP_CmpRunCrnk 1;
BA_ "SignalLongName" SG_ 558 CDP_CmpRunCrnk "Compressor Data Packet : Compressor Run Crank";
BA_ "VNSigAllNodes" SG_ 558 CDP_CmpRunCrnk 1;
BA_ "SignalType" SG_ 558 CmpSnsrDevStPktARC "UNM";
BA_ "SignalLongName" SG_ 558 CmpSnsrDevStPktARC "Compressor Device State Packet Alive Rolling Count";
BA_ "VNSigAllNodes" SG_ 558 CmpSnsrDevStPktARC 1;
BA_ "SignalType" SG_ 558 CDSP_CmpOvrTmpSt "ENM";
BA_ "PacketOrder" SG_ 558 CDSP_CmpOvrTmpSt 5;
BA_ "SignalLongName" SG_ 558 CDSP_CmpOvrTmpSt "Compressor Device State Packet : Compressor Over Temperature State";
BA_ "VNSigAllNodes" SG_ 558 CDSP_CmpOvrTmpSt 1;
BA_ "SignalType" SG_ 558 CDSP_CmpHVAbnrlOrVltSt "ENM";
BA_ "PacketOrder" SG_ 558 CDSP_CmpHVAbnrlOrVltSt 4;
BA_ "SignalLongName" SG_ 558 CDSP_CmpHVAbnrlOrVltSt "Compressor Device State Packet : Compressor High Voltage Abnormal Over Voltage State";
BA_ "VNSigAllNodes" SG_ 558 CDSP_CmpHVAbnrlOrVltSt 1;
BA_ "SignalType" SG_ 558 CDSP_CmpHVUndrVltgSt "ENM";
BA_ "PacketOrder" SG_ 558 CDSP_CmpHVUndrVltgSt 3;
BA_ "SignalLongName" SG_ 558 CDSP_CmpHVUndrVltgSt "Compressor Device State Packet : Compressor High Voltage Under Voltage State";
BA_ "VNSigAllNodes" SG_ 558 CDSP_CmpHVUndrVltgSt 1;
BA_ "SignalType" SG_ 558 CDSP_CmpHVOvrVltgSt "ENM";
BA_ "PacketOrder" SG_ 558 CDSP_CmpHVOvrVltgSt 2;
BA_ "SignalLongName" SG_ 558 CDSP_CmpHVOvrVltgSt "Compressor Device State Packet : Compressor High Voltage Over Voltage State";
BA_ "VNSigAllNodes" SG_ 558 CDSP_CmpHVOvrVltgSt 1;
BA_ "SignalType" SG_ 558 CDSP_CmpHVOvrCrntSt "ENM";
BA_ "PacketOrder" SG_ 558 CDSP_CmpHVOvrCrntSt 1;
BA_ "SignalLongName" SG_ 558 CDSP_CmpHVOvrCrntSt "Compressor Device State Packet : Compressor High Voltage Over Current State";
BA_ "VNSigAllNodes" SG_ 558 CDSP_CmpHVOvrCrntSt 1;
BA_ "SignalType" SG_ 558 CDSP_OvrTempWrnInd "BLN";
BA_ "PacketOrder" SG_ 558 CDSP_OvrTempWrnInd 15;
BA_ "SignalLongName" SG_ 558 CDSP_OvrTempWrnInd "Compressor Device State Packet : Over Temperature Warning Indication";
BA_ "VNSigAllNodes" SG_ 558 CDSP_OvrTempWrnInd 1;
BA_ "SignalType" SG_ 558 CDSP_CmpDgrdOp "BLN";
BA_ "PacketOrder" SG_ 558 CDSP_CmpDgrdOp 14;
BA_ "SignalLongName" SG_ 558 CDSP_CmpDgrdOp "Compressor Device State Packet : Compressor Degraded Operation";
BA_ "VNSigAllNodes" SG_ 558 CDSP_CmpDgrdOp 1;
BA_ "SignalType" SG_ 558 CDSP_CmpIntShdwnFltSt "ENM";
BA_ "PacketOrder" SG_ 558 CDSP_CmpIntShdwnFltSt 13;
BA_ "SignalLongName" SG_ 558 CDSP_CmpIntShdwnFltSt "Compressor Device State Packet : Compressor Internal Shutdown Fault State";
BA_ "VNSigAllNodes" SG_ 558 CDSP_CmpIntShdwnFltSt 1;
BA_ "SignalType" SG_ 558 CDSP_CmpIntRecblFltSt "ENM";
BA_ "PacketOrder" SG_ 558 CDSP_CmpIntRecblFltSt 12;
BA_ "SignalLongName" SG_ 558 CDSP_CmpIntRecblFltSt "Compressor Device State Packet : Compressor Internal Recoverable Fault State";
BA_ "VNSigAllNodes" SG_ 558 CDSP_CmpIntRecblFltSt 1;
BA_ "SignalType" SG_ 558 CDSP_CmpOpOvrldSt "ENM";
BA_ "PacketOrder" SG_ 558 CDSP_CmpOpOvrldSt 11;
BA_ "SignalLongName" SG_ 558 CDSP_CmpOpOvrldSt "Compressor Device State Packet : Compressor Output Overload State";
BA_ "VNSigAllNodes" SG_ 558 CDSP_CmpOpOvrldSt 1;
BA_ "SignalType" SG_ 558 CDSP_CmpDrCrctFltSt "ENM";
BA_ "PacketOrder" SG_ 558 CDSP_CmpDrCrctFltSt 10;
BA_ "SignalLongName" SG_ 558 CDSP_CmpDrCrctFltSt "Compressor Device State Packet : Compressor Drive Circuit Fault State";
BA_ "VNSigAllNodes" SG_ 558 CDSP_CmpDrCrctFltSt 1;
BA_ "SignalType" SG_ 558 CDSP_CmpMtrPerfFltSt "ENM";
BA_ "PacketOrder" SG_ 558 CDSP_CmpMtrPerfFltSt 9;
BA_ "SignalLongName" SG_ 558 CDSP_CmpMtrPerfFltSt "Compressor Device State Packet : Compressor Motor Performance Fault State";
BA_ "VNSigAllNodes" SG_ 558 CDSP_CmpMtrPerfFltSt 1;
BA_ "SignalType" SG_ 558 CDSP_CmpEEPROMFltSt "ENM";
BA_ "PacketOrder" SG_ 558 CDSP_CmpEEPROMFltSt 8;
BA_ "SignalLongName" SG_ 558 CDSP_CmpEEPROMFltSt "Compressor Device State Packet : Compressor Electrically Erasable Programmable Read-Only Memory Fault State";
BA_ "VNSigAllNodes" SG_ 558 CDSP_CmpEEPROMFltSt 1;
BA_ "SignalType" SG_ 558 CDSP_CmpROMFltSt "ENM";
BA_ "PacketOrder" SG_ 558 CDSP_CmpROMFltSt 7;
BA_ "SignalLongName" SG_ 558 CDSP_CmpROMFltSt "Compressor Device State Packet : Compressor Read Only Memory Fault State";
BA_ "VNSigAllNodes" SG_ 558 CDSP_CmpROMFltSt 1;
BA_ "SignalType" SG_ 558 CDSP_CmpRAMFltSt "ENM";
BA_ "PacketOrder" SG_ 558 CDSP_CmpRAMFltSt 6;
BA_ "SignalLongName" SG_ 558 CDSP_CmpRAMFltSt "Compressor Device State Packet : Compressor Random Access Memory Fault State";
BA_ "VNSigAllNodes" SG_ 558 CDSP_CmpRAMFltSt 1;
BA_ "SignalType" SG_ 558 CmpSnsrStPktARC "UNM";
BA_ "SignalLongName" SG_ 558 CmpSnsrStPktARC "Compressor Sensor State Packet Alive Rolling Count";
BA_ "VNSigAllNodes" SG_ 558 CmpSnsrStPktARC 1;
BA_ "SignalType" SG_ 558 CSSP_CmpIGBTTpOtRgLSt "ENM";
BA_ "PacketOrder" SG_ 558 CSSP_CmpIGBTTpOtRgLSt 8;
BA_ "SignalLongName" SG_ 558 CSSP_CmpIGBTTpOtRgLSt "Compressor Sensor State Packet : Compressor Insulated Gate Bipolar Transistor Temperature Out of Range Low State";
BA_ "VNSigAllNodes" SG_ 558 CSSP_CmpIGBTTpOtRgLSt 1;
BA_ "SignalType" SG_ 558 CSSP_CmpIGBTTpOtRgHSt "ENM";
BA_ "PacketOrder" SG_ 558 CSSP_CmpIGBTTpOtRgHSt 7;
BA_ "SignalLongName" SG_ 558 CSSP_CmpIGBTTpOtRgHSt "Compressor Sensor State Packet : Compressor Insulated Gate Bipolar Transistor Temperature Out of Range High State";
BA_ "VNSigAllNodes" SG_ 558 CSSP_CmpIGBTTpOtRgHSt 1;
BA_ "SignalType" SG_ 558 CSSP_CmpCPUTmpOtRgLSt "ENM";
BA_ "PacketOrder" SG_ 558 CSSP_CmpCPUTmpOtRgLSt 6;
BA_ "SignalLongName" SG_ 558 CSSP_CmpCPUTmpOtRgLSt "Compressor Sensor State Packet : Compressor Central Processing Unit Temperature Out of Range Low State";
BA_ "VNSigAllNodes" SG_ 558 CSSP_CmpCPUTmpOtRgLSt 1;
BA_ "SignalType" SG_ 558 CSSP_CmpCPUTmpOtRgHSt "ENM";
BA_ "PacketOrder" SG_ 558 CSSP_CmpCPUTmpOtRgHSt 5;
BA_ "SignalLongName" SG_ 558 CSSP_CmpCPUTmpOtRgHSt "Compressor Sensor State Packet : Compressor Central Processing Unit Temperature Out of Range High State";
BA_ "VNSigAllNodes" SG_ 558 CSSP_CmpCPUTmpOtRgHSt 1;
BA_ "SignalType" SG_ 558 CSSP_CmpHVSnsOtRgLSt "ENM";
BA_ "PacketOrder" SG_ 558 CSSP_CmpHVSnsOtRgLSt 4;
BA_ "SignalLongName" SG_ 558 CSSP_CmpHVSnsOtRgLSt "Compressor Sensor State Packet : Compressor High Voltage Sensor Out of Range Low State";
BA_ "VNSigAllNodes" SG_ 558 CSSP_CmpHVSnsOtRgLSt 1;
BA_ "SignalType" SG_ 558 CSSP_CmpHVSnsOtRgHSt "ENM";
BA_ "PacketOrder" SG_ 558 CSSP_CmpHVSnsOtRgHSt 3;
BA_ "SignalLongName" SG_ 558 CSSP_CmpHVSnsOtRgHSt "Compressor Sensor State Packet : Compressor High Voltage Sensor Out of Range High State";
BA_ "VNSigAllNodes" SG_ 558 CSSP_CmpHVSnsOtRgHSt 1;
BA_ "SignalType" SG_ 558 CSSP_CmpPhCrntOtRgLSt "ENM";
BA_ "PacketOrder" SG_ 558 CSSP_CmpPhCrntOtRgLSt 2;
BA_ "SignalLongName" SG_ 558 CSSP_CmpPhCrntOtRgLSt "Compressor Sensor State Packet : Compressor Phase Current Out of Range Low State";
BA_ "VNSigAllNodes" SG_ 558 CSSP_CmpPhCrntOtRgLSt 1;
BA_ "SignalType" SG_ 558 CSSP_CmpPhCrntOtRgHSt "ENM";
BA_ "PacketOrder" SG_ 558 CSSP_CmpPhCrntOtRgHSt 1;
BA_ "SignalLongName" SG_ 558 CSSP_CmpPhCrntOtRgHSt "Compressor Sensor State Packet : Compressor Phase Current Out of Range High State";
BA_ "VNSigAllNodes" SG_ 558 CSSP_CmpPhCrntOtRgHSt 1;
BA_ "SignalType" SG_ 208 WhlSlipRRWhl "UNM";
BA_ "SignalLongName" SG_ 208 WhlSlipRRWhl "Wheel Slip Right Rear Wheel";
BA_ "GenSigStartValue" SG_ 208 WhlSlipRRWhl 32768;
BA_ "VNSigAllNodes" SG_ 208 WhlSlipRRWhl 1;
BA_ "SignalType" SG_ 208 WhlSlipRFWhl "UNM";
BA_ "SignalLongName" SG_ 208 WhlSlipRFWhl "Wheel Slip Right Front Wheel";
BA_ "GenSigStartValue" SG_ 208 WhlSlipRFWhl 32768;
BA_ "VNSigAllNodes" SG_ 208 WhlSlipRFWhl 1;
BA_ "SignalType" SG_ 208 WhlSlipLRWhl "UNM";
BA_ "SignalLongName" SG_ 208 WhlSlipLRWhl "Wheel Slip Left Rear Wheel";
BA_ "GenSigStartValue" SG_ 208 WhlSlipLRWhl 32768;
BA_ "VNSigAllNodes" SG_ 208 WhlSlipLRWhl 1;
BA_ "SignalType" SG_ 208 WhlSlipLFWhl "UNM";
BA_ "SignalLongName" SG_ 208 WhlSlipLFWhl "Wheel Slip Left Front Wheel";
BA_ "GenSigStartValue" SG_ 208 WhlSlipLFWhl 32768;
BA_ "VNSigAllNodes" SG_ 208 WhlSlipLFWhl 1;
BA_ "SignalType" SG_ 663 RdGasFuelDevDisStat "ENM";
BA_ "SignalLongName" SG_ 663 RdGasFuelDevDisStat "Redundant Gaseous Fuel Devices Disable State";
BA_ "VNSigAllNodes" SG_ 663 RdGasFuelDevDisStat 1;
BA_ "SignalType" SG_ 663 RdFInjCtrlMdIFltAct "BLN";
BA_ "SignalLongName" SG_ 663 RdFInjCtrlMdIFltAct "Redundant Fuel Injector Control Module Injection Fault Active";
BA_ "VNSigAllNodes" SG_ 663 RdFInjCtrlMdIFltAct 1;
BA_ "SignalType" SG_ 663 RdDistFuelMdReq "ENM";
BA_ "SignalLongName" SG_ 663 RdDistFuelMdReq "Redundant Distributed Fuel Mode Request";
BA_ "VNSigAllNodes" SG_ 663 RdDistFuelMdReq 1;
BA_ "SignalType" SG_ 663 RdDistFuelMdCmdResRC "UNM";
BA_ "SignalLongName" SG_ 663 RdDistFuelMdCmdResRC "Redundant Distributed Fuel Mode Command Response Rolling Count";
BA_ "VNSigAllNodes" SG_ 663 RdDistFuelMdCmdResRC 1;
BA_ "SignalType" SG_ 663 RdDistFuelMdCmdRes "ENM";
BA_ "SignalLongName" SG_ 663 RdDistFuelMdCmdRes "Redundant Distributed Fuel Mode Command Response";
BA_ "VNSigAllNodes" SG_ 663 RdDistFuelMdCmdRes 1;
BA_ "SignalType" SG_ 663 RdAltFuelSysStat "ENM";
BA_ "SignalLongName" SG_ 663 RdAltFuelSysStat "Redundant Alternative Fuel System Status";
BA_ "VNSigAllNodes" SG_ 663 RdAltFuelSysStat 1;
BA_ "SignalType" SG_ 663 RdAltFuelInjCmdRsp "UNM";
BA_ "SignalLongName" SG_ 663 RdAltFuelInjCmdRsp "Redundant Alternative Fuel Injector Commands Response";
BA_ "VNSigAllNodes" SG_ 663 RdAltFuelInjCmdRsp 1;
BA_ "SignalType" SG_ 663 AltFuelInjRCRstOcc "BLN";
BA_ "SignalLongName" SG_ 663 AltFuelInjRCRstOcc "Alternative Fuel Injected Rolling Count Reset Occurred";
BA_ "VNSigAllNodes" SG_ 663 AltFuelInjRCRstOcc 1;
BA_ "SignalType" SG_ 663 AltFuelInjRC "UNM";
BA_ "SignalLongName" SG_ 663 AltFuelInjRC "Alternative Fuel Injected Rolling Count";
BA_ "VNSigAllNodes" SG_ 663 AltFuelInjRC 1;
BA_ "SignalType" SG_ 1263 BatSOFVolt "UNM";
BA_ "SignalLongName" SG_ 1263 BatSOFVolt "Battery State Of Function Voltage";
BA_ "GenSigStartValue" SG_ 1263 BatSOFVolt 200;
BA_ "VNSigAllNodes" SG_ 1263 BatSOFVolt 1;
BA_ "SignalType" SG_ 1263 BatSOH "UNM";
BA_ "SignalLongName" SG_ 1263 BatSOH "Battery State Of Health";
BA_ "GenSigStartValue" SG_ 1263 BatSOH 203.999928600025;
BA_ "VNSigAllNodes" SG_ 1263 BatSOH 1;
BA_ "SignalType" SG_ 1263 IBSBatSOC "UNM";
BA_ "SignalLongName" SG_ 1263 IBSBatSOC "Intelligent Battery Sensor Battery State of Charge";
BA_ "GenSigStartValue" SG_ 1263 IBSBatSOC 196;
BA_ "VNSigAllNodes" SG_ 1263 IBSBatSOC 1;
BA_ "SignalType" SG_ 1263 BattSOXStat "ENM";
BA_ "SignalLongName" SG_ 1263 BattSOXStat "Battery SOX Status";
BA_ "VNSigAllNodes" SG_ 1263 BattSOXStat 1;
BA_ "SignalType" SG_ 1261 MinCrnkCrnt "UNM";
BA_ "SignalLongName" SG_ 1261 MinCrnkCrnt "Minimum Cranking Current";
BA_ "VNSigAllNodes" SG_ 1261 MinCrnkCrnt 1;
BA_ "SignalType" SG_ 1261 MinCrnkVlt "UNM";
BA_ "SignalLongName" SG_ 1261 MinCrnkVlt "Minimum Cranking Voltage";
BA_ "VNSigAllNodes" SG_ 1261 MinCrnkVlt 1;
BA_ "SignalType" SG_ 1261 MinCrnkCrntVltStat "ENM";
BA_ "SignalLongName" SG_ 1261 MinCrnkCrntVltStat "Minimum Cranking Voltage and Current Status";
BA_ "VNSigAllNodes" SG_ 1261 MinCrnkCrntVltStat 1;
BA_ "SignalType" SG_ 1261 BattTempV "ENM";
BA_ "SignalLongName" SG_ 1261 BattTempV "Battery Temperature Validity";
BA_ "VNSigAllNodes" SG_ 1261 BattTempV 1;
BA_ "SignalType" SG_ 1261 BattTempM "ENM";
BA_ "SignalLongName" SG_ 1261 BattTempM "Battery Temperature Mask";
BA_ "VNSigAllNodes" SG_ 1261 BattTempM 1;
BA_ "SignalType" SG_ 1261 BattTemp "UNM";
BA_ "SignalLongName" SG_ 1261 BattTemp "Battery Temperature";
BA_ "GenSigStartValue" SG_ 1261 BattTemp 65;
BA_ "VNSigAllNodes" SG_ 1261 BattTemp 1;
BA_ "VNSigSLHS_VNReq" SG_ 1259 AllNodesVNA 1;
BA_ "SignalType" SG_ 1259 AllNodesVNA "ENM";
BA_ "SignalLongName" SG_ 1259 AllNodesVNA "All Nodes Virtual Network Activation";
BA_ "VNSigAllNodes" SG_ 1259 AllNodesVNA 1;
BA_ "SignalType" SG_ 1259 NAHrDisChrgM "ENM";
BA_ "SignalLongName" SG_ 1259 NAHrDisChrgM "Net Amp Hours Discharge Mask";
BA_ "VNSigAllNodes" SG_ 1259 NAHrDisChrgM 1;
BA_ "SignalType" SG_ 1259 NAHrDisChrg "UNM";
BA_ "SignalLongName" SG_ 1259 NAHrDisChrg "Net Amp Hours Discharge";
BA_ "VNSigAllNodes" SG_ 1259 NAHrDisChrg 1;
BA_ "SignalType" SG_ 1259 NAHrChgM "ENM";
BA_ "SignalLongName" SG_ 1259 NAHrChgM "Net Amp Hours Charge Mask";
BA_ "VNSigAllNodes" SG_ 1259 NAHrChgM 1;
BA_ "SignalType" SG_ 1259 NAHrChg "UNM";
BA_ "SignalLongName" SG_ 1259 NAHrChg "Net Amp Hours Charge";
BA_ "VNSigAllNodes" SG_ 1259 NAHrChg 1;
BA_ "SignalType" SG_ 1034 CRL_Cnfdnc "ENM";
BA_ "PacketOrder" SG_ 1034 CRL_Cnfdnc 4;
BA_ "SignalLongName" SG_ 1034 CRL_Cnfdnc "Curvature Right Line : Confidence";
BA_ "VNSigAllNodes" SG_ 1034 CRL_Cnfdnc 1;
BA_ "SignalType" SG_ 1034 CRL_ViewRng "UNM";
BA_ "PacketOrder" SG_ 1034 CRL_ViewRng 3;
BA_ "SignalLongName" SG_ 1034 CRL_ViewRng "Curvature Right Line : View Range";
BA_ "VNSigAllNodes" SG_ 1034 CRL_ViewRng 1;
BA_ "SignalType" SG_ 1034 CRL_CoefdA "SNM";
BA_ "PacketOrder" SG_ 1034 CRL_CoefdA 2;
BA_ "SignalLongName" SG_ 1034 CRL_CoefdA "Curvature Right Line : Coefficient dA";
BA_ "VNSigAllNodes" SG_ 1034 CRL_CoefdA 1;
BA_ "SignalType" SG_ 1034 CRL_CoefA "SNM";
BA_ "PacketOrder" SG_ 1034 CRL_CoefA 1;
BA_ "SignalLongName" SG_ 1034 CRL_CoefA "Curvature Right Line : Coefficient A";
BA_ "VNSigAllNodes" SG_ 1034 CRL_CoefA 1;
BA_ "SignalType" SG_ 1033 CLL_Cnfdnc "ENM";
BA_ "PacketOrder" SG_ 1033 CLL_Cnfdnc 4;
BA_ "SignalLongName" SG_ 1033 CLL_Cnfdnc "Curvature Left Line : Confidence";
BA_ "VNSigAllNodes" SG_ 1033 CLL_Cnfdnc 1;
BA_ "SignalType" SG_ 1033 CLL_ViewRng "UNM";
BA_ "PacketOrder" SG_ 1033 CLL_ViewRng 3;
BA_ "SignalLongName" SG_ 1033 CLL_ViewRng "Curvature Left Line : View Range";
BA_ "VNSigAllNodes" SG_ 1033 CLL_ViewRng 1;
BA_ "SignalType" SG_ 1033 CLL_CoefdA "SNM";
BA_ "PacketOrder" SG_ 1033 CLL_CoefdA 2;
BA_ "SignalLongName" SG_ 1033 CLL_CoefdA "Curvature Left Line : Coefficient dA";
BA_ "VNSigAllNodes" SG_ 1033 CLL_CoefdA 1;
BA_ "SignalType" SG_ 1033 CLL_CoefA "SNM";
BA_ "PacketOrder" SG_ 1033 CLL_CoefA 1;
BA_ "SignalLongName" SG_ 1033 CLL_CoefA "Curvature Left Line : Coefficient A";
BA_ "VNSigAllNodes" SG_ 1033 CLL_CoefA 1;
BA_ "SignalType" SG_ 1013 TransRgDiagFltPVal "UNM";
BA_ "SignalLongName" SG_ 1013 TransRgDiagFltPVal "Transmission Range Diagnostic Fault Protection Value";
BA_ "VNSigAllNodes" SG_ 1013 TransRgDiagFltPVal 1;
BA_ "SignalType" SG_ 1013 TrsRgDgFltARC "UNM";
BA_ "SignalLongName" SG_ 1013 TrsRgDgFltARC "Transmission Range Diagnostic Fault Alive Rolling Count";
BA_ "VNSigAllNodes" SG_ 1013 TrsRgDgFltARC 1;
BA_ "PacketOrder" SG_ 1013 TRDF_TransPrkRgDgFlt 1;
BA_ "SignalType" SG_ 1013 TRDF_TransPrkRgDgFlt "BLN";
BA_ "SignalLongName" SG_ 1013 TRDF_TransPrkRgDgFlt "Transmission Range Diagnostic Fault : Transmission Park Range Diagnostic Fault";
BA_ "VNSigAllNodes" SG_ 1013 TRDF_TransPrkRgDgFlt 1;
BA_ "PacketOrder" SG_ 1013 TRDF_TrsFwDrvRgDgFlt 4;
BA_ "SignalType" SG_ 1013 TRDF_TrsFwDrvRgDgFlt "BLN";
BA_ "SignalLongName" SG_ 1013 TRDF_TrsFwDrvRgDgFlt "Transmission Range Diagnostic Fault : Transmission Forward Drive Range Diagnostic Fault";
BA_ "VNSigAllNodes" SG_ 1013 TRDF_TrsFwDrvRgDgFlt 1;
BA_ "PacketOrder" SG_ 1013 TRDF_TransNeutRgDgFlt 3;
BA_ "SignalType" SG_ 1013 TRDF_TransNeutRgDgFlt "BLN";
BA_ "SignalLongName" SG_ 1013 TRDF_TransNeutRgDgFlt "Transmission Range Diagnostic Fault : Transmission Neutral Range Diagnostic Fault";
BA_ "VNSigAllNodes" SG_ 1013 TRDF_TransNeutRgDgFlt 1;
BA_ "PacketOrder" SG_ 1013 TRDF_TransRvsRgDgFlt 2;
BA_ "SignalType" SG_ 1013 TRDF_TransRvsRgDgFlt "BLN";
BA_ "SignalLongName" SG_ 1013 TRDF_TransRvsRgDgFlt "Transmission Range Diagnostic Fault : Transmission Reverse Range Diagnostic Fault";
BA_ "VNSigAllNodes" SG_ 1013 TRDF_TransRvsRgDgFlt 1;
BA_ "SignalType" SG_ 1013 TrnRqHRBkCtlTgtVSpd "ENM";
BA_ "SignalLongName" SG_ 1013 TrnRqHRBkCtlTgtVSpd "Transmission Requested Hill Rollback Control Target Vehicle Speed";
BA_ "VNSigAllNodes" SG_ 1013 TrnRqHRBkCtlTgtVSpd 1;
BA_ "SignalType" SG_ 1013 TransReqHSAAval "ENM";
BA_ "SignalLongName" SG_ 1013 TransReqHSAAval "Transmission Requested Hill Start Assist Availability";
BA_ "VNSigAllNodes" SG_ 1013 TransReqHSAAval 1;
BA_ "SignalType" SG_ 425 TransClch5FlTm "UNM";
BA_ "SignalLongName" SG_ 425 TransClch5FlTm "Transmission Clutch 5 Fill Time";
BA_ "VNSigAllNodes" SG_ 425 TransClch5FlTm 1;
BA_ "SignalType" SG_ 425 TransCltch5EstTrq "UNM";
BA_ "SignalLongName" SG_ 425 TransCltch5EstTrq "Transmission Clutch 5 Estimated Torque";
BA_ "VNSigAllNodes" SG_ 425 TransCltch5EstTrq 1;
BA_ "SignalType" SG_ 425 TransClch5MaxEngy "UNM";
BA_ "SignalLongName" SG_ 425 TransClch5MaxEngy "Transmission Clutch 5 Maximum Energy";
BA_ "VNSigAllNodes" SG_ 425 TransClch5MaxEngy 1;
BA_ "SignalType" SG_ 425 TransClch5FlAch "BLN";
BA_ "SignalLongName" SG_ 425 TransClch5FlAch "Transmission Clutch 5 Fill Achieved";
BA_ "VNSigAllNodes" SG_ 425 TransClch5FlAch 1;
BA_ "SignalType" SG_ 425 TransClch4FlTm "UNM";
BA_ "SignalLongName" SG_ 425 TransClch4FlTm "Transmission Clutch 4 Fill Time";
BA_ "VNSigAllNodes" SG_ 425 TransClch4FlTm 1;
BA_ "SignalType" SG_ 425 TransClch4EstTorq "UNM";
BA_ "SignalLongName" SG_ 425 TransClch4EstTorq "Transmission Clutch 4 Estimated Torque";
BA_ "VNSigAllNodes" SG_ 425 TransClch4EstTorq 1;
BA_ "SignalType" SG_ 425 TransClch4MaxEnrgy "UNM";
BA_ "SignalLongName" SG_ 425 TransClch4MaxEnrgy "Transmission Clutch 4 Maximum Energy";
BA_ "VNSigAllNodes" SG_ 425 TransClch4MaxEnrgy 1;
BA_ "SignalType" SG_ 425 TransClch4FlAch "BLN";
BA_ "SignalLongName" SG_ 425 TransClch4FlAch "Transmission Clutch 4 Fill Achieved";
BA_ "VNSigAllNodes" SG_ 425 TransClch4FlAch 1;
BA_ "SignalType" SG_ 424 TransClch3FlTm "UNM";
BA_ "SignalLongName" SG_ 424 TransClch3FlTm "Transmission Clutch 3 Fill Time";
BA_ "VNSigAllNodes" SG_ 424 TransClch3FlTm 1;
BA_ "SignalType" SG_ 424 TransClch3EstTorq "UNM";
BA_ "SignalLongName" SG_ 424 TransClch3EstTorq "Transmission Clutch 3 Estimated Torque";
BA_ "VNSigAllNodes" SG_ 424 TransClch3EstTorq 1;
BA_ "SignalType" SG_ 424 TransClch3MaxEnrgy "UNM";
BA_ "SignalLongName" SG_ 424 TransClch3MaxEnrgy "Transmission Clutch 3 Maximum Energy";
BA_ "VNSigAllNodes" SG_ 424 TransClch3MaxEnrgy 1;
BA_ "SignalType" SG_ 424 TransClch3FlAch "BLN";
BA_ "SignalLongName" SG_ 424 TransClch3FlAch "Transmission Clutch 3 Fill Achieved";
BA_ "VNSigAllNodes" SG_ 424 TransClch3FlAch 1;
BA_ "SignalType" SG_ 424 TransClch2FlTm "UNM";
BA_ "SignalLongName" SG_ 424 TransClch2FlTm "Transmission Clutch 2 Fill Time";
BA_ "VNSigAllNodes" SG_ 424 TransClch2FlTm 1;
BA_ "SignalType" SG_ 424 TransClch2EstTorq "UNM";
BA_ "SignalLongName" SG_ 424 TransClch2EstTorq "Transmission Clutch 2 Estimated Torque";
BA_ "VNSigAllNodes" SG_ 424 TransClch2EstTorq 1;
BA_ "SignalType" SG_ 424 TransClch2MaxEnrgy "UNM";
BA_ "SignalLongName" SG_ 424 TransClch2MaxEnrgy "Transmission Clutch 2 Maximum Energy";
BA_ "VNSigAllNodes" SG_ 424 TransClch2MaxEnrgy 1;
BA_ "SignalType" SG_ 424 TransClch2FlAch "BLN";
BA_ "SignalLongName" SG_ 424 TransClch2FlAch "Transmission Clutch 2 Fill Achieved";
BA_ "VNSigAllNodes" SG_ 424 TransClch2FlAch 1;
BA_ "SignalType" SG_ 324 ActVbnCtrlMlfIO "BLN";
BA_ "SignalLongName" SG_ 324 ActVbnCtrlMlfIO "Active Vibration Control Malfunction Indication On";
BA_ "VNSigAllNodes" SG_ 324 ActVbnCtrlMlfIO 1;
BA_ "SignalType" SG_ 844 IMUProtYawRtM "ENM";
BA_ "SignalLongName" SG_ 844 IMUProtYawRtM "Inertial Measurement Unit Protected Yaw Rate Mask";
BA_ "VNSigAllNodes" SG_ 844 IMUProtYawRtM 1;
BA_ "SignalType" SG_ 844 IMUProtYawRt "SNM";
BA_ "SignalLongName" SG_ 844 IMUProtYawRt "Inertial Measurement Unit Protected Yaw Rate";
BA_ "VNSigAllNodes" SG_ 844 IMUProtYawRt 1;
BA_ "SignalType" SG_ 844 IMUProtLonAccM "ENM";
BA_ "SignalLongName" SG_ 844 IMUProtLonAccM "Inertial Measurement Unit Protected Longitudinal Acceleration Mask";
BA_ "VNSigAllNodes" SG_ 844 IMUProtLonAccM 1;
BA_ "SignalType" SG_ 844 IMUProtLonAcc "SNM";
BA_ "SignalLongName" SG_ 844 IMUProtLonAcc "Inertial Measurement Unit Protected Longitudinal Acceleration";
BA_ "VNSigAllNodes" SG_ 844 IMUProtLonAcc 1;
BA_ "SignalType" SG_ 844 IMUProtLatAccM "ENM";
BA_ "SignalLongName" SG_ 844 IMUProtLatAccM "Inertial Measurement Unit Protected Lateral Acceleration Mask";
BA_ "VNSigAllNodes" SG_ 844 IMUProtLatAccM 1;
BA_ "SignalType" SG_ 844 IMUProtLatAcc "SNM";
BA_ "SignalLongName" SG_ 844 IMUProtLatAcc "Inertial Measurement Unit Protected Lateral Acceleration";
BA_ "VNSigAllNodes" SG_ 844 IMUProtLatAcc 1;
BA_ "SignalType" SG_ 844 IMUProtChksum "UNM";
BA_ "SignalLongName" SG_ 844 IMUProtChksum "Inertial Measurement Unit Protected Checksum";
BA_ "VNSigAllNodes" SG_ 844 IMUProtChksum 1;
BA_ "SignalType" SG_ 844 IMUProtARC "UNM";
BA_ "SignalLongName" SG_ 844 IMUProtARC "Inertial Measurement Unit Protected Alive Rolling Count";
BA_ "VNSigAllNodes" SG_ 844 IMUProtARC 1;
BA_ "SignalType" SG_ 308 PFAS_SrvPedAlrtIO "BLN";
BA_ "PacketOrder" SG_ 308 PFAS_SrvPedAlrtIO 7;
BA_ "SignalLongName" SG_ 308 PFAS_SrvPedAlrtIO "Pedestrian Friendly Alert Status : Service Pedestrian Friendly Alert Indication On";
BA_ "VNSigAllNodes" SG_ 308 PFAS_SrvPedAlrtIO 1;
BA_ "SignalType" SG_ 308 PFAS_PFASysStat "ENM";
BA_ "PacketOrder" SG_ 308 PFAS_PFASysStat 6;
BA_ "SignalLongName" SG_ 308 PFAS_PFASysStat "Pedestrian Friendly Alert Status : Pedestrian Friendly Alert System Status";
BA_ "VNSigAllNodes" SG_ 308 PFAS_PFASysStat 1;
BA_ "SignalType" SG_ 308 PFAS_PFASndVolCtrl "UNM";
BA_ "PacketOrder" SG_ 308 PFAS_PFASndVolCtrl 5;
BA_ "SignalLongName" SG_ 308 PFAS_PFASndVolCtrl "Pedestrian Friendly Alert Status : Pedestrian Friendly Alert Sound Volume Control";
BA_ "VNSigAllNodes" SG_ 308 PFAS_PFASndVolCtrl 1;
BA_ "SignalType" SG_ 308 PFAS_PFASndGenEn "BLN";
BA_ "PacketOrder" SG_ 308 PFAS_PFASndGenEn 1;
BA_ "SignalLongName" SG_ 308 PFAS_PFASndGenEn "Pedestrian Friendly Alert Status : Pedestrian Friendly Alert Sound Generation Enable";
BA_ "VNSigAllNodes" SG_ 308 PFAS_PFASndGenEn 1;
BA_ "SignalType" SG_ 308 PFAS_PFARevSnd "ENM";
BA_ "PacketOrder" SG_ 308 PFAS_PFARevSnd 3;
BA_ "SignalLongName" SG_ 308 PFAS_PFARevSnd "Pedestrian Friendly Alert Status : Pedestrian Friendly Alert Reverse Sound";
BA_ "VNSigAllNodes" SG_ 308 PFAS_PFARevSnd 1;
BA_ "SignalType" SG_ 308 PFAS_PFAFwdSnd "ENM";
BA_ "PacketOrder" SG_ 308 PFAS_PFAFwdSnd 2;
BA_ "SignalLongName" SG_ 308 PFAS_PFAFwdSnd "Pedestrian Friendly Alert Status : Pedestrian Friendly Alert Forward Sound";
BA_ "VNSigAllNodes" SG_ 308 PFAS_PFAFwdSnd 1;
BA_ "SignalType" SG_ 308 PFAS_PFACrsOvrSpd "UNM";
BA_ "PacketOrder" SG_ 308 PFAS_PFACrsOvrSpd 4;
BA_ "SignalLongName" SG_ 308 PFAS_PFACrsOvrSpd "Pedestrian Friendly Alert Status : Pedestrian Friendly Alert Crossover Speed";
BA_ "VNSigAllNodes" SG_ 308 PFAS_PFACrsOvrSpd 1;
BA_ "SignalType" SG_ 308 PedFrndlyAlrtCsSetAvl "BLN";
BA_ "SignalLongName" SG_ 308 PedFrndlyAlrtCsSetAvl "Pedestrian Friendly Alert Customization Setting Available";
BA_ "VNSigAllNodes" SG_ 308 PedFrndlyAlrtCsSetAvl 1;
BA_ "SignalType" SG_ 308 PedFrndlyAlrtCsCrStVal "ENM";
BA_ "SignalLongName" SG_ 308 PedFrndlyAlrtCsCrStVal "Pedestrian Friendly Alert Customization Current Setting Value";
BA_ "VNSigAllNodes" SG_ 308 PedFrndlyAlrtCsCrStVal 1;
BA_ "SignalType" SG_ 806 DCCnvStblznErrIO "BLN";
BA_ "SignalLongName" SG_ 806 DCCnvStblznErrIO "DC Converter Stabilization Error Indication On";
BA_ "VNSigAllNodes" SG_ 806 DCCnvStblznErrIO 1;
BA_ "SignalType" SG_ 426 EngPstnSnsngOpMode "ENM";
BA_ "SignalLongName" SG_ 426 EngPstnSnsngOpMode "Engine Position Sensing Operating Mode";
BA_ "VNSigAllNodes" SG_ 426 EngPstnSnsngOpMode 1;
BA_ "SignalType" SG_ 426 AuxTransPrsCmndOn "BLN";
BA_ "SignalLongName" SG_ 426 AuxTransPrsCmndOn "Auxiliary Transmission Pressure Commanded On";
BA_ "VNSigAllNodes" SG_ 426 AuxTransPrsCmndOn 1;
BA_ "SignalType" SG_ 426 EVTCS_CmdTrqCapMd "ENM";
BA_ "PacketOrder" SG_ 426 EVTCS_CmdTrqCapMd 2;
BA_ "SignalLongName" SG_ 426 EVTCS_CmdTrqCapMd "Engine Variable Torque Capacity Status : Commanded Torque Capacity Mode";
BA_ "VNSigAllNodes" SG_ 426 EVTCS_CmdTrqCapMd 1;
BA_ "SignalType" SG_ 426 EVTCS_CrntTrqCapMd "ENM";
BA_ "PacketOrder" SG_ 426 EVTCS_CrntTrqCapMd 1;
BA_ "SignalLongName" SG_ 426 EVTCS_CrntTrqCapMd "Engine Variable Torque Capacity Status : Current Torque Capacity Mode";
BA_ "VNSigAllNodes" SG_ 426 EVTCS_CrntTrqCapMd 1;
BA_ "SignalType" SG_ 426 EngPrdctStdyStTorq "UNM";
BA_ "SignalLongName" SG_ 426 EngPrdctStdyStTorq "Engine Predicted Steady State Torque";
BA_ "VNSigAllNodes" SG_ 426 EngPrdctStdyStTorq 1;
BA_ "SignalType" SG_ 426 EngPrdctStdyStTorqV "ENM";
BA_ "SignalLongName" SG_ 426 EngPrdctStdyStTorqV "Engine Predicted Steady State Torque Validity";
BA_ "VNSigAllNodes" SG_ 426 EngPrdctStdyStTorqV 1;
BA_ "SignalType" SG_ 426 CrnkShftTrqMinOffCapV "ENM";
BA_ "SignalLongName" SG_ 426 CrnkShftTrqMinOffCapV "Crankshaft Torque Minimum Off Capacity Validity";
BA_ "VNSigAllNodes" SG_ 426 CrnkShftTrqMinOffCapV 1;
BA_ "SignalType" SG_ 426 CrnkShftTrqMinOffCap "UNM";
BA_ "SignalLongName" SG_ 426 CrnkShftTrqMinOffCap "Crankshaft Torque Minimum Off Capacity";
BA_ "VNSigAllNodes" SG_ 426 CrnkShftTrqMinOffCap 1;
BA_ "SignalType" SG_ 426 CrksftTqMinRunImCapV "ENM";
BA_ "SignalLongName" SG_ 426 CrksftTqMinRunImCapV "Crankshaft Torque Minimum Run Immediate Capacity Validity";
BA_ "VNSigAllNodes" SG_ 426 CrksftTqMinRunImCapV 1;
BA_ "SignalType" SG_ 426 CrksftTqMinRunImCap "UNM";
BA_ "SignalLongName" SG_ 426 CrksftTqMinRunImCap "Crankshaft Torque Minimum Run Immediate Capacity";
BA_ "VNSigAllNodes" SG_ 426 CrksftTqMinRunImCap 1;
BA_ "SignalType" SG_ 1231 DslExhFluidDistTIndcmt "UNM";
BA_ "SignalLongName" SG_ 1231 DslExhFluidDistTIndcmt "Diesel Exhaust Fluid Distance to Inducement";
BA_ "VNSigAllNodes" SG_ 1231 DslExhFluidDistTIndcmt 1;
BA_ "SignalType" SG_ 1231 DslExhFluidLvlPrcntV "ENM";
BA_ "SignalLongName" SG_ 1231 DslExhFluidLvlPrcntV "Diesel Exhaust Fluid Level Percent Validity";
BA_ "VNSigAllNodes" SG_ 1231 DslExhFluidLvlPrcntV 1;
BA_ "SignalType" SG_ 1231 DslExhFluidLvlPrcnt "UNM";
BA_ "SignalLongName" SG_ 1231 DslExhFluidLvlPrcnt "Diesel Exhaust Fluid Level Percent";
BA_ "VNSigAllNodes" SG_ 1231 DslExhFluidLvlPrcnt 1;
BA_ "SignalType" SG_ 963 CltTmpCntlMdEmRMAct "BLN";
BA_ "SignalLongName" SG_ 963 CltTmpCntlMdEmRMAct "Coolant Temperature Control Module Emissions Related Malfunction Active";
BA_ "VNSigAllNodes" SG_ 963 CltTmpCntlMdEmRMAct 1;
BA_ "SignalType" SG_ 963 CTCMERDTC_SysDes "ENM";
BA_ "PacketOrder" SG_ 963 CTCMERDTC_SysDes 1;
BA_ "SignalLongName" SG_ 963 CTCMERDTC_SysDes "Coolant Temperature Control Module Emissions Related DTC : System Designator";
BA_ "VNSigAllNodes" SG_ 963 CTCMERDTC_SysDes 1;
BA_ "SignalType" SG_ 963 CTCMERDTC_CdNum "UNM";
BA_ "PacketOrder" SG_ 963 CTCMERDTC_CdNum 2;
BA_ "SignalLongName" SG_ 963 CTCMERDTC_CdNum "Coolant Temperature Control Module Emissions Related DTC : Code Number";
BA_ "VNSigAllNodes" SG_ 963 CTCMERDTC_CdNum 1;
BA_ "SignalType" SG_ 955 RHCS_RdctHtrCCurrV "ENM";
BA_ "PacketOrder" SG_ 955 RHCS_RdctHtrCCurrV 3;
BA_ "SignalLongName" SG_ 955 RHCS_RdctHtrCCurrV "Reductant Heater Circuits Status : Reductant Heater C Current Validity";
BA_ "VNSigAllNodes" SG_ 955 RHCS_RdctHtrCCurrV 1;
BA_ "SignalType" SG_ 955 RHCS_RdctHtrBCurrV "ENM";
BA_ "PacketOrder" SG_ 955 RHCS_RdctHtrBCurrV 2;
BA_ "SignalLongName" SG_ 955 RHCS_RdctHtrBCurrV "Reductant Heater Circuits Status : Reductant Heater B Current Validity";
BA_ "VNSigAllNodes" SG_ 955 RHCS_RdctHtrBCurrV 1;
BA_ "SignalType" SG_ 955 RHCS_RdctHtrACurrV "ENM";
BA_ "PacketOrder" SG_ 955 RHCS_RdctHtrACurrV 1;
BA_ "SignalLongName" SG_ 955 RHCS_RdctHtrACurrV "Reductant Heater Circuits Status : Reductant Heater A Current Validity";
BA_ "VNSigAllNodes" SG_ 955 RHCS_RdctHtrACurrV 1;
BA_ "SignalType" SG_ 955 RdctHtrCrntFdbckRC "UNM";
BA_ "SignalLongName" SG_ 955 RdctHtrCrntFdbckRC "Reductant Heaters Current Feedback Alive Rolling Count";
BA_ "VNSigAllNodes" SG_ 955 RdctHtrCrntFdbckRC 1;
BA_ "SignalType" SG_ 955 RdctHtrCctStatPV "UNM";
BA_ "SignalLongName" SG_ 955 RdctHtrCctStatPV "Reductant Heater Circuits Status Protection Value";
BA_ "VNSigAllNodes" SG_ 955 RdctHtrCctStatPV 1;
BA_ "SignalType" SG_ 955 RdctHtrCCrntFdbckPVa "UNM";
BA_ "SignalLongName" SG_ 955 RdctHtrCCrntFdbckPVa "Reductant Heater C Current Feedback Protection Value";
BA_ "VNSigAllNodes" SG_ 955 RdctHtrCCrntFdbckPVa 1;
BA_ "SignalType" SG_ 955 RdctHtrBCrntFdbckPVa "UNM";
BA_ "SignalLongName" SG_ 955 RdctHtrBCrntFdbckPVa "Reductant Heater B Current Feedback Protection Value";
BA_ "VNSigAllNodes" SG_ 955 RdctHtrBCrntFdbckPVa 1;
BA_ "SignalType" SG_ 955 RdctHtrACrntFdbckPVa "UNM";
BA_ "SignalLongName" SG_ 955 RdctHtrACrntFdbckPVa "Reductant Heater A Current Feedback Protection Value";
BA_ "VNSigAllNodes" SG_ 955 RdctHtrACrntFdbckPVa 1;
BA_ "SignalType" SG_ 955 RdctHtrCCrntFdbck "UNM";
BA_ "SignalLongName" SG_ 955 RdctHtrCCrntFdbck "Reductant Heater C Current Feedback";
BA_ "VNSigAllNodes" SG_ 955 RdctHtrCCrntFdbck 1;
BA_ "SignalType" SG_ 955 RdctHtrBCrntFdbck "UNM";
BA_ "SignalLongName" SG_ 955 RdctHtrBCrntFdbck "Reductant Heater B Current Feedback";
BA_ "VNSigAllNodes" SG_ 955 RdctHtrBCrntFdbck 1;
BA_ "SignalType" SG_ 955 RdctHtrACrntFdbck "UNM";
BA_ "SignalLongName" SG_ 955 RdctHtrACrntFdbck "Reductant Heater A Current Feedback";
BA_ "VNSigAllNodes" SG_ 955 RdctHtrACrntFdbck 1;
BA_ "SignalType" SG_ 423 TrnsInpDvcStat "ENM";
BA_ "SignalLongName" SG_ 423 TrnsInpDvcStat "Transmission Input Device Status";
BA_ "VNSigAllNodes" SG_ 423 TrnsInpDvcStat 1;
BA_ "SignalType" SG_ 423 TrnsPTSysShtdwnRq "BLN";
BA_ "SignalLongName" SG_ 423 TrnsPTSysShtdwnRq "Transmission Powertrain System Shutdown Requested";
BA_ "VNSigAllNodes" SG_ 423 TrnsPTSysShtdwnRq 1;
BA_ "SignalType" SG_ 423 TransClch1FlTm "UNM";
BA_ "SignalLongName" SG_ 423 TransClch1FlTm "Transmission Clutch 1 Fill Time";
BA_ "VNSigAllNodes" SG_ 423 TransClch1FlTm 1;
BA_ "SignalType" SG_ 423 TransClch1EstTorq "UNM";
BA_ "SignalLongName" SG_ 423 TransClch1EstTorq "Transmission Clutch 1 Estimated Torque";
BA_ "VNSigAllNodes" SG_ 423 TransClch1EstTorq 1;
BA_ "SignalType" SG_ 423 TransClch1MaxEnrgy "UNM";
BA_ "SignalLongName" SG_ 423 TransClch1MaxEnrgy "Transmission Clutch 1 Maximum Energy";
BA_ "VNSigAllNodes" SG_ 423 TransClch1MaxEnrgy 1;
BA_ "SignalType" SG_ 423 TransClch1FlAch "BLN";
BA_ "SignalLongName" SG_ 423 TransClch1FlAch "Transmission Clutch 1 Fill Achieved";
BA_ "VNSigAllNodes" SG_ 423 TransClch1FlAch 1;
BA_ "SignalType" SG_ 423 TransHydrlcDfltgAct "BLN";
BA_ "SignalLongName" SG_ 423 TransHydrlcDfltgAct "Transmission Hydraulic Defaulting Active";
BA_ "VNSigAllNodes" SG_ 423 TransHydrlcDfltgAct 1;
BA_ "SignalType" SG_ 423 TCFS_Cltch5FltStat "ENM";
BA_ "PacketOrder" SG_ 423 TCFS_Cltch5FltStat 5;
BA_ "SignalLongName" SG_ 423 TCFS_Cltch5FltStat "Transmission Clutch Fault Status : Clutch 5 Fault Status";
BA_ "VNSigAllNodes" SG_ 423 TCFS_Cltch5FltStat 1;
BA_ "SignalType" SG_ 423 TCFS_Cltch4FltStat "ENM";
BA_ "PacketOrder" SG_ 423 TCFS_Cltch4FltStat 4;
BA_ "SignalLongName" SG_ 423 TCFS_Cltch4FltStat "Transmission Clutch Fault Status : Clutch 4 Fault Status";
BA_ "VNSigAllNodes" SG_ 423 TCFS_Cltch4FltStat 1;
BA_ "SignalType" SG_ 423 TCFS_Cltch3FltStat "ENM";
BA_ "PacketOrder" SG_ 423 TCFS_Cltch3FltStat 3;
BA_ "SignalLongName" SG_ 423 TCFS_Cltch3FltStat "Transmission Clutch Fault Status : Clutch 3 Fault Status";
BA_ "VNSigAllNodes" SG_ 423 TCFS_Cltch3FltStat 1;
BA_ "SignalType" SG_ 423 TCFS_Cltch2FltStat "ENM";
BA_ "PacketOrder" SG_ 423 TCFS_Cltch2FltStat 2;
BA_ "SignalLongName" SG_ 423 TCFS_Cltch2FltStat "Transmission Clutch Fault Status : Clutch 2 Fault Status";
BA_ "VNSigAllNodes" SG_ 423 TCFS_Cltch2FltStat 1;
BA_ "SignalType" SG_ 423 TCFS_Cltch1FltStat "ENM";
BA_ "PacketOrder" SG_ 423 TCFS_Cltch1FltStat 1;
BA_ "SignalLongName" SG_ 423 TCFS_Cltch1FltStat "Transmission Clutch Fault Status : Clutch 1 Fault Status";
BA_ "VNSigAllNodes" SG_ 423 TCFS_Cltch1FltStat 1;
BA_ "SignalType" SG_ 423 TCAS_Cltch5AvlbltyStat "ENM";
BA_ "PacketOrder" SG_ 423 TCAS_Cltch5AvlbltyStat 5;
BA_ "SignalLongName" SG_ 423 TCAS_Cltch5AvlbltyStat "Transmission Clutch Availability Status : Clutch 5 Availability Status";
BA_ "VNSigAllNodes" SG_ 423 TCAS_Cltch5AvlbltyStat 1;
BA_ "SignalType" SG_ 423 TCAS_Cltch4AvlbltyStat "ENM";
BA_ "PacketOrder" SG_ 423 TCAS_Cltch4AvlbltyStat 4;
BA_ "SignalLongName" SG_ 423 TCAS_Cltch4AvlbltyStat "Transmission Clutch Availability Status : Clutch 4 Availability Status";
BA_ "VNSigAllNodes" SG_ 423 TCAS_Cltch4AvlbltyStat 1;
BA_ "SignalType" SG_ 423 TCAS_Cltch3AvlbltyStat "ENM";
BA_ "PacketOrder" SG_ 423 TCAS_Cltch3AvlbltyStat 3;
BA_ "SignalLongName" SG_ 423 TCAS_Cltch3AvlbltyStat "Transmission Clutch Availability Status : Clutch 3 Availability Status";
BA_ "VNSigAllNodes" SG_ 423 TCAS_Cltch3AvlbltyStat 1;
BA_ "SignalType" SG_ 423 TCAS_Cltch2AvlbltyStat "ENM";
BA_ "PacketOrder" SG_ 423 TCAS_Cltch2AvlbltyStat 2;
BA_ "SignalLongName" SG_ 423 TCAS_Cltch2AvlbltyStat "Transmission Clutch Availability Status : Clutch 2 Availability Status";
BA_ "VNSigAllNodes" SG_ 423 TCAS_Cltch2AvlbltyStat 1;
BA_ "SignalType" SG_ 423 TCAS_Cltch1AvlbltyStat "ENM";
BA_ "PacketOrder" SG_ 423 TCAS_Cltch1AvlbltyStat 1;
BA_ "SignalLongName" SG_ 423 TCAS_Cltch1AvlbltyStat "Transmission Clutch Availability Status : Clutch 1 Availability Status";
BA_ "VNSigAllNodes" SG_ 423 TCAS_Cltch1AvlbltyStat 1;
BA_ "VNSigSLHSSharedDiagnostic" SG_ 2034 DgnInf 1;
BA_ "SignalType" SG_ 2034 DgnInf "UNM";
BA_ "SignalLongName" SG_ 2034 DgnInf "Diagnostic Information";
BA_ "VNSigAllNodes" SG_ 2034 DgnInf 1;
BA_ "VNSigSLHSSharedDiagnostic" SG_ 2032 DgnInf 1;
BA_ "SignalType" SG_ 2032 DgnInf "UNM";
BA_ "SignalLongName" SG_ 2032 DgnInf "Diagnostic Information";
BA_ "VNSigAllNodes" SG_ 2032 DgnInf 1;
BA_REL_ "GenSigSuprvResp" BU_SG_REL_ ICCM_HS SG_ 705 TransActlRng 1;
BA_REL_ "GenSigTimeoutMsg" BU_SG_REL_ ICCM_HS SG_ 705 TransActlRng 705;
BA_REL_ "GenSigTimeoutTime" BU_SG_REL_ ICCM_HS SG_ 705 TransActlRng 250;
BA_REL_ "GenSigSuprvResp" BU_SG_REL_ TRCM_HS SG_ 503 ElcTransRngRq 1;
BA_REL_ "GenSigTimeoutMsg" BU_SG_REL_ TRCM_HS SG_ 503 ElcTransRngRq 503;
BA_REL_ "GenSigTimeoutTime" BU_SG_REL_ TRCM_HS SG_ 503 ElcTransRngRq 250;
BA_REL_ "GenSigSuprvResp" BU_SG_REL_ TCM_HS SG_ 503 ElcTransRngRq 1;
BA_REL_ "GenSigTimeoutMsg" BU_SG_REL_ TCM_HS SG_ 503 ElcTransRngRq 503;
BA_REL_ "GenSigTimeoutTime" BU_SG_REL_ TCM_HS SG_ 503 ElcTransRngRq 250;
BA_REL_ "GenSigSuprvResp" BU_SG_REL_ EBCM_OBD_HS SG_ 872 ESBR_AutoBrkgRqTyp 1;
BA_REL_ "GenSigTimeoutMsg" BU_SG_REL_ EBCM_OBD_HS SG_ 872 ESBR_AutoBrkgRqTyp 872;
BA_REL_ "GenSigTimeoutTime" BU_SG_REL_ EBCM_OBD_HS SG_ 872 ESBR_AutoBrkgRqTyp 250;
BA_REL_ "GenSigSuprvResp" BU_SG_REL_ EBCM_HS SG_ 872 ESBR_AutoBrkgRqTyp 1;
BA_REL_ "GenSigTimeoutMsg" BU_SG_REL_ EBCM_HS SG_ 872 ESBR_AutoBrkgRqTyp 872;
BA_REL_ "GenSigTimeoutTime" BU_SG_REL_ EBCM_HS SG_ 872 ESBR_AutoBrkgRqTyp 250;
BA_REL_ "GenSigSuprvResp" BU_SG_REL_ EPB_HS SG_ 872 ESBR_AutoBrkgRqTyp 1;
BA_REL_ "GenSigTimeoutMsg" BU_SG_REL_ EPB_HS SG_ 872 ESBR_AutoBrkgRqTyp 872;
BA_REL_ "GenSigTimeoutTime" BU_SG_REL_ EPB_HS SG_ 872 ESBR_AutoBrkgRqTyp 250;
BA_REL_ "GenSigSuprvResp" BU_SG_REL_ EBCM_OBD_HS SG_ 872 ESBR_AutoBrkgRqd 1;
BA_REL_ "GenSigTimeoutMsg" BU_SG_REL_ EBCM_OBD_HS SG_ 872 ESBR_AutoBrkgRqd 872;
BA_REL_ "GenSigTimeoutTime" BU_SG_REL_ EBCM_OBD_HS SG_ 872 ESBR_AutoBrkgRqd 250;
BA_REL_ "GenSigSuprvResp" BU_SG_REL_ EBCM_HS SG_ 872 ESBR_AutoBrkgRqd 1;
BA_REL_ "GenSigTimeoutMsg" BU_SG_REL_ EBCM_HS SG_ 872 ESBR_AutoBrkgRqd 872;
BA_REL_ "GenSigTimeoutTime" BU_SG_REL_ EBCM_HS SG_ 872 ESBR_AutoBrkgRqd 250;
BA_REL_ "GenSigSuprvResp" BU_SG_REL_ EPB_HS SG_ 872 ESBR_AutoBrkgRqd 1;
BA_REL_ "GenSigTimeoutMsg" BU_SG_REL_ EPB_HS SG_ 872 ESBR_AutoBrkgRqd 872;
BA_REL_ "GenSigTimeoutTime" BU_SG_REL_ EPB_HS SG_ 872 ESBR_AutoBrkgRqd 250;
BA_REL_ "GenSigSuprvResp" BU_SG_REL_ BCM_HS SG_ 353 ElecShfRngDispRCExtd 1;
BA_REL_ "GenSigTimeoutMsg" BU_SG_REL_ BCM_HS SG_ 353 ElecShfRngDispRCExtd 353;
BA_REL_ "GenSigTimeoutTime" BU_SG_REL_ BCM_HS SG_ 353 ElecShfRngDispRCExtd 250;
BA_REL_ "GenSigSuprvResp" BU_SG_REL_ BCM_HS SG_ 353 ElecShfRngDisp 1;
BA_REL_ "GenSigTimeoutMsg" BU_SG_REL_ BCM_HS SG_ 353 ElecShfRngDisp 353;
BA_REL_ "GenSigTimeoutTime" BU_SG_REL_ BCM_HS SG_ 353 ElecShfRngDisp 250;
BA_REL_ "GenSigSuprvResp" BU_SG_REL_ BCM_HS SG_ 353 ElecShfRngDisp 1;
BA_REL_ "GenSigTimeoutMsg" BU_SG_REL_ BCM_HS SG_ 353 ElecShfRngDisp 353;
BA_REL_ "GenSigTimeoutTime" BU_SG_REL_ BCM_HS SG_ 353 ElecShfRngDisp 250;
BA_REL_ "GenSigSuprvResp" BU_SG_REL_ BCM_HS SG_ 353 ESPTransMalfIO 1;
BA_REL_ "GenSigTimeoutMsg" BU_SG_REL_ BCM_HS SG_ 353 ESPTransMalfIO 353;
BA_REL_ "GenSigTimeoutTime" BU_SG_REL_ BCM_HS SG_ 353 ESPTransMalfIO 250;
BA_REL_ "GenSigSuprvResp" BU_SG_REL_ BCM_HS SG_ 353 ESPRngInvldReqIO 1;
BA_REL_ "GenSigTimeoutMsg" BU_SG_REL_ BCM_HS SG_ 353 ESPRngInvldReqIO 353;
BA_REL_ "GenSigTimeoutTime" BU_SG_REL_ BCM_HS SG_ 353 ESPRngInvldReqIO 250;
BA_REL_ "GenSigSuprvResp" BU_SG_REL_ BCM_HS SG_ 353 ESPPrkInvldReqIO 1;
BA_REL_ "GenSigTimeoutMsg" BU_SG_REL_ BCM_HS SG_ 353 ESPPrkInvldReqIO 353;
BA_REL_ "GenSigTimeoutTime" BU_SG_REL_ BCM_HS SG_ 353 ESPPrkInvldReqIO 250;
BA_REL_ "GenSigSuprvResp" BU_SG_REL_ BCM_HS SG_ 353 ESPHldShfLvrToEngRgIO 1;
BA_REL_ "GenSigTimeoutMsg" BU_SG_REL_ BCM_HS SG_ 353 ESPHldShfLvrToEngRgIO 353;
BA_REL_ "GenSigTimeoutTime" BU_SG_REL_ BCM_HS SG_ 353 ESPHldShfLvrToEngRgIO 250;
BA_REL_ "GenSigSuprvResp" BU_SG_REL_ BCM_HS SG_ 353 ESPDrvrPrkIlkSftAtdIO 1;
BA_REL_ "GenSigTimeoutMsg" BU_SG_REL_ BCM_HS SG_ 353 ESPDrvrPrkIlkSftAtdIO 353;
BA_REL_ "GenSigTimeoutTime" BU_SG_REL_ BCM_HS SG_ 353 ESPDrvrPrkIlkSftAtdIO 250;
BA_REL_ "GenSigSuprvResp" BU_SG_REL_ BCM_HS SG_ 353 ESPDrvrIlkShfAtdIO 1;
BA_REL_ "GenSigTimeoutMsg" BU_SG_REL_ BCM_HS SG_ 353 ESPDrvrIlkShfAtdIO 353;
BA_REL_ "GenSigTimeoutTime" BU_SG_REL_ BCM_HS SG_ 353 ESPDrvrIlkShfAtdIO 250;
BA_REL_ "GenSigSuprvResp" BU_SG_REL_ ECM_HS SG_ 1275 BrkSyCtl2EmsRldMlfAct 1;
BA_REL_ "GenSigTimeoutMsg" BU_SG_REL_ ECM_HS SG_ 1275 BrkSyCtl2EmsRldMlfAct 1275;
BA_REL_ "GenSigTimeoutTime" BU_SG_REL_ ECM_HS SG_ 1275 BrkSyCtl2EmsRldMlfAct 1250;
BA_REL_ "GenSigSuprvResp" BU_SG_REL_ ECM_HS SG_ 1275 BSC2ERDTC_CdNum 1;
BA_REL_ "GenSigTimeoutMsg" BU_SG_REL_ ECM_HS SG_ 1275 BSC2ERDTC_CdNum 1275;
BA_REL_ "GenSigTimeoutTime" BU_SG_REL_ ECM_HS SG_ 1275 BSC2ERDTC_CdNum 1250;
BA_REL_ "GenSigSuprvResp" BU_SG_REL_ ECM_HS SG_ 1275 BSC2ERDTC_SysDes 1;
BA_REL_ "GenSigTimeoutMsg" BU_SG_REL_ ECM_HS SG_ 1275 BSC2ERDTC_SysDes 1275;
BA_REL_ "GenSigTimeoutTime" BU_SG_REL_ ECM_HS SG_ 1275 BSC2ERDTC_SysDes 1250;
BA_REL_ "GenSigSuprvResp" BU_SG_REL_ EBCM_OBD_HS SG_ 1275 EBrkAstStat 1;
BA_REL_ "GenSigTimeoutMsg" BU_SG_REL_ EBCM_OBD_HS SG_ 1275 EBrkAstStat 1275;
BA_REL_ "GenSigTimeoutTime" BU_SG_REL_ EBCM_OBD_HS SG_ 1275 EBrkAstStat 1250;
BA_REL_ "GenSigSuprvResp" BU_SG_REL_ EBCM_HS SG_ 1275 EBrkAstStat 1;
BA_REL_ "GenSigTimeoutMsg" BU_SG_REL_ EBCM_HS SG_ 1275 EBrkAstStat 1275;
BA_REL_ "GenSigTimeoutTime" BU_SG_REL_ EBCM_HS SG_ 1275 EBrkAstStat 1250;
BA_REL_ "GenSigSuprvResp" BU_SG_REL_ ECM_HS SG_ 1273 BrkSyCtl1EmsRldMlfAct 1;
BA_REL_ "GenSigTimeoutMsg" BU_SG_REL_ ECM_HS SG_ 1273 BrkSyCtl1EmsRldMlfAct 1273;
BA_REL_ "GenSigTimeoutTime" BU_SG_REL_ ECM_HS SG_ 1273 BrkSyCtl1EmsRldMlfAct 1250;
BA_REL_ "GenSigSuprvResp" BU_SG_REL_ ECM_HS SG_ 1273 BSC1ERDTC_CdNum 1;
BA_REL_ "GenSigTimeoutMsg" BU_SG_REL_ ECM_HS SG_ 1273 BSC1ERDTC_CdNum 1273;
BA_REL_ "GenSigTimeoutTime" BU_SG_REL_ ECM_HS SG_ 1273 BSC1ERDTC_CdNum 1250;
BA_REL_ "GenSigSuprvResp" BU_SG_REL_ ECM_HS SG_ 1273 BSC1ERDTC_SysDes 1;
BA_REL_ "GenSigTimeoutMsg" BU_SG_REL_ ECM_HS SG_ 1273 BSC1ERDTC_SysDes 1273;
BA_REL_ "GenSigTimeoutTime" BU_SG_REL_ ECM_HS SG_ 1273 BSC1ERDTC_SysDes 1250;
BA_REL_ "GenSigSuprvResp" BU_SG_REL_ BCM_HS SG_ 1271 BatSvrMdLvl7Act 1;
BA_REL_ "GenSigTimeoutMsg" BU_SG_REL_ BCM_HS SG_ 1271 BatSvrMdLvl7Act 1271;
BA_REL_ "GenSigTimeoutTime" BU_SG_REL_ BCM_HS SG_ 1271 BatSvrMdLvl7Act 12500;
BA_REL_ "GenSigSuprvResp" BU_SG_REL_ BCM_HS SG_ 1271 BatSvrMdNetAmpHr 1;
BA_REL_ "GenSigTimeoutMsg" BU_SG_REL_ BCM_HS SG_ 1271 BatSvrMdNetAmpHr 1271;
BA_REL_ "GenSigTimeoutTime" BU_SG_REL_ BCM_HS SG_ 1271 BatSvrMdNetAmpHr 12500;
BA_REL_ "GenSigSuprvResp" BU_SG_REL_ BCM_HS SG_ 1271 BatSvrMdWkUpCtr 1;
BA_REL_ "GenSigTimeoutMsg" BU_SG_REL_ BCM_HS SG_ 1271 BatSvrMdWkUpCtr 1271;
BA_REL_ "GenSigTimeoutTime" BU_SG_REL_ BCM_HS SG_ 1271 BatSvrMdWkUpCtr 12500;
BA_REL_ "GenSigSuprvResp" BU_SG_REL_ BCM_HS SG_ 1271 BSMCT_RawVal 1;
BA_REL_ "GenSigTimeoutMsg" BU_SG_REL_ BCM_HS SG_ 1271 BSMCT_RawVal 1271;
BA_REL_ "GenSigTimeoutTime" BU_SG_REL_ BCM_HS SG_ 1271 BSMCT_RawVal 12500;
BA_REL_ "GenSigSuprvResp" BU_SG_REL_ BCM_HS SG_ 1271 BSMCT_Mult 1;
BA_REL_ "GenSigTimeoutMsg" BU_SG_REL_ BCM_HS SG_ 1271 BSMCT_Mult 1271;
BA_REL_ "GenSigTimeoutTime" BU_SG_REL_ BCM_HS SG_ 1271 BSMCT_Mult 12500;
BA_REL_ "GenSigSuprvResp" BU_SG_REL_ BCM_HS SG_ 1271 BatSvrMdVltTrg 1;
BA_REL_ "GenSigTimeoutMsg" BU_SG_REL_ BCM_HS SG_ 1271 BatSvrMdVltTrg 1271;
BA_REL_ "GenSigTimeoutTime" BU_SG_REL_ BCM_HS SG_ 1271 BatSvrMdVltTrg 12500;
BA_REL_ "GenSigSuprvResp" BU_SG_REL_ BCM_HS SG_ 1271 BatSvrMdLvl6Act 1;
BA_REL_ "GenSigTimeoutMsg" BU_SG_REL_ BCM_HS SG_ 1271 BatSvrMdLvl6Act 1271;
BA_REL_ "GenSigTimeoutTime" BU_SG_REL_ BCM_HS SG_ 1271 BatSvrMdLvl6Act 12500;
BA_REL_ "GenSigSuprvResp" BU_SG_REL_ BCM_HS SG_ 1271 BatSvrMdLvl5Act 1;
BA_REL_ "GenSigTimeoutMsg" BU_SG_REL_ BCM_HS SG_ 1271 BatSvrMdLvl5Act 1271;
BA_REL_ "GenSigTimeoutTime" BU_SG_REL_ BCM_HS SG_ 1271 BatSvrMdLvl5Act 12500;
BA_REL_ "GenSigSuprvResp" BU_SG_REL_ BCM_HS SG_ 1271 BatSvrMdLvl4Act 1;
BA_REL_ "GenSigTimeoutMsg" BU_SG_REL_ BCM_HS SG_ 1271 BatSvrMdLvl4Act 1271;
BA_REL_ "GenSigTimeoutTime" BU_SG_REL_ BCM_HS SG_ 1271 BatSvrMdLvl4Act 12500;
BA_REL_ "GenSigSuprvResp" BU_SG_REL_ BSM_HS SG_ 558 CDP_HVDevShtdnCdARCSt 1;
BA_REL_ "GenSigTimeoutMsg" BU_SG_REL_ BSM_HS SG_ 558 CDP_HVDevShtdnCdARCSt 558;
BA_REL_ "GenSigTimeoutTime" BU_SG_REL_ BSM_HS SG_ 558 CDP_HVDevShtdnCdARCSt 250;
BA_REL_ "GenSigSuprvResp" BU_SG_REL_ VICM_HS SG_ 558 CDP_HVDevShtdnCdARCSt 1;
BA_REL_ "GenSigTimeoutMsg" BU_SG_REL_ VICM_HS SG_ 558 CDP_HVDevShtdnCdARCSt 558;
BA_REL_ "GenSigTimeoutTime" BU_SG_REL_ VICM_HS SG_ 558 CDP_HVDevShtdnCdARCSt 250;
BA_REL_ "GenSigSuprvResp" BU_SG_REL_ BSM_HS SG_ 558 CDP_CmpSpdReqARCSt 1;
BA_REL_ "GenSigTimeoutMsg" BU_SG_REL_ BSM_HS SG_ 558 CDP_CmpSpdReqARCSt 558;
BA_REL_ "GenSigTimeoutTime" BU_SG_REL_ BSM_HS SG_ 558 CDP_CmpSpdReqARCSt 250;
BA_REL_ "GenSigSuprvResp" BU_SG_REL_ VICM_HS SG_ 558 CDP_CmpSpdReqARCSt 1;
BA_REL_ "GenSigTimeoutMsg" BU_SG_REL_ VICM_HS SG_ 558 CDP_CmpSpdReqARCSt 558;
BA_REL_ "GenSigTimeoutTime" BU_SG_REL_ VICM_HS SG_ 558 CDP_CmpSpdReqARCSt 250;
BA_REL_ "GenSigSuprvResp" BU_SG_REL_ BSM_HS SG_ 558 CDP_CmpLossCommOcc 1;
BA_REL_ "GenSigTimeoutMsg" BU_SG_REL_ BSM_HS SG_ 558 CDP_CmpLossCommOcc 558;
BA_REL_ "GenSigTimeoutTime" BU_SG_REL_ BSM_HS SG_ 558 CDP_CmpLossCommOcc 250;
BA_REL_ "GenSigSuprvResp" BU_SG_REL_ VICM_HS SG_ 558 CDP_CmpLossCommOcc 1;
BA_REL_ "GenSigTimeoutMsg" BU_SG_REL_ VICM_HS SG_ 558 CDP_CmpLossCommOcc 558;
BA_REL_ "GenSigTimeoutTime" BU_SG_REL_ VICM_HS SG_ 558 CDP_CmpLossCommOcc 250;
BA_REL_ "GenSigSuprvResp" BU_SG_REL_ BSM_HS SG_ 558 CDP_CmpWkUp 1;
BA_REL_ "GenSigTimeoutMsg" BU_SG_REL_ BSM_HS SG_ 558 CDP_CmpWkUp 558;
BA_REL_ "GenSigTimeoutTime" BU_SG_REL_ BSM_HS SG_ 558 CDP_CmpWkUp 250;
BA_REL_ "GenSigSuprvResp" BU_SG_REL_ VICM_HS SG_ 558 CDP_CmpWkUp 1;
BA_REL_ "GenSigTimeoutMsg" BU_SG_REL_ VICM_HS SG_ 558 CDP_CmpWkUp 558;
BA_REL_ "GenSigTimeoutTime" BU_SG_REL_ VICM_HS SG_ 558 CDP_CmpWkUp 250;
BA_REL_ "GenSigSuprvResp" BU_SG_REL_ BSM_HS SG_ 558 CDP_CmpRunCrnk 1;
BA_REL_ "GenSigTimeoutMsg" BU_SG_REL_ BSM_HS SG_ 558 CDP_CmpRunCrnk 558;
BA_REL_ "GenSigTimeoutTime" BU_SG_REL_ BSM_HS SG_ 558 CDP_CmpRunCrnk 250;
BA_REL_ "GenSigSuprvResp" BU_SG_REL_ VICM_HS SG_ 558 CDP_CmpRunCrnk 1;
BA_REL_ "GenSigTimeoutMsg" BU_SG_REL_ VICM_HS SG_ 558 CDP_CmpRunCrnk 558;
BA_REL_ "GenSigTimeoutTime" BU_SG_REL_ VICM_HS SG_ 558 CDP_CmpRunCrnk 250;
BA_REL_ "GenSigSuprvResp" BU_SG_REL_ BSM_HS SG_ 558 CDSP_CmpOvrTmpSt 1;
BA_REL_ "GenSigTimeoutMsg" BU_SG_REL_ BSM_HS SG_ 558 CDSP_CmpOvrTmpSt 558;
BA_REL_ "GenSigTimeoutTime" BU_SG_REL_ BSM_HS SG_ 558 CDSP_CmpOvrTmpSt 250;
BA_REL_ "GenSigSuprvResp" BU_SG_REL_ VICM_HS SG_ 558 CDSP_CmpOvrTmpSt 1;
BA_REL_ "GenSigTimeoutMsg" BU_SG_REL_ VICM_HS SG_ 558 CDSP_CmpOvrTmpSt 558;
BA_REL_ "GenSigTimeoutTime" BU_SG_REL_ VICM_HS SG_ 558 CDSP_CmpOvrTmpSt 250;
BA_REL_ "GenSigSuprvResp" BU_SG_REL_ BSM_HS SG_ 558 CDSP_CmpHVAbnrlOrVltSt 1;
BA_REL_ "GenSigTimeoutMsg" BU_SG_REL_ BSM_HS SG_ 558 CDSP_CmpHVAbnrlOrVltSt 558;
BA_REL_ "GenSigTimeoutTime" BU_SG_REL_ BSM_HS SG_ 558 CDSP_CmpHVAbnrlOrVltSt 250;
BA_REL_ "GenSigSuprvResp" BU_SG_REL_ VICM_HS SG_ 558 CDSP_CmpHVAbnrlOrVltSt 1;
BA_REL_ "GenSigTimeoutMsg" BU_SG_REL_ VICM_HS SG_ 558 CDSP_CmpHVAbnrlOrVltSt 558;
BA_REL_ "GenSigTimeoutTime" BU_SG_REL_ VICM_HS SG_ 558 CDSP_CmpHVAbnrlOrVltSt 250;
BA_REL_ "GenSigSuprvResp" BU_SG_REL_ BSM_HS SG_ 558 CDSP_CmpHVUndrVltgSt 1;
BA_REL_ "GenSigTimeoutMsg" BU_SG_REL_ BSM_HS SG_ 558 CDSP_CmpHVUndrVltgSt 558;
BA_REL_ "GenSigTimeoutTime" BU_SG_REL_ BSM_HS SG_ 558 CDSP_CmpHVUndrVltgSt 250;
BA_REL_ "GenSigSuprvResp" BU_SG_REL_ VICM_HS SG_ 558 CDSP_CmpHVUndrVltgSt 1;
BA_REL_ "GenSigTimeoutMsg" BU_SG_REL_ VICM_HS SG_ 558 CDSP_CmpHVUndrVltgSt 558;
BA_REL_ "GenSigTimeoutTime" BU_SG_REL_ VICM_HS SG_ 558 CDSP_CmpHVUndrVltgSt 250;
BA_REL_ "GenSigSuprvResp" BU_SG_REL_ BSM_HS SG_ 558 CDSP_CmpHVOvrVltgSt 1;
BA_REL_ "GenSigTimeoutMsg" BU_SG_REL_ BSM_HS SG_ 558 CDSP_CmpHVOvrVltgSt 558;
BA_REL_ "GenSigTimeoutTime" BU_SG_REL_ BSM_HS SG_ 558 CDSP_CmpHVOvrVltgSt 250;
BA_REL_ "GenSigSuprvResp" BU_SG_REL_ VICM_HS SG_ 558 CDSP_CmpHVOvrVltgSt 1;
BA_REL_ "GenSigTimeoutMsg" BU_SG_REL_ VICM_HS SG_ 558 CDSP_CmpHVOvrVltgSt 558;
BA_REL_ "GenSigTimeoutTime" BU_SG_REL_ VICM_HS SG_ 558 CDSP_CmpHVOvrVltgSt 250;
BA_REL_ "GenSigSuprvResp" BU_SG_REL_ BSM_HS SG_ 558 CDSP_CmpHVOvrCrntSt 1;
BA_REL_ "GenSigTimeoutMsg" BU_SG_REL_ BSM_HS SG_ 558 CDSP_CmpHVOvrCrntSt 558;
BA_REL_ "GenSigTimeoutTime" BU_SG_REL_ BSM_HS SG_ 558 CDSP_CmpHVOvrCrntSt 250;
BA_REL_ "GenSigSuprvResp" BU_SG_REL_ VICM_HS SG_ 558 CDSP_CmpHVOvrCrntSt 1;
BA_REL_ "GenSigTimeoutMsg" BU_SG_REL_ VICM_HS SG_ 558 CDSP_CmpHVOvrCrntSt 558;
BA_REL_ "GenSigTimeoutTime" BU_SG_REL_ VICM_HS SG_ 558 CDSP_CmpHVOvrCrntSt 250;
BA_REL_ "GenSigSuprvResp" BU_SG_REL_ BSM_HS SG_ 558 CDSP_OvrTempWrnInd 1;
BA_REL_ "GenSigTimeoutMsg" BU_SG_REL_ BSM_HS SG_ 558 CDSP_OvrTempWrnInd 558;
BA_REL_ "GenSigTimeoutTime" BU_SG_REL_ BSM_HS SG_ 558 CDSP_OvrTempWrnInd 250;
BA_REL_ "GenSigSuprvResp" BU_SG_REL_ VICM_HS SG_ 558 CDSP_OvrTempWrnInd 1;
BA_REL_ "GenSigTimeoutMsg" BU_SG_REL_ VICM_HS SG_ 558 CDSP_OvrTempWrnInd 558;
BA_REL_ "GenSigTimeoutTime" BU_SG_REL_ VICM_HS SG_ 558 CDSP_OvrTempWrnInd 250;
BA_REL_ "GenSigSuprvResp" BU_SG_REL_ BSM_HS SG_ 558 CDSP_CmpDgrdOp 1;
BA_REL_ "GenSigTimeoutMsg" BU_SG_REL_ BSM_HS SG_ 558 CDSP_CmpDgrdOp 558;
BA_REL_ "GenSigTimeoutTime" BU_SG_REL_ BSM_HS SG_ 558 CDSP_CmpDgrdOp 250;
BA_REL_ "GenSigSuprvResp" BU_SG_REL_ VICM_HS SG_ 558 CDSP_CmpDgrdOp 1;
BA_REL_ "GenSigTimeoutMsg" BU_SG_REL_ VICM_HS SG_ 558 CDSP_CmpDgrdOp 558;
BA_REL_ "GenSigTimeoutTime" BU_SG_REL_ VICM_HS SG_ 558 CDSP_CmpDgrdOp 250;
BA_REL_ "GenSigSuprvResp" BU_SG_REL_ BSM_HS SG_ 558 CDSP_CmpIntShdwnFltSt 1;
BA_REL_ "GenSigTimeoutMsg" BU_SG_REL_ BSM_HS SG_ 558 CDSP_CmpIntShdwnFltSt 558;
BA_REL_ "GenSigTimeoutTime" BU_SG_REL_ BSM_HS SG_ 558 CDSP_CmpIntShdwnFltSt 250;
BA_REL_ "GenSigSuprvResp" BU_SG_REL_ VICM_HS SG_ 558 CDSP_CmpIntShdwnFltSt 1;
BA_REL_ "GenSigTimeoutMsg" BU_SG_REL_ VICM_HS SG_ 558 CDSP_CmpIntShdwnFltSt 558;
BA_REL_ "GenSigTimeoutTime" BU_SG_REL_ VICM_HS SG_ 558 CDSP_CmpIntShdwnFltSt 250;
BA_REL_ "GenSigSuprvResp" BU_SG_REL_ BSM_HS SG_ 558 CDSP_CmpIntRecblFltSt 1;
BA_REL_ "GenSigTimeoutMsg" BU_SG_REL_ BSM_HS SG_ 558 CDSP_CmpIntRecblFltSt 558;
BA_REL_ "GenSigTimeoutTime" BU_SG_REL_ BSM_HS SG_ 558 CDSP_CmpIntRecblFltSt 250;
BA_REL_ "GenSigSuprvResp" BU_SG_REL_ VICM_HS SG_ 558 CDSP_CmpIntRecblFltSt 1;
BA_REL_ "GenSigTimeoutMsg" BU_SG_REL_ VICM_HS SG_ 558 CDSP_CmpIntRecblFltSt 558;
BA_REL_ "GenSigTimeoutTime" BU_SG_REL_ VICM_HS SG_ 558 CDSP_CmpIntRecblFltSt 250;
BA_REL_ "GenSigSuprvResp" BU_SG_REL_ BSM_HS SG_ 558 CDSP_CmpOpOvrldSt 1;
BA_REL_ "GenSigTimeoutMsg" BU_SG_REL_ BSM_HS SG_ 558 CDSP_CmpOpOvrldSt 558;
BA_REL_ "GenSigTimeoutTime" BU_SG_REL_ BSM_HS SG_ 558 CDSP_CmpOpOvrldSt 250;
BA_REL_ "GenSigSuprvResp" BU_SG_REL_ VICM_HS SG_ 558 CDSP_CmpOpOvrldSt 1;
BA_REL_ "GenSigTimeoutMsg" BU_SG_REL_ VICM_HS SG_ 558 CDSP_CmpOpOvrldSt 558;
BA_REL_ "GenSigTimeoutTime" BU_SG_REL_ VICM_HS SG_ 558 CDSP_CmpOpOvrldSt 250;
BA_REL_ "GenSigSuprvResp" BU_SG_REL_ BSM_HS SG_ 558 CDSP_CmpDrCrctFltSt 1;
BA_REL_ "GenSigTimeoutMsg" BU_SG_REL_ BSM_HS SG_ 558 CDSP_CmpDrCrctFltSt 558;
BA_REL_ "GenSigTimeoutTime" BU_SG_REL_ BSM_HS SG_ 558 CDSP_CmpDrCrctFltSt 250;
BA_REL_ "GenSigSuprvResp" BU_SG_REL_ VICM_HS SG_ 558 CDSP_CmpDrCrctFltSt 1;
BA_REL_ "GenSigTimeoutMsg" BU_SG_REL_ VICM_HS SG_ 558 CDSP_CmpDrCrctFltSt 558;
BA_REL_ "GenSigTimeoutTime" BU_SG_REL_ VICM_HS SG_ 558 CDSP_CmpDrCrctFltSt 250;
BA_REL_ "GenSigSuprvResp" BU_SG_REL_ BSM_HS SG_ 558 CDSP_CmpMtrPerfFltSt 1;
BA_REL_ "GenSigTimeoutMsg" BU_SG_REL_ BSM_HS SG_ 558 CDSP_CmpMtrPerfFltSt 558;
BA_REL_ "GenSigTimeoutTime" BU_SG_REL_ BSM_HS SG_ 558 CDSP_CmpMtrPerfFltSt 250;
BA_REL_ "GenSigSuprvResp" BU_SG_REL_ VICM_HS SG_ 558 CDSP_CmpMtrPerfFltSt 1;
BA_REL_ "GenSigTimeoutMsg" BU_SG_REL_ VICM_HS SG_ 558 CDSP_CmpMtrPerfFltSt 558;
BA_REL_ "GenSigTimeoutTime" BU_SG_REL_ VICM_HS SG_ 558 CDSP_CmpMtrPerfFltSt 250;
BA_REL_ "GenSigSuprvResp" BU_SG_REL_ BSM_HS SG_ 558 CDSP_CmpEEPROMFltSt 1;
BA_REL_ "GenSigTimeoutMsg" BU_SG_REL_ BSM_HS SG_ 558 CDSP_CmpEEPROMFltSt 558;
BA_REL_ "GenSigTimeoutTime" BU_SG_REL_ BSM_HS SG_ 558 CDSP_CmpEEPROMFltSt 250;
BA_REL_ "GenSigSuprvResp" BU_SG_REL_ VICM_HS SG_ 558 CDSP_CmpEEPROMFltSt 1;
BA_REL_ "GenSigTimeoutMsg" BU_SG_REL_ VICM_HS SG_ 558 CDSP_CmpEEPROMFltSt 558;
BA_REL_ "GenSigTimeoutTime" BU_SG_REL_ VICM_HS SG_ 558 CDSP_CmpEEPROMFltSt 250;
BA_REL_ "GenSigSuprvResp" BU_SG_REL_ BSM_HS SG_ 558 CDSP_CmpROMFltSt 1;
BA_REL_ "GenSigTimeoutMsg" BU_SG_REL_ BSM_HS SG_ 558 CDSP_CmpROMFltSt 558;
BA_REL_ "GenSigTimeoutTime" BU_SG_REL_ BSM_HS SG_ 558 CDSP_CmpROMFltSt 250;
BA_REL_ "GenSigSuprvResp" BU_SG_REL_ VICM_HS SG_ 558 CDSP_CmpROMFltSt 1;
BA_REL_ "GenSigTimeoutMsg" BU_SG_REL_ VICM_HS SG_ 558 CDSP_CmpROMFltSt 558;
BA_REL_ "GenSigTimeoutTime" BU_SG_REL_ VICM_HS SG_ 558 CDSP_CmpROMFltSt 250;
BA_REL_ "GenSigSuprvResp" BU_SG_REL_ BSM_HS SG_ 558 CDSP_CmpRAMFltSt 1;
BA_REL_ "GenSigTimeoutMsg" BU_SG_REL_ BSM_HS SG_ 558 CDSP_CmpRAMFltSt 558;
BA_REL_ "GenSigTimeoutTime" BU_SG_REL_ BSM_HS SG_ 558 CDSP_CmpRAMFltSt 250;
BA_REL_ "GenSigSuprvResp" BU_SG_REL_ VICM_HS SG_ 558 CDSP_CmpRAMFltSt 1;
BA_REL_ "GenSigTimeoutMsg" BU_SG_REL_ VICM_HS SG_ 558 CDSP_CmpRAMFltSt 558;
BA_REL_ "GenSigTimeoutTime" BU_SG_REL_ VICM_HS SG_ 558 CDSP_CmpRAMFltSt 250;
BA_REL_ "GenSigSuprvResp" BU_SG_REL_ BSM_HS SG_ 558 CSSP_CmpIGBTTpOtRgLSt 1;
BA_REL_ "GenSigTimeoutMsg" BU_SG_REL_ BSM_HS SG_ 558 CSSP_CmpIGBTTpOtRgLSt 558;
BA_REL_ "GenSigTimeoutTime" BU_SG_REL_ BSM_HS SG_ 558 CSSP_CmpIGBTTpOtRgLSt 250;
BA_REL_ "GenSigSuprvResp" BU_SG_REL_ VICM_HS SG_ 558 CSSP_CmpIGBTTpOtRgLSt 1;
BA_REL_ "GenSigTimeoutMsg" BU_SG_REL_ VICM_HS SG_ 558 CSSP_CmpIGBTTpOtRgLSt 558;
BA_REL_ "GenSigTimeoutTime" BU_SG_REL_ VICM_HS SG_ 558 CSSP_CmpIGBTTpOtRgLSt 250;
BA_REL_ "GenSigSuprvResp" BU_SG_REL_ BSM_HS SG_ 558 CSSP_CmpIGBTTpOtRgHSt 1;
BA_REL_ "GenSigTimeoutMsg" BU_SG_REL_ BSM_HS SG_ 558 CSSP_CmpIGBTTpOtRgHSt 558;
BA_REL_ "GenSigTimeoutTime" BU_SG_REL_ BSM_HS SG_ 558 CSSP_CmpIGBTTpOtRgHSt 250;
BA_REL_ "GenSigSuprvResp" BU_SG_REL_ VICM_HS SG_ 558 CSSP_CmpIGBTTpOtRgHSt 1;
BA_REL_ "GenSigTimeoutMsg" BU_SG_REL_ VICM_HS SG_ 558 CSSP_CmpIGBTTpOtRgHSt 558;
BA_REL_ "GenSigTimeoutTime" BU_SG_REL_ VICM_HS SG_ 558 CSSP_CmpIGBTTpOtRgHSt 250;
BA_REL_ "GenSigSuprvResp" BU_SG_REL_ BSM_HS SG_ 558 CSSP_CmpCPUTmpOtRgLSt 1;
BA_REL_ "GenSigTimeoutMsg" BU_SG_REL_ BSM_HS SG_ 558 CSSP_CmpCPUTmpOtRgLSt 558;
BA_REL_ "GenSigTimeoutTime" BU_SG_REL_ BSM_HS SG_ 558 CSSP_CmpCPUTmpOtRgLSt 250;
BA_REL_ "GenSigSuprvResp" BU_SG_REL_ VICM_HS SG_ 558 CSSP_CmpCPUTmpOtRgLSt 1;
BA_REL_ "GenSigTimeoutMsg" BU_SG_REL_ VICM_HS SG_ 558 CSSP_CmpCPUTmpOtRgLSt 558;
BA_REL_ "GenSigTimeoutTime" BU_SG_REL_ VICM_HS SG_ 558 CSSP_CmpCPUTmpOtRgLSt 250;
BA_REL_ "GenSigSuprvResp" BU_SG_REL_ BSM_HS SG_ 558 CSSP_CmpCPUTmpOtRgHSt 1;
BA_REL_ "GenSigTimeoutMsg" BU_SG_REL_ BSM_HS SG_ 558 CSSP_CmpCPUTmpOtRgHSt 558;
BA_REL_ "GenSigTimeoutTime" BU_SG_REL_ BSM_HS SG_ 558 CSSP_CmpCPUTmpOtRgHSt 250;
BA_REL_ "GenSigSuprvResp" BU_SG_REL_ VICM_HS SG_ 558 CSSP_CmpCPUTmpOtRgHSt 1;
BA_REL_ "GenSigTimeoutMsg" BU_SG_REL_ VICM_HS SG_ 558 CSSP_CmpCPUTmpOtRgHSt 558;
BA_REL_ "GenSigTimeoutTime" BU_SG_REL_ VICM_HS SG_ 558 CSSP_CmpCPUTmpOtRgHSt 250;
BA_REL_ "GenSigSuprvResp" BU_SG_REL_ BSM_HS SG_ 558 CSSP_CmpHVSnsOtRgLSt 1;
BA_REL_ "GenSigTimeoutMsg" BU_SG_REL_ BSM_HS SG_ 558 CSSP_CmpHVSnsOtRgLSt 558;
BA_REL_ "GenSigTimeoutTime" BU_SG_REL_ BSM_HS SG_ 558 CSSP_CmpHVSnsOtRgLSt 250;
BA_REL_ "GenSigSuprvResp" BU_SG_REL_ VICM_HS SG_ 558 CSSP_CmpHVSnsOtRgLSt 1;
BA_REL_ "GenSigTimeoutMsg" BU_SG_REL_ VICM_HS SG_ 558 CSSP_CmpHVSnsOtRgLSt 558;
BA_REL_ "GenSigTimeoutTime" BU_SG_REL_ VICM_HS SG_ 558 CSSP_CmpHVSnsOtRgLSt 250;
BA_REL_ "GenSigSuprvResp" BU_SG_REL_ BSM_HS SG_ 558 CSSP_CmpHVSnsOtRgHSt 1;
BA_REL_ "GenSigTimeoutMsg" BU_SG_REL_ BSM_HS SG_ 558 CSSP_CmpHVSnsOtRgHSt 558;
BA_REL_ "GenSigTimeoutTime" BU_SG_REL_ BSM_HS SG_ 558 CSSP_CmpHVSnsOtRgHSt 250;
BA_REL_ "GenSigSuprvResp" BU_SG_REL_ VICM_HS SG_ 558 CSSP_CmpHVSnsOtRgHSt 1;
BA_REL_ "GenSigTimeoutMsg" BU_SG_REL_ VICM_HS SG_ 558 CSSP_CmpHVSnsOtRgHSt 558;
BA_REL_ "GenSigTimeoutTime" BU_SG_REL_ VICM_HS SG_ 558 CSSP_CmpHVSnsOtRgHSt 250;
BA_REL_ "GenSigSuprvResp" BU_SG_REL_ BSM_HS SG_ 558 CSSP_CmpPhCrntOtRgLSt 1;
BA_REL_ "GenSigTimeoutMsg" BU_SG_REL_ BSM_HS SG_ 558 CSSP_CmpPhCrntOtRgLSt 558;
BA_REL_ "GenSigTimeoutTime" BU_SG_REL_ BSM_HS SG_ 558 CSSP_CmpPhCrntOtRgLSt 250;
BA_REL_ "GenSigSuprvResp" BU_SG_REL_ VICM_HS SG_ 558 CSSP_CmpPhCrntOtRgLSt 1;
BA_REL_ "GenSigTimeoutMsg" BU_SG_REL_ VICM_HS SG_ 558 CSSP_CmpPhCrntOtRgLSt 558;
BA_REL_ "GenSigTimeoutTime" BU_SG_REL_ VICM_HS SG_ 558 CSSP_CmpPhCrntOtRgLSt 250;
BA_REL_ "GenSigSuprvResp" BU_SG_REL_ BSM_HS SG_ 558 CSSP_CmpPhCrntOtRgHSt 1;
BA_REL_ "GenSigTimeoutMsg" BU_SG_REL_ BSM_HS SG_ 558 CSSP_CmpPhCrntOtRgHSt 558;
BA_REL_ "GenSigTimeoutTime" BU_SG_REL_ BSM_HS SG_ 558 CSSP_CmpPhCrntOtRgHSt 250;
BA_REL_ "GenSigSuprvResp" BU_SG_REL_ VICM_HS SG_ 558 CSSP_CmpPhCrntOtRgHSt 1;
BA_REL_ "GenSigTimeoutMsg" BU_SG_REL_ VICM_HS SG_ 558 CSSP_CmpPhCrntOtRgHSt 558;
BA_REL_ "GenSigTimeoutTime" BU_SG_REL_ VICM_HS SG_ 558 CSSP_CmpPhCrntOtRgHSt 250;
BA_REL_ "GenSigSuprvResp" BU_SG_REL_ TCM_HS SG_ 208 WhlSlipRRWhl 1;
BA_REL_ "GenSigTimeoutMsg" BU_SG_REL_ TCM_HS SG_ 208 WhlSlipRRWhl 208;
BA_REL_ "GenSigTimeoutTime" BU_SG_REL_ TCM_HS SG_ 208 WhlSlipRRWhl 250;
BA_REL_ "GenSigSuprvResp" BU_SG_REL_ TCM_HS SG_ 208 WhlSlipRFWhl 1;
BA_REL_ "GenSigTimeoutMsg" BU_SG_REL_ TCM_HS SG_ 208 WhlSlipRFWhl 208;
BA_REL_ "GenSigTimeoutTime" BU_SG_REL_ TCM_HS SG_ 208 WhlSlipRFWhl 250;
BA_REL_ "GenSigSuprvResp" BU_SG_REL_ TCM_HS SG_ 208 WhlSlipLRWhl 1;
BA_REL_ "GenSigTimeoutMsg" BU_SG_REL_ TCM_HS SG_ 208 WhlSlipLRWhl 208;
BA_REL_ "GenSigTimeoutTime" BU_SG_REL_ TCM_HS SG_ 208 WhlSlipLRWhl 250;
BA_REL_ "GenSigSuprvResp" BU_SG_REL_ TCM_HS SG_ 208 WhlSlipLFWhl 1;
BA_REL_ "GenSigTimeoutMsg" BU_SG_REL_ TCM_HS SG_ 208 WhlSlipLFWhl 208;
BA_REL_ "GenSigTimeoutTime" BU_SG_REL_ TCM_HS SG_ 208 WhlSlipLFWhl 250;
BA_REL_ "GenSigSuprvResp" BU_SG_REL_ ECM_HS SG_ 663 RdGasFuelDevDisStat 1;
BA_REL_ "GenSigTimeoutMsg" BU_SG_REL_ ECM_HS SG_ 663 RdGasFuelDevDisStat 663;
BA_REL_ "GenSigTimeoutTime" BU_SG_REL_ ECM_HS SG_ 663 RdGasFuelDevDisStat 250;
BA_REL_ "GenSigSuprvResp" BU_SG_REL_ ECM_HS SG_ 663 RdFInjCtrlMdIFltAct 1;
BA_REL_ "GenSigTimeoutMsg" BU_SG_REL_ ECM_HS SG_ 663 RdFInjCtrlMdIFltAct 663;
BA_REL_ "GenSigTimeoutTime" BU_SG_REL_ ECM_HS SG_ 663 RdFInjCtrlMdIFltAct 250;
BA_REL_ "GenSigSuprvResp" BU_SG_REL_ ECM_HS SG_ 663 RdDistFuelMdReq 1;
BA_REL_ "GenSigTimeoutMsg" BU_SG_REL_ ECM_HS SG_ 663 RdDistFuelMdReq 663;
BA_REL_ "GenSigTimeoutTime" BU_SG_REL_ ECM_HS SG_ 663 RdDistFuelMdReq 250;
BA_REL_ "GenSigSuprvResp" BU_SG_REL_ ECM_HS SG_ 663 RdDistFuelMdCmdRes 1;
BA_REL_ "GenSigTimeoutMsg" BU_SG_REL_ ECM_HS SG_ 663 RdDistFuelMdCmdRes 663;
BA_REL_ "GenSigTimeoutTime" BU_SG_REL_ ECM_HS SG_ 663 RdDistFuelMdCmdRes 250;
BA_REL_ "GenSigSuprvResp" BU_SG_REL_ ECM_HS SG_ 663 RdAltFuelSysStat 1;
BA_REL_ "GenSigTimeoutMsg" BU_SG_REL_ ECM_HS SG_ 663 RdAltFuelSysStat 663;
BA_REL_ "GenSigTimeoutTime" BU_SG_REL_ ECM_HS SG_ 663 RdAltFuelSysStat 250;
BA_REL_ "GenSigSuprvResp" BU_SG_REL_ ECM_HS SG_ 663 RdAltFuelInjCmdRsp 1;
BA_REL_ "GenSigTimeoutMsg" BU_SG_REL_ ECM_HS SG_ 663 RdAltFuelInjCmdRsp 663;
BA_REL_ "GenSigTimeoutTime" BU_SG_REL_ ECM_HS SG_ 663 RdAltFuelInjCmdRsp 250;
BA_REL_ "GenSigSuprvResp" BU_SG_REL_ ECM_HS SG_ 663 AltFuelInjRCRstOcc 1;
BA_REL_ "GenSigTimeoutMsg" BU_SG_REL_ ECM_HS SG_ 663 AltFuelInjRCRstOcc 663;
BA_REL_ "GenSigTimeoutTime" BU_SG_REL_ ECM_HS SG_ 663 AltFuelInjRCRstOcc 250;
BA_REL_ "GenSigSuprvResp" BU_SG_REL_ ECM_HS SG_ 663 AltFuelInjRC 1;
BA_REL_ "GenSigTimeoutMsg" BU_SG_REL_ ECM_HS SG_ 663 AltFuelInjRC 663;
BA_REL_ "GenSigTimeoutTime" BU_SG_REL_ ECM_HS SG_ 663 AltFuelInjRC 250;
BA_REL_ "GenSigSuprvResp" BU_SG_REL_ BCM_HS SG_ 1263 BatSOFVolt 1;
BA_REL_ "GenSigTimeoutMsg" BU_SG_REL_ BCM_HS SG_ 1263 BatSOFVolt 1263;
BA_REL_ "GenSigTimeoutTime" BU_SG_REL_ BCM_HS SG_ 1263 BatSOFVolt 2500;
BA_REL_ "GenSigSuprvResp" BU_SG_REL_ BCM_HS SG_ 1263 BatSOH 1;
BA_REL_ "GenSigTimeoutMsg" BU_SG_REL_ BCM_HS SG_ 1263 BatSOH 1263;
BA_REL_ "GenSigTimeoutTime" BU_SG_REL_ BCM_HS SG_ 1263 BatSOH 2500;
BA_REL_ "GenSigSuprvResp" BU_SG_REL_ BCM_HS SG_ 1263 IBSBatSOC 1;
BA_REL_ "GenSigTimeoutMsg" BU_SG_REL_ BCM_HS SG_ 1263 IBSBatSOC 1263;
BA_REL_ "GenSigTimeoutTime" BU_SG_REL_ BCM_HS SG_ 1263 IBSBatSOC 2500;
BA_REL_ "GenSigSuprvResp" BU_SG_REL_ BCM_HS SG_ 1263 BattSOXStat 1;
BA_REL_ "GenSigTimeoutMsg" BU_SG_REL_ BCM_HS SG_ 1263 BattSOXStat 1263;
BA_REL_ "GenSigTimeoutTime" BU_SG_REL_ BCM_HS SG_ 1263 BattSOXStat 2500;
BA_REL_ "GenSigSuprvResp" BU_SG_REL_ BCM_HS SG_ 1261 MinCrnkCrnt 1;
BA_REL_ "GenSigTimeoutMsg" BU_SG_REL_ BCM_HS SG_ 1261 MinCrnkCrnt 1261;
BA_REL_ "GenSigTimeoutTime" BU_SG_REL_ BCM_HS SG_ 1261 MinCrnkCrnt 2500;
BA_REL_ "GenSigSuprvResp" BU_SG_REL_ BCM_HS SG_ 1261 MinCrnkVlt 1;
BA_REL_ "GenSigTimeoutMsg" BU_SG_REL_ BCM_HS SG_ 1261 MinCrnkVlt 1261;
BA_REL_ "GenSigTimeoutTime" BU_SG_REL_ BCM_HS SG_ 1261 MinCrnkVlt 2500;
BA_REL_ "GenSigSuprvResp" BU_SG_REL_ BCM_HS SG_ 1261 BattTemp 1;
BA_REL_ "GenSigTimeoutMsg" BU_SG_REL_ BCM_HS SG_ 1261 BattTemp 1261;
BA_REL_ "GenSigTimeoutTime" BU_SG_REL_ BCM_HS SG_ 1261 BattTemp 2500;
BA_REL_ "GenSigSuprvResp" BU_SG_REL_ BCM_HS SG_ 1259 AllNodesVNA 1;
BA_REL_ "GenSigTimeoutMsg" BU_SG_REL_ BCM_HS SG_ 1259 AllNodesVNA 1259;
BA_REL_ "GenSigTimeoutTime" BU_SG_REL_ BCM_HS SG_ 1259 AllNodesVNA 1250;
BA_REL_ "GenSigSuprvResp" BU_SG_REL_ BCM_HS SG_ 1259 NAHrDisChrg 1;
BA_REL_ "GenSigTimeoutMsg" BU_SG_REL_ BCM_HS SG_ 1259 NAHrDisChrg 1259;
BA_REL_ "GenSigTimeoutTime" BU_SG_REL_ BCM_HS SG_ 1259 NAHrDisChrg 1250;
BA_REL_ "GenSigSuprvResp" BU_SG_REL_ BCM_HS SG_ 1259 NAHrChg 1;
BA_REL_ "GenSigTimeoutMsg" BU_SG_REL_ BCM_HS SG_ 1259 NAHrChg 1259;
BA_REL_ "GenSigTimeoutTime" BU_SG_REL_ BCM_HS SG_ 1259 NAHrChg 1250;
BA_REL_ "GenSigSuprvResp" BU_SG_REL_ EBCM_OBD_HS SG_ 1034 CRL_Cnfdnc 1;
BA_REL_ "GenSigTimeoutMsg" BU_SG_REL_ EBCM_OBD_HS SG_ 1034 CRL_Cnfdnc 1034;
BA_REL_ "GenSigTimeoutTime" BU_SG_REL_ EBCM_OBD_HS SG_ 1034 CRL_Cnfdnc 250;
BA_REL_ "GenSigSuprvResp" BU_SG_REL_ EBCM_HS SG_ 1034 CRL_Cnfdnc 1;
BA_REL_ "GenSigTimeoutMsg" BU_SG_REL_ EBCM_HS SG_ 1034 CRL_Cnfdnc 1034;
BA_REL_ "GenSigTimeoutTime" BU_SG_REL_ EBCM_HS SG_ 1034 CRL_Cnfdnc 250;
BA_REL_ "GenSigSuprvResp" BU_SG_REL_ EBCM_OBD_HS SG_ 1034 CRL_ViewRng 1;
BA_REL_ "GenSigTimeoutMsg" BU_SG_REL_ EBCM_OBD_HS SG_ 1034 CRL_ViewRng 1034;
BA_REL_ "GenSigTimeoutTime" BU_SG_REL_ EBCM_OBD_HS SG_ 1034 CRL_ViewRng 250;
BA_REL_ "GenSigSuprvResp" BU_SG_REL_ EBCM_HS SG_ 1034 CRL_ViewRng 1;
BA_REL_ "GenSigTimeoutMsg" BU_SG_REL_ EBCM_HS SG_ 1034 CRL_ViewRng 1034;
BA_REL_ "GenSigTimeoutTime" BU_SG_REL_ EBCM_HS SG_ 1034 CRL_ViewRng 250;
BA_REL_ "GenSigSuprvResp" BU_SG_REL_ EBCM_OBD_HS SG_ 1034 CRL_CoefdA 1;
BA_REL_ "GenSigTimeoutMsg" BU_SG_REL_ EBCM_OBD_HS SG_ 1034 CRL_CoefdA 1034;
BA_REL_ "GenSigTimeoutTime" BU_SG_REL_ EBCM_OBD_HS SG_ 1034 CRL_CoefdA 250;
BA_REL_ "GenSigSuprvResp" BU_SG_REL_ EBCM_HS SG_ 1034 CRL_CoefdA 1;
BA_REL_ "GenSigTimeoutMsg" BU_SG_REL_ EBCM_HS SG_ 1034 CRL_CoefdA 1034;
BA_REL_ "GenSigTimeoutTime" BU_SG_REL_ EBCM_HS SG_ 1034 CRL_CoefdA 250;
BA_REL_ "GenSigSuprvResp" BU_SG_REL_ EBCM_OBD_HS SG_ 1034 CRL_CoefA 1;
BA_REL_ "GenSigTimeoutMsg" BU_SG_REL_ EBCM_OBD_HS SG_ 1034 CRL_CoefA 1034;
BA_REL_ "GenSigTimeoutTime" BU_SG_REL_ EBCM_OBD_HS SG_ 1034 CRL_CoefA 250;
BA_REL_ "GenSigSuprvResp" BU_SG_REL_ EBCM_HS SG_ 1034 CRL_CoefA 1;
BA_REL_ "GenSigTimeoutMsg" BU_SG_REL_ EBCM_HS SG_ 1034 CRL_CoefA 1034;
BA_REL_ "GenSigTimeoutTime" BU_SG_REL_ EBCM_HS SG_ 1034 CRL_CoefA 250;
BA_REL_ "GenSigSuprvResp" BU_SG_REL_ EBCM_OBD_HS SG_ 1033 CLL_Cnfdnc 1;
BA_REL_ "GenSigTimeoutMsg" BU_SG_REL_ EBCM_OBD_HS SG_ 1033 CLL_Cnfdnc 1033;
BA_REL_ "GenSigTimeoutTime" BU_SG_REL_ EBCM_OBD_HS SG_ 1033 CLL_Cnfdnc 250;
BA_REL_ "GenSigSuprvResp" BU_SG_REL_ EBCM_HS SG_ 1033 CLL_Cnfdnc 1;
BA_REL_ "GenSigTimeoutMsg" BU_SG_REL_ EBCM_HS SG_ 1033 CLL_Cnfdnc 1033;
BA_REL_ "GenSigTimeoutTime" BU_SG_REL_ EBCM_HS SG_ 1033 CLL_Cnfdnc 250;
BA_REL_ "GenSigSuprvResp" BU_SG_REL_ EBCM_OBD_HS SG_ 1033 CLL_ViewRng 1;
BA_REL_ "GenSigTimeoutMsg" BU_SG_REL_ EBCM_OBD_HS SG_ 1033 CLL_ViewRng 1033;
BA_REL_ "GenSigTimeoutTime" BU_SG_REL_ EBCM_OBD_HS SG_ 1033 CLL_ViewRng 250;
BA_REL_ "GenSigSuprvResp" BU_SG_REL_ EBCM_HS SG_ 1033 CLL_ViewRng 1;
BA_REL_ "GenSigTimeoutMsg" BU_SG_REL_ EBCM_HS SG_ 1033 CLL_ViewRng 1033;
BA_REL_ "GenSigTimeoutTime" BU_SG_REL_ EBCM_HS SG_ 1033 CLL_ViewRng 250;
BA_REL_ "GenSigSuprvResp" BU_SG_REL_ EBCM_OBD_HS SG_ 1033 CLL_CoefdA 1;
BA_REL_ "GenSigTimeoutMsg" BU_SG_REL_ EBCM_OBD_HS SG_ 1033 CLL_CoefdA 1033;
BA_REL_ "GenSigTimeoutTime" BU_SG_REL_ EBCM_OBD_HS SG_ 1033 CLL_CoefdA 250;
BA_REL_ "GenSigSuprvResp" BU_SG_REL_ EBCM_HS SG_ 1033 CLL_CoefdA 1;
BA_REL_ "GenSigTimeoutMsg" BU_SG_REL_ EBCM_HS SG_ 1033 CLL_CoefdA 1033;
BA_REL_ "GenSigTimeoutTime" BU_SG_REL_ EBCM_HS SG_ 1033 CLL_CoefdA 250;
BA_REL_ "GenSigSuprvResp" BU_SG_REL_ EBCM_OBD_HS SG_ 1033 CLL_CoefA 1;
BA_REL_ "GenSigTimeoutMsg" BU_SG_REL_ EBCM_OBD_HS SG_ 1033 CLL_CoefA 1033;
BA_REL_ "GenSigTimeoutTime" BU_SG_REL_ EBCM_OBD_HS SG_ 1033 CLL_CoefA 250;
BA_REL_ "GenSigSuprvResp" BU_SG_REL_ EBCM_HS SG_ 1033 CLL_CoefA 1;
BA_REL_ "GenSigTimeoutMsg" BU_SG_REL_ EBCM_HS SG_ 1033 CLL_CoefA 1033;
BA_REL_ "GenSigTimeoutTime" BU_SG_REL_ EBCM_HS SG_ 1033 CLL_CoefA 250;
BA_REL_ "GenSigSuprvResp" BU_SG_REL_ ICCM_HS SG_ 1013 TRDF_TransPrkRgDgFlt 1;
BA_REL_ "GenSigTimeoutMsg" BU_SG_REL_ ICCM_HS SG_ 1013 TRDF_TransPrkRgDgFlt 1013;
BA_REL_ "GenSigTimeoutTime" BU_SG_REL_ ICCM_HS SG_ 1013 TRDF_TransPrkRgDgFlt 625;
BA_REL_ "GenSigSuprvResp" BU_SG_REL_ ICCM_HS SG_ 1013 TRDF_TrsFwDrvRgDgFlt 1;
BA_REL_ "GenSigTimeoutMsg" BU_SG_REL_ ICCM_HS SG_ 1013 TRDF_TrsFwDrvRgDgFlt 1013;
BA_REL_ "GenSigTimeoutTime" BU_SG_REL_ ICCM_HS SG_ 1013 TRDF_TrsFwDrvRgDgFlt 625;
BA_REL_ "GenSigSuprvResp" BU_SG_REL_ ICCM_HS SG_ 1013 TRDF_TransNeutRgDgFlt 1;
BA_REL_ "GenSigTimeoutMsg" BU_SG_REL_ ICCM_HS SG_ 1013 TRDF_TransNeutRgDgFlt 1013;
BA_REL_ "GenSigTimeoutTime" BU_SG_REL_ ICCM_HS SG_ 1013 TRDF_TransNeutRgDgFlt 625;
BA_REL_ "GenSigSuprvResp" BU_SG_REL_ ICCM_HS SG_ 1013 TRDF_TransRvsRgDgFlt 1;
BA_REL_ "GenSigTimeoutMsg" BU_SG_REL_ ICCM_HS SG_ 1013 TRDF_TransRvsRgDgFlt 1013;
BA_REL_ "GenSigTimeoutTime" BU_SG_REL_ ICCM_HS SG_ 1013 TRDF_TransRvsRgDgFlt 625;
BA_REL_ "GenSigSuprvResp" BU_SG_REL_ EBCM_OBD_HS SG_ 1013 TrnRqHRBkCtlTgtVSpd 1;
BA_REL_ "GenSigTimeoutMsg" BU_SG_REL_ EBCM_OBD_HS SG_ 1013 TrnRqHRBkCtlTgtVSpd 1013;
BA_REL_ "GenSigTimeoutTime" BU_SG_REL_ EBCM_OBD_HS SG_ 1013 TrnRqHRBkCtlTgtVSpd 625;
BA_REL_ "GenSigSuprvResp" BU_SG_REL_ EBCM_HS SG_ 1013 TrnRqHRBkCtlTgtVSpd 1;
BA_REL_ "GenSigTimeoutMsg" BU_SG_REL_ EBCM_HS SG_ 1013 TrnRqHRBkCtlTgtVSpd 1013;
BA_REL_ "GenSigTimeoutTime" BU_SG_REL_ EBCM_HS SG_ 1013 TrnRqHRBkCtlTgtVSpd 625;
BA_REL_ "GenSigSuprvResp" BU_SG_REL_ EBCM_OBD_HS SG_ 1013 TransReqHSAAval 1;
BA_REL_ "GenSigTimeoutMsg" BU_SG_REL_ EBCM_OBD_HS SG_ 1013 TransReqHSAAval 1013;
BA_REL_ "GenSigTimeoutTime" BU_SG_REL_ EBCM_OBD_HS SG_ 1013 TransReqHSAAval 625;
BA_REL_ "GenSigSuprvResp" BU_SG_REL_ EBCM_HS SG_ 1013 TransReqHSAAval 1;
BA_REL_ "GenSigTimeoutMsg" BU_SG_REL_ EBCM_HS SG_ 1013 TransReqHSAAval 1013;
BA_REL_ "GenSigTimeoutTime" BU_SG_REL_ EBCM_HS SG_ 1013 TransReqHSAAval 625;
BA_REL_ "GenSigSuprvResp" BU_SG_REL_ BCM_HS SG_ 324 ActVbnCtrlMlfIO 1;
BA_REL_ "GenSigTimeoutMsg" BU_SG_REL_ BCM_HS SG_ 324 ActVbnCtrlMlfIO 324;
BA_REL_ "GenSigTimeoutTime" BU_SG_REL_ BCM_HS SG_ 324 ActVbnCtrlMlfIO 250;
BA_REL_ "GenSigSuprvResp" BU_SG_REL_ CGM_HS SG_ 844 IMUProtYawRt 1;
BA_REL_ "GenSigTimeoutMsg" BU_SG_REL_ CGM_HS SG_ 844 IMUProtYawRt 844;
BA_REL_ "GenSigTimeoutTime" BU_SG_REL_ CGM_HS SG_ 844 IMUProtYawRt 250;
BA_REL_ "GenSigSuprvResp" BU_SG_REL_ FCM_HS SG_ 844 IMUProtYawRt 1;
BA_REL_ "GenSigTimeoutMsg" BU_SG_REL_ FCM_HS SG_ 844 IMUProtYawRt 844;
BA_REL_ "GenSigTimeoutTime" BU_SG_REL_ FCM_HS SG_ 844 IMUProtYawRt 250;
BA_REL_ "GenSigSuprvResp" BU_SG_REL_ FCM_HS SG_ 844 IMUProtYawRt 1;
BA_REL_ "GenSigTimeoutMsg" BU_SG_REL_ FCM_HS SG_ 844 IMUProtYawRt 844;
BA_REL_ "GenSigTimeoutTime" BU_SG_REL_ FCM_HS SG_ 844 IMUProtYawRt 250;
BA_REL_ "GenSigSuprvResp" BU_SG_REL_ EPS_HS SG_ 844 IMUProtYawRt 1;
BA_REL_ "GenSigTimeoutMsg" BU_SG_REL_ EPS_HS SG_ 844 IMUProtYawRt 844;
BA_REL_ "GenSigTimeoutTime" BU_SG_REL_ EPS_HS SG_ 844 IMUProtYawRt 250;
BA_REL_ "GenSigSuprvResp" BU_SG_REL_ CGM_HS SG_ 844 IMUProtLonAcc 1;
BA_REL_ "GenSigTimeoutMsg" BU_SG_REL_ CGM_HS SG_ 844 IMUProtLonAcc 844;
BA_REL_ "GenSigTimeoutTime" BU_SG_REL_ CGM_HS SG_ 844 IMUProtLonAcc 250;
BA_REL_ "GenSigSuprvResp" BU_SG_REL_ FCM_HS SG_ 844 IMUProtLonAcc 1;
BA_REL_ "GenSigTimeoutMsg" BU_SG_REL_ FCM_HS SG_ 844 IMUProtLonAcc 844;
BA_REL_ "GenSigTimeoutTime" BU_SG_REL_ FCM_HS SG_ 844 IMUProtLonAcc 250;
BA_REL_ "GenSigSuprvResp" BU_SG_REL_ EPS_HS SG_ 844 IMUProtLonAcc 1;
BA_REL_ "GenSigTimeoutMsg" BU_SG_REL_ EPS_HS SG_ 844 IMUProtLonAcc 844;
BA_REL_ "GenSigTimeoutTime" BU_SG_REL_ EPS_HS SG_ 844 IMUProtLonAcc 250;
BA_REL_ "GenSigSuprvResp" BU_SG_REL_ CGM_HS SG_ 844 IMUProtLatAcc 1;
BA_REL_ "GenSigTimeoutMsg" BU_SG_REL_ CGM_HS SG_ 844 IMUProtLatAcc 844;
BA_REL_ "GenSigTimeoutTime" BU_SG_REL_ CGM_HS SG_ 844 IMUProtLatAcc 250;
BA_REL_ "GenSigSuprvResp" BU_SG_REL_ FCM_HS SG_ 844 IMUProtLatAcc 1;
BA_REL_ "GenSigTimeoutMsg" BU_SG_REL_ FCM_HS SG_ 844 IMUProtLatAcc 844;
BA_REL_ "GenSigTimeoutTime" BU_SG_REL_ FCM_HS SG_ 844 IMUProtLatAcc 250;
BA_REL_ "GenSigSuprvResp" BU_SG_REL_ EPS_HS SG_ 844 IMUProtLatAcc 1;
BA_REL_ "GenSigTimeoutMsg" BU_SG_REL_ EPS_HS SG_ 844 IMUProtLatAcc 844;
BA_REL_ "GenSigTimeoutTime" BU_SG_REL_ EPS_HS SG_ 844 IMUProtLatAcc 250;
BA_REL_ "GenSigSuprvResp" BU_SG_REL_ FCM_HS SG_ 844 IMUProtChksum 1;
BA_REL_ "GenSigTimeoutMsg" BU_SG_REL_ FCM_HS SG_ 844 IMUProtChksum 844;
BA_REL_ "GenSigTimeoutTime" BU_SG_REL_ FCM_HS SG_ 844 IMUProtChksum 250;
BA_REL_ "GenSigSuprvResp" BU_SG_REL_ FCM_HS SG_ 844 IMUProtChksum 1;
BA_REL_ "GenSigTimeoutMsg" BU_SG_REL_ FCM_HS SG_ 844 IMUProtChksum 844;
BA_REL_ "GenSigTimeoutTime" BU_SG_REL_ FCM_HS SG_ 844 IMUProtChksum 250;
BA_REL_ "GenSigSuprvResp" BU_SG_REL_ EPS_HS SG_ 844 IMUProtChksum 1;
BA_REL_ "GenSigTimeoutMsg" BU_SG_REL_ EPS_HS SG_ 844 IMUProtChksum 844;
BA_REL_ "GenSigTimeoutTime" BU_SG_REL_ EPS_HS SG_ 844 IMUProtChksum 250;
BA_REL_ "GenSigSuprvResp" BU_SG_REL_ FCM_HS SG_ 844 IMUProtARC 1;
BA_REL_ "GenSigTimeoutMsg" BU_SG_REL_ FCM_HS SG_ 844 IMUProtARC 844;
BA_REL_ "GenSigTimeoutTime" BU_SG_REL_ FCM_HS SG_ 844 IMUProtARC 250;
BA_REL_ "GenSigSuprvResp" BU_SG_REL_ FCM_HS SG_ 844 IMUProtARC 1;
BA_REL_ "GenSigTimeoutMsg" BU_SG_REL_ FCM_HS SG_ 844 IMUProtARC 844;
BA_REL_ "GenSigTimeoutTime" BU_SG_REL_ FCM_HS SG_ 844 IMUProtARC 250;
BA_REL_ "GenSigSuprvResp" BU_SG_REL_ EPS_HS SG_ 844 IMUProtARC 1;
BA_REL_ "GenSigTimeoutMsg" BU_SG_REL_ EPS_HS SG_ 844 IMUProtARC 844;
BA_REL_ "GenSigTimeoutTime" BU_SG_REL_ EPS_HS SG_ 844 IMUProtARC 250;
BA_REL_ "GenSigSuprvResp" BU_SG_REL_ BCM_HS SG_ 806 DCCnvStblznErrIO 1;
BA_REL_ "GenSigTimeoutMsg" BU_SG_REL_ BCM_HS SG_ 806 DCCnvStblznErrIO 806;
BA_REL_ "GenSigTimeoutTime" BU_SG_REL_ BCM_HS SG_ 806 DCCnvStblznErrIO 1250;
BA_REL_ "GenSigSuprvResp" BU_SG_REL_ HCP_T_HS SG_ 426 EngPstnSnsngOpMode 1;
BA_REL_ "GenSigTimeoutMsg" BU_SG_REL_ HCP_T_HS SG_ 426 EngPstnSnsngOpMode 426;
BA_REL_ "GenSigTimeoutTime" BU_SG_REL_ HCP_T_HS SG_ 426 EngPstnSnsngOpMode 250;
BA_REL_ "GenSigSuprvResp" BU_SG_REL_ HCP_HS SG_ 426 EngPstnSnsngOpMode 1;
BA_REL_ "GenSigTimeoutMsg" BU_SG_REL_ HCP_HS SG_ 426 EngPstnSnsngOpMode 426;
BA_REL_ "GenSigTimeoutTime" BU_SG_REL_ HCP_HS SG_ 426 EngPstnSnsngOpMode 250;
BA_REL_ "GenSigSuprvResp" BU_SG_REL_ HCP_B_HS SG_ 426 EngPstnSnsngOpMode 1;
BA_REL_ "GenSigTimeoutMsg" BU_SG_REL_ HCP_B_HS SG_ 426 EngPstnSnsngOpMode 426;
BA_REL_ "GenSigTimeoutTime" BU_SG_REL_ HCP_B_HS SG_ 426 EngPstnSnsngOpMode 250;
BA_REL_ "GenSigSuprvResp" BU_SG_REL_ TCM_HS SG_ 426 AuxTransPrsCmndOn 1;
BA_REL_ "GenSigTimeoutMsg" BU_SG_REL_ TCM_HS SG_ 426 AuxTransPrsCmndOn 426;
BA_REL_ "GenSigTimeoutTime" BU_SG_REL_ TCM_HS SG_ 426 AuxTransPrsCmndOn 250;
BA_REL_ "GenSigSuprvResp" BU_SG_REL_ HCP_T_HS SG_ 426 EVTCS_CmdTrqCapMd 1;
BA_REL_ "GenSigTimeoutMsg" BU_SG_REL_ HCP_T_HS SG_ 426 EVTCS_CmdTrqCapMd 426;
BA_REL_ "GenSigTimeoutTime" BU_SG_REL_ HCP_T_HS SG_ 426 EVTCS_CmdTrqCapMd 250;
BA_REL_ "GenSigSuprvResp" BU_SG_REL_ TCM_HS SG_ 426 EVTCS_CmdTrqCapMd 1;
BA_REL_ "GenSigTimeoutMsg" BU_SG_REL_ TCM_HS SG_ 426 EVTCS_CmdTrqCapMd 426;
BA_REL_ "GenSigTimeoutTime" BU_SG_REL_ TCM_HS SG_ 426 EVTCS_CmdTrqCapMd 250;
BA_REL_ "GenSigSuprvResp" BU_SG_REL_ HCP_HS SG_ 426 EVTCS_CmdTrqCapMd 1;
BA_REL_ "GenSigTimeoutMsg" BU_SG_REL_ HCP_HS SG_ 426 EVTCS_CmdTrqCapMd 426;
BA_REL_ "GenSigTimeoutTime" BU_SG_REL_ HCP_HS SG_ 426 EVTCS_CmdTrqCapMd 250;
BA_REL_ "GenSigSuprvResp" BU_SG_REL_ HCP_B_HS SG_ 426 EVTCS_CmdTrqCapMd 1;
BA_REL_ "GenSigTimeoutMsg" BU_SG_REL_ HCP_B_HS SG_ 426 EVTCS_CmdTrqCapMd 426;
BA_REL_ "GenSigTimeoutTime" BU_SG_REL_ HCP_B_HS SG_ 426 EVTCS_CmdTrqCapMd 250;
BA_REL_ "GenSigSuprvResp" BU_SG_REL_ HCP_T_HS SG_ 426 EVTCS_CrntTrqCapMd 1;
BA_REL_ "GenSigTimeoutMsg" BU_SG_REL_ HCP_T_HS SG_ 426 EVTCS_CrntTrqCapMd 426;
BA_REL_ "GenSigTimeoutTime" BU_SG_REL_ HCP_T_HS SG_ 426 EVTCS_CrntTrqCapMd 250;
BA_REL_ "GenSigSuprvResp" BU_SG_REL_ TCM_HS SG_ 426 EVTCS_CrntTrqCapMd 1;
BA_REL_ "GenSigTimeoutMsg" BU_SG_REL_ TCM_HS SG_ 426 EVTCS_CrntTrqCapMd 426;
BA_REL_ "GenSigTimeoutTime" BU_SG_REL_ TCM_HS SG_ 426 EVTCS_CrntTrqCapMd 250;
BA_REL_ "GenSigSuprvResp" BU_SG_REL_ HCP_HS SG_ 426 EVTCS_CrntTrqCapMd 1;
BA_REL_ "GenSigTimeoutMsg" BU_SG_REL_ HCP_HS SG_ 426 EVTCS_CrntTrqCapMd 426;
BA_REL_ "GenSigTimeoutTime" BU_SG_REL_ HCP_HS SG_ 426 EVTCS_CrntTrqCapMd 250;
BA_REL_ "GenSigSuprvResp" BU_SG_REL_ HCP_B_HS SG_ 426 EVTCS_CrntTrqCapMd 1;
BA_REL_ "GenSigTimeoutMsg" BU_SG_REL_ HCP_B_HS SG_ 426 EVTCS_CrntTrqCapMd 426;
BA_REL_ "GenSigTimeoutTime" BU_SG_REL_ HCP_B_HS SG_ 426 EVTCS_CrntTrqCapMd 250;
BA_REL_ "GenSigSuprvResp" BU_SG_REL_ TCM_HS SG_ 426 EngPrdctStdyStTorq 1;
BA_REL_ "GenSigTimeoutMsg" BU_SG_REL_ TCM_HS SG_ 426 EngPrdctStdyStTorq 426;
BA_REL_ "GenSigTimeoutTime" BU_SG_REL_ TCM_HS SG_ 426 EngPrdctStdyStTorq 250;
BA_REL_ "GenSigSuprvResp" BU_SG_REL_ TCM_HS SG_ 426 CrnkShftTrqMinOffCap 1;
BA_REL_ "GenSigTimeoutMsg" BU_SG_REL_ TCM_HS SG_ 426 CrnkShftTrqMinOffCap 426;
BA_REL_ "GenSigTimeoutTime" BU_SG_REL_ TCM_HS SG_ 426 CrnkShftTrqMinOffCap 250;
BA_REL_ "GenSigSuprvResp" BU_SG_REL_ TCM_HS SG_ 426 CrksftTqMinRunImCap 1;
BA_REL_ "GenSigTimeoutMsg" BU_SG_REL_ TCM_HS SG_ 426 CrksftTqMinRunImCap 426;
BA_REL_ "GenSigTimeoutTime" BU_SG_REL_ TCM_HS SG_ 426 CrksftTqMinRunImCap 250;
BA_REL_ "GenSigSuprvResp" BU_SG_REL_ BCM_HS SG_ 1231 DslExhFluidDistTIndcmt 1;
BA_REL_ "GenSigTimeoutMsg" BU_SG_REL_ BCM_HS SG_ 1231 DslExhFluidDistTIndcmt 1231;
BA_REL_ "GenSigTimeoutTime" BU_SG_REL_ BCM_HS SG_ 1231 DslExhFluidDistTIndcmt 2500;
BA_REL_ "GenSigSuprvResp" BU_SG_REL_ BCM_HS SG_ 1231 DslExhFluidLvlPrcnt 1;
BA_REL_ "GenSigTimeoutMsg" BU_SG_REL_ BCM_HS SG_ 1231 DslExhFluidLvlPrcnt 1231;
BA_REL_ "GenSigTimeoutTime" BU_SG_REL_ BCM_HS SG_ 1231 DslExhFluidLvlPrcnt 2500;
BA_REL_ "GenSigSuprvResp" BU_SG_REL_ ECM_HS SG_ 963 CltTmpCntlMdEmRMAct 1;
BA_REL_ "GenSigTimeoutMsg" BU_SG_REL_ ECM_HS SG_ 963 CltTmpCntlMdEmRMAct 963;
BA_REL_ "GenSigTimeoutTime" BU_SG_REL_ ECM_HS SG_ 963 CltTmpCntlMdEmRMAct 250;
BA_REL_ "GenSigSuprvResp" BU_SG_REL_ ECM_HS SG_ 963 CTCMERDTC_SysDes 1;
BA_REL_ "GenSigTimeoutMsg" BU_SG_REL_ ECM_HS SG_ 963 CTCMERDTC_SysDes 963;
BA_REL_ "GenSigTimeoutTime" BU_SG_REL_ ECM_HS SG_ 963 CTCMERDTC_SysDes 250;
BA_REL_ "GenSigSuprvResp" BU_SG_REL_ ECM_HS SG_ 963 CTCMERDTC_CdNum 1;
BA_REL_ "GenSigTimeoutMsg" BU_SG_REL_ ECM_HS SG_ 963 CTCMERDTC_CdNum 963;
BA_REL_ "GenSigTimeoutTime" BU_SG_REL_ ECM_HS SG_ 963 CTCMERDTC_CdNum 250;
BA_REL_ "GenSigSuprvResp" BU_SG_REL_ ECM_HS SG_ 955 RdctHtrCrntFdbckRC 1;
BA_REL_ "GenSigTimeoutMsg" BU_SG_REL_ ECM_HS SG_ 955 RdctHtrCrntFdbckRC 955;
BA_REL_ "GenSigTimeoutTime" BU_SG_REL_ ECM_HS SG_ 955 RdctHtrCrntFdbckRC 250;
BA_REL_ "GenSigSuprvResp" BU_SG_REL_ ECM_HS SG_ 955 RdctHtrCctStatPV 1;
BA_REL_ "GenSigTimeoutMsg" BU_SG_REL_ ECM_HS SG_ 955 RdctHtrCctStatPV 955;
BA_REL_ "GenSigTimeoutTime" BU_SG_REL_ ECM_HS SG_ 955 RdctHtrCctStatPV 250;
BA_REL_ "GenSigSuprvResp" BU_SG_REL_ ECM_HS SG_ 955 RdctHtrCCrntFdbckPVa 1;
BA_REL_ "GenSigTimeoutMsg" BU_SG_REL_ ECM_HS SG_ 955 RdctHtrCCrntFdbckPVa 955;
BA_REL_ "GenSigTimeoutTime" BU_SG_REL_ ECM_HS SG_ 955 RdctHtrCCrntFdbckPVa 250;
BA_REL_ "GenSigSuprvResp" BU_SG_REL_ ECM_HS SG_ 955 RdctHtrCCrntFdbckPVa 1;
BA_REL_ "GenSigTimeoutMsg" BU_SG_REL_ ECM_HS SG_ 955 RdctHtrCCrntFdbckPVa 955;
BA_REL_ "GenSigTimeoutTime" BU_SG_REL_ ECM_HS SG_ 955 RdctHtrCCrntFdbckPVa 250;
BA_REL_ "GenSigSuprvResp" BU_SG_REL_ ECM_HS SG_ 955 RdctHtrBCrntFdbckPVa 1;
BA_REL_ "GenSigTimeoutMsg" BU_SG_REL_ ECM_HS SG_ 955 RdctHtrBCrntFdbckPVa 955;
BA_REL_ "GenSigTimeoutTime" BU_SG_REL_ ECM_HS SG_ 955 RdctHtrBCrntFdbckPVa 250;
BA_REL_ "GenSigSuprvResp" BU_SG_REL_ ECM_HS SG_ 955 RdctHtrBCrntFdbckPVa 1;
BA_REL_ "GenSigTimeoutMsg" BU_SG_REL_ ECM_HS SG_ 955 RdctHtrBCrntFdbckPVa 955;
BA_REL_ "GenSigTimeoutTime" BU_SG_REL_ ECM_HS SG_ 955 RdctHtrBCrntFdbckPVa 250;
BA_REL_ "GenSigSuprvResp" BU_SG_REL_ ECM_HS SG_ 955 RdctHtrACrntFdbckPVa 1;
BA_REL_ "GenSigTimeoutMsg" BU_SG_REL_ ECM_HS SG_ 955 RdctHtrACrntFdbckPVa 955;
BA_REL_ "GenSigTimeoutTime" BU_SG_REL_ ECM_HS SG_ 955 RdctHtrACrntFdbckPVa 250;
BA_REL_ "GenSigSuprvResp" BU_SG_REL_ ECM_HS SG_ 955 RdctHtrACrntFdbckPVa 1;
BA_REL_ "GenSigTimeoutMsg" BU_SG_REL_ ECM_HS SG_ 955 RdctHtrACrntFdbckPVa 955;
BA_REL_ "GenSigTimeoutTime" BU_SG_REL_ ECM_HS SG_ 955 RdctHtrACrntFdbckPVa 250;
BA_REL_ "GenSigSuprvResp" BU_SG_REL_ ECM_HS SG_ 955 RdctHtrCCrntFdbck 1;
BA_REL_ "GenSigTimeoutMsg" BU_SG_REL_ ECM_HS SG_ 955 RdctHtrCCrntFdbck 955;
BA_REL_ "GenSigTimeoutTime" BU_SG_REL_ ECM_HS SG_ 955 RdctHtrCCrntFdbck 250;
BA_REL_ "GenSigSuprvResp" BU_SG_REL_ ECM_HS SG_ 955 RdctHtrCCrntFdbck 1;
BA_REL_ "GenSigTimeoutMsg" BU_SG_REL_ ECM_HS SG_ 955 RdctHtrCCrntFdbck 955;
BA_REL_ "GenSigTimeoutTime" BU_SG_REL_ ECM_HS SG_ 955 RdctHtrCCrntFdbck 250;
BA_REL_ "GenSigSuprvResp" BU_SG_REL_ ECM_HS SG_ 955 RdctHtrBCrntFdbck 1;
BA_REL_ "GenSigTimeoutMsg" BU_SG_REL_ ECM_HS SG_ 955 RdctHtrBCrntFdbck 955;
BA_REL_ "GenSigTimeoutTime" BU_SG_REL_ ECM_HS SG_ 955 RdctHtrBCrntFdbck 250;
BA_REL_ "GenSigSuprvResp" BU_SG_REL_ ECM_HS SG_ 955 RdctHtrBCrntFdbck 1;
BA_REL_ "GenSigTimeoutMsg" BU_SG_REL_ ECM_HS SG_ 955 RdctHtrBCrntFdbck 955;
BA_REL_ "GenSigTimeoutTime" BU_SG_REL_ ECM_HS SG_ 955 RdctHtrBCrntFdbck 250;
BA_REL_ "GenSigSuprvResp" BU_SG_REL_ ECM_HS SG_ 955 RdctHtrACrntFdbck 1;
BA_REL_ "GenSigTimeoutMsg" BU_SG_REL_ ECM_HS SG_ 955 RdctHtrACrntFdbck 955;
BA_REL_ "GenSigTimeoutTime" BU_SG_REL_ ECM_HS SG_ 955 RdctHtrACrntFdbck 250;
BA_REL_ "GenSigSuprvResp" BU_SG_REL_ ECM_HS SG_ 955 RdctHtrACrntFdbck 1;
BA_REL_ "GenSigTimeoutMsg" BU_SG_REL_ ECM_HS SG_ 955 RdctHtrACrntFdbck 955;
BA_REL_ "GenSigTimeoutTime" BU_SG_REL_ ECM_HS SG_ 955 RdctHtrACrntFdbck 250;
BA_REL_ "GenSigSuprvResp" BU_SG_REL_ HCP_HS SG_ 423 TransHydrlcDfltgAct 1;
BA_REL_ "GenSigTimeoutMsg" BU_SG_REL_ HCP_HS SG_ 423 TransHydrlcDfltgAct 423;
BA_REL_ "GenSigTimeoutTime" BU_SG_REL_ HCP_HS SG_ 423 TransHydrlcDfltgAct 250;
BA_REL_ "GenSigSuprvResp" BU_SG_REL_ HCP_HS SG_ 423 TCFS_Cltch5FltStat 1;
BA_REL_ "GenSigTimeoutMsg" BU_SG_REL_ HCP_HS SG_ 423 TCFS_Cltch5FltStat 423;
BA_REL_ "GenSigTimeoutTime" BU_SG_REL_ HCP_HS SG_ 423 TCFS_Cltch5FltStat 250;
BA_REL_ "GenSigSuprvResp" BU_SG_REL_ HCP_HS SG_ 423 TCFS_Cltch4FltStat 1;
BA_REL_ "GenSigTimeoutMsg" BU_SG_REL_ HCP_HS SG_ 423 TCFS_Cltch4FltStat 423;
BA_REL_ "GenSigTimeoutTime" BU_SG_REL_ HCP_HS SG_ 423 TCFS_Cltch4FltStat 250;
BA_REL_ "GenSigSuprvResp" BU_SG_REL_ HCP_HS SG_ 423 TCFS_Cltch3FltStat 1;
BA_REL_ "GenSigTimeoutMsg" BU_SG_REL_ HCP_HS SG_ 423 TCFS_Cltch3FltStat 423;
BA_REL_ "GenSigTimeoutTime" BU_SG_REL_ HCP_HS SG_ 423 TCFS_Cltch3FltStat 250;
BA_REL_ "GenSigSuprvResp" BU_SG_REL_ HCP_HS SG_ 423 TCFS_Cltch2FltStat 1;
BA_REL_ "GenSigTimeoutMsg" BU_SG_REL_ HCP_HS SG_ 423 TCFS_Cltch2FltStat 423;
BA_REL_ "GenSigTimeoutTime" BU_SG_REL_ HCP_HS SG_ 423 TCFS_Cltch2FltStat 250;
BA_REL_ "GenSigSuprvResp" BU_SG_REL_ HCP_HS SG_ 423 TCFS_Cltch1FltStat 1;
BA_REL_ "GenSigTimeoutMsg" BU_SG_REL_ HCP_HS SG_ 423 TCFS_Cltch1FltStat 423;
BA_REL_ "GenSigTimeoutTime" BU_SG_REL_ HCP_HS SG_ 423 TCFS_Cltch1FltStat 250;
BA_REL_ "GenSigSuprvResp" BU_SG_REL_ HCP_HS SG_ 423 TCAS_Cltch5AvlbltyStat 1;
BA_REL_ "GenSigTimeoutMsg" BU_SG_REL_ HCP_HS SG_ 423 TCAS_Cltch5AvlbltyStat 423;
BA_REL_ "GenSigTimeoutTime" BU_SG_REL_ HCP_HS SG_ 423 TCAS_Cltch5AvlbltyStat 250;
BA_REL_ "GenSigSuprvResp" BU_SG_REL_ HCP_HS SG_ 423 TCAS_Cltch4AvlbltyStat 1;
BA_REL_ "GenSigTimeoutMsg" BU_SG_REL_ HCP_HS SG_ 423 TCAS_Cltch4AvlbltyStat 423;
BA_REL_ "GenSigTimeoutTime" BU_SG_REL_ HCP_HS SG_ 423 TCAS_Cltch4AvlbltyStat 250;
BA_REL_ "GenSigSuprvResp" BU_SG_REL_ HCP_HS SG_ 423 TCAS_Cltch3AvlbltyStat 1;
BA_REL_ "GenSigTimeoutMsg" BU_SG_REL_ HCP_HS SG_ 423 TCAS_Cltch3AvlbltyStat 423;
BA_REL_ "GenSigTimeoutTime" BU_SG_REL_ HCP_HS SG_ 423 TCAS_Cltch3AvlbltyStat 250;
BA_REL_ "GenSigSuprvResp" BU_SG_REL_ HCP_HS SG_ 423 TCAS_Cltch2AvlbltyStat 1;
BA_REL_ "GenSigTimeoutMsg" BU_SG_REL_ HCP_HS SG_ 423 TCAS_Cltch2AvlbltyStat 423;
BA_REL_ "GenSigTimeoutTime" BU_SG_REL_ HCP_HS SG_ 423 TCAS_Cltch2AvlbltyStat 250;
BA_REL_ "GenSigSuprvResp" BU_SG_REL_ HCP_HS SG_ 423 TCAS_Cltch1AvlbltyStat 1;
BA_REL_ "GenSigTimeoutMsg" BU_SG_REL_ HCP_HS SG_ 423 TCAS_Cltch1AvlbltyStat 423;
BA_REL_ "GenSigTimeoutTime" BU_SG_REL_ HCP_HS SG_ 423 TCAS_Cltch1AvlbltyStat 250;
VAL_ 705 TransActlRng 15 "Unused and Reserved2" 14 "Unused and Reserved1" 13 "Fourth Drive Position" 12 "Between Third and Fourth Drive Position" 11 "Third Drive Position" 10 "Between Second and Third Drive Position" 9 "Second Drive Position" 8 "Between First and Second Drive Position" 7 "First Drive Position" 6 "Between Neutral and First Drive Position" 5 "Neutral Position" 4 "Between Reverse and Neutral" 3 "Reverse Position" 2 "Between Park and Reverse" 1 "Park Position" 0 "Unknown Position" ;
VAL_ 503 ElcTransRngRq 7 "Unused and Reserved" 6 "Manual Range" 5 "Low Range" 4 "Drive" 3 "Neutral" 2 "Reverse" 1 "Park" 0 "No Request" ;
VAL_ 872 ESBR_AutoBrkgRqTyp 3 "Unused and Reserved" 2 "Hold Deny Driver Release" 1 "Hold Allow Driver Release" 0 "Release" ;
VAL_ 872 ESBR_AutoBrkgRqd 1 "Braking Requested" 0 "Braking Not Requested " ;
VAL_ 353 ElecShfRngDisp 15 "Unused & Reserved" 14 "Unused & Reserved" 13 "Unused & Reserved" 12 "Park Requested And Denied" 11 "Drive Requested And In Progress" 10 "Neutral Requested And In Progress" 9 "Reverse Requested And In Progress" 8 "Park Requested And In Progress" 7 "Reserved" 6 "Manual Nominal" 5 "Low Nominal" 4 "Drive Nominal" 3 "Neutral Nominal" 2 "Reverse Nominal" 1 "Park Nominal" 0 "No Display " ;
VAL_ 353 ESPTransMalfIO 1 "true" 0 "false" ;
VAL_ 353 ESPRngInvldReqIO 1 "true" 0 "false" ;
VAL_ 353 ESPPrkInvldReqIO 1 "true" 0 "false" ;
VAL_ 353 ESPHldShfLvrToEngRgIO 1 "true" 0 "false" ;
VAL_ 353 ESPDrvrPrkIlkSftAtdIO 1 "true" 0 "false" ;
VAL_ 353 ESPDrvrIlkShfAtdIO 1 "true" 0 "false" ;
VAL_ 1275 BrkSyCtl2EmsRldMlfAct 1 "true" 0 "false" ;
VAL_ 1275 BSC2ERDTC_SysDes 15 "U3-Network Codes Reserved" 14 "U2-Network Codes Reserved" 13 "U1-Network Codes MFG Controlled" 12 "U0-Network Codes SAE Controlled" 11 "B3-Body Codes Reserved" 10 "B2-Body Codes Reserved" 9 "B1-Body Codes MFG Controlled" 8 "B0-Body Codes SAE Controlled" 7 "C3-Chassis Codes Reserved" 6 "C2-Chassis Codes Reserved" 5 "C1-Chassis Codes MFG Controlled" 4 "C0-Chassis Codes SAE Controlled" 3 "P3-Powertrain Codes Reserved" 2 "P2-Powertrain Codes Reserved" 1 "P1-Powertrain Codes MFG Controlled" 0 "P0-Powertrain Codes SAE Controlled" ;
VAL_ 1275 EBrkAstStat 7 "Faulted" 6 "Temporarily Failed" 5 "Not Used" 4 "Not Used" 3 "Not Used" 2 "Normal" 1 "Initializing" 0 "Not Initialized" ;
VAL_ 1273 BrkSyCtl1EmsRldMlfAct 1 "true" 0 "false" ;
VAL_ 1273 BSC1ERDTC_SysDes 15 "U3-Network Codes Reserved" 14 "U2-Network Codes Reserved" 13 "U1-Network Codes MFG Controlled" 12 "U0-Network Codes SAE Controlled" 11 "B3-Body Codes Reserved" 10 "B2-Body Codes Reserved" 9 "B1-Body Codes MFG Controlled" 8 "B0-Body Codes SAE Controlled" 7 "C3-Chassis Codes Reserved" 6 "C2-Chassis Codes Reserved" 5 "C1-Chassis Codes MFG Controlled" 4 "C0-Chassis Codes SAE Controlled" 3 "P3-Powertrain Codes Reserved" 2 "P2-Powertrain Codes Reserved" 1 "P1-Powertrain Codes MFG Controlled" 0 "P0-Powertrain Codes SAE Controlled" ;
VAL_ 1271 BatSvrMdLvl7Act 1 "true" 0 "false" ;
VAL_ 1271 BSMCT_Mult 3 "Multiplier Factor 256" 2 "Multiplier Factor 64" 1 "Multiplier Factor 8" 0 "Multiplier Factor 1" ;
VAL_ 1271 BatSvrMdLvl6Act 1 "true" 0 "false" ;
VAL_ 1271 BatSvrMdLvl5Act 1 "true" 0 "false" ;
VAL_ 1271 BatSvrMdLvl4Act 1 "true" 0 "false" ;
VAL_ 558 CDP_HVDevShtdnCdARCSt 2 "Indeterminate" 1 "Fault" 0 "No Fault" ;
VAL_ 558 CDP_CmpSpdReqARCSt 2 "Indeterminate" 1 "Fault" 0 "No Fault" ;
VAL_ 558 CDP_CmpLossCommOcc 1 "true" 0 "false" ;
VAL_ 558 CDP_CmpWkUp 1 "true" 0 "false" ;
VAL_ 558 CDP_CmpRunCrnk 1 "true" 0 "false" ;
VAL_ 558 CDSP_CmpOvrTmpSt 2 "Indeterminate" 1 "Fault" 0 "No Fault" ;
VAL_ 558 CDSP_CmpHVAbnrlOrVltSt 2 "Indeterminate" 1 "Fault" 0 "No Fault" ;
VAL_ 558 CDSP_CmpHVUndrVltgSt 2 "Indeterminate" 1 "Fault" 0 "No Fault" ;
VAL_ 558 CDSP_CmpHVOvrVltgSt 2 "Indeterminate" 1 "Fault" 0 "No Fault" ;
VAL_ 558 CDSP_CmpHVOvrCrntSt 2 "Indeterminate" 1 "Fault" 0 "No Fault" ;
VAL_ 558 CDSP_OvrTempWrnInd 1 "true" 0 "false" ;
VAL_ 558 CDSP_CmpDgrdOp 1 "true" 0 "false" ;
VAL_ 558 CDSP_CmpIntShdwnFltSt 2 "Indeterminate" 1 "Fault" 0 "No Fault" ;
VAL_ 558 CDSP_CmpIntRecblFltSt 2 "Indeterminate" 1 "Fault" 0 "No Fault" ;
VAL_ 558 CDSP_CmpOpOvrldSt 2 "Indeterminate" 1 "Fault" 0 "No Fault" ;
VAL_ 558 CDSP_CmpDrCrctFltSt 2 "Indeterminate" 1 "Fault" 0 "No Fault" ;
VAL_ 558 CDSP_CmpMtrPerfFltSt 2 "Indeterminate" 1 "Fault" 0 "No Fault" ;
VAL_ 558 CDSP_CmpEEPROMFltSt 2 "Indeterminate" 1 "Fault" 0 "No Fault" ;
VAL_ 558 CDSP_CmpROMFltSt 2 "Indeterminate" 1 "Fault" 0 "No Fault" ;
VAL_ 558 CDSP_CmpRAMFltSt 2 "Indeterminate" 1 "Fault" 0 "No Fault" ;
VAL_ 558 CSSP_CmpIGBTTpOtRgLSt 2 "Indeterminate" 1 "Fault" 0 "No Fault" ;
VAL_ 558 CSSP_CmpIGBTTpOtRgHSt 2 "Indeterminate" 1 "Fault" 0 "No Fault" ;
VAL_ 558 CSSP_CmpCPUTmpOtRgLSt 2 "Indeterminate" 1 "Fault" 0 "No Fault" ;
VAL_ 558 CSSP_CmpCPUTmpOtRgHSt 2 "Indeterminate" 1 "Fault" 0 "No Fault" ;
VAL_ 558 CSSP_CmpHVSnsOtRgLSt 2 "Indeterminate" 1 "Fault" 0 "No Fault" ;
VAL_ 558 CSSP_CmpHVSnsOtRgHSt 2 "Indeterminate" 1 "Fault" 0 "No Fault" ;
VAL_ 558 CSSP_CmpPhCrntOtRgLSt 2 "Indeterminate" 1 "Fault" 0 "No Fault" ;
VAL_ 558 CSSP_CmpPhCrntOtRgHSt 2 "Indeterminate" 1 "Fault" 0 "No Fault" ;
VAL_ 663 RdGasFuelDevDisStat 3 "Reserved" 2 "Fault" 1 "Not Faulted" 0 "Indeterminate" ;
VAL_ 663 RdFInjCtrlMdIFltAct 1 "true" 0 "false" ;
VAL_ 663 RdDistFuelMdReq 5 "Fault Transition Required" 4 "Fault Transition Requested" 3 "FICM" 2 "Dual" 1 "ECM" 0 "Indeterminate" ;
VAL_ 663 RdDistFuelMdCmdRes 3 "FICM" 2 "Dual" 1 "ECM" 0 "Indeterminate" ;
VAL_ 663 RdAltFuelSysStat 3 "Reserved" 2 "Fuel System Ready" 1 "Fuel System Priming" 0 "Fuel System Inactive" ;
VAL_ 663 AltFuelInjRCRstOcc 1 "true" 0 "false" ;
VAL_ 1263 BattSOXStat 1 "Use SOC,SOH, & SOF" 0 "Don't Use SOC,SOH, & SOF" ;
VAL_ 1261 MinCrnkCrntVltStat 1 "Use Data" 0 "Don't Use Data" ;
VAL_ 1261 BattTempV 1 "Invalid" 0 "Valid" ;
VAL_ 1261 BattTempM 1 "Use Data" 0 "Don't Use Data" ;
VAL_ 1259 AllNodesVNA 1 "Activate Virtual Network" 0 "No Activation" ;
VAL_ 1259 NAHrDisChrgM 1 "Use Data" 0 "Don't Use Data" ;
VAL_ 1259 NAHrChgM 1 "Use Data" 0 "Don't Use Data" ;
VAL_ 1034 CRL_Cnfdnc 7 "Reserved4" 6 "Reserved3" 5 "Reserved2" 4 "Reserved1" 3 "Best" 2 "Marking Present" 1 "Weak Marking" 0 "No Lane" ;
VAL_ 1033 CLL_Cnfdnc 7 "Reserved4" 6 "Reserved3" 5 "Reserved2" 4 "Reserved1" 3 "Best" 2 "Marking Present" 1 "Weak Marking" 0 "No Lane" ;
VAL_ 1013 TRDF_TransPrkRgDgFlt 1 "true" 0 "false" ;
VAL_ 1013 TRDF_TrsFwDrvRgDgFlt 1 "true" 0 "false" ;
VAL_ 1013 TRDF_TransNeutRgDgFlt 1 "true" 0 "false" ;
VAL_ 1013 TRDF_TransRvsRgDgFlt 1 "true" 0 "false" ;
VAL_ 1013 TrnRqHRBkCtlTgtVSpd 0 "Normal" 1 "Reduced Speed 1" 2 "Reduced Speed 2" 3 "Reduced Speed 3" ;
VAL_ 1013 TransReqHSAAval 0 "Normal" 1 "Level 1" 2 "Level 2" 3 "Level 3" ;
VAL_ 425 TransClch5FlAch 1 "true" 0 "false" ;
VAL_ 425 TransClch4FlAch 1 "true" 0 "false" ;
VAL_ 424 TransClch3FlAch 1 "true" 0 "false" ;
VAL_ 424 TransClch2FlAch 1 "true" 0 "false" ;
VAL_ 324 ActVbnCtrlMlfIO 1 "true" 0 "false" ;
VAL_ 844 IMUProtYawRtM 0 "Don't Use Data" 1 "Use Data" ;
VAL_ 844 IMUProtLonAccM 0 "Don't Use Data" 1 "Use Data" ;
VAL_ 844 IMUProtLatAccM 0 "Don't Use Data" 1 "Use Data" ;
VAL_ 308 PFAS_SrvPedAlrtIO 1 "true" 0 "false" ;
VAL_ 308 PFAS_PFASysStat 0 "Disable" 1 "Active" 2 "Fault" 3 "Unused and Reserved" ;
VAL_ 308 PFAS_PFASndGenEn 1 "true" 0 "false" ;
VAL_ 308 PFAS_PFARevSnd 0 "No Action" 1 "Sound #1" 2 "Sound #2" 3 "Sound #3" ;
VAL_ 308 PFAS_PFAFwdSnd 0 "No Action" 1 "Sound #1" 2 "Sound #2" 3 "Sound #3" ;
VAL_ 308 PedFrndlyAlrtCsSetAvl 1 "true" 0 "false" ;
VAL_ 308 PedFrndlyAlrtCsCrStVal 0 "No Value" 1 "Off" 2 "On" ;
VAL_ 806 DCCnvStblznErrIO 1 "true" 0 "false" ;
VAL_ 426 EngPstnSnsngOpMode 2 "CAM Failed" 1 "Crank Failed" 0 "Normal" ;
VAL_ 426 AuxTransPrsCmndOn 1 "true" 0 "false" ;
VAL_ 426 EVTCS_CmdTrqCapMd 0 "Full Torque Capacity" 1 "Reduced Capacity 1" 2 "Reserved 1" 3 "Reserved 2" 4 "Reserved 3" 5 "Reserved 4" 6 "Reserved 5" 7 "Reserved 6" ;
VAL_ 426 EVTCS_CrntTrqCapMd 0 "Full Torque Capacity" 1 "Reduced Capacity 1" 2 "Reserved 1" 3 "Reserved 2" 4 "Reserved 3" 5 "Reserved 4" 6 "Reserved 5" 7 "Reserved 6" ;
VAL_ 426 EngPrdctStdyStTorqV 1 "Invalid" 0 "Valid" ;
VAL_ 426 CrnkShftTrqMinOffCapV 1 "Invalid" 0 "Valid" ;
VAL_ 426 CrksftTqMinRunImCapV 1 "Invalid" 0 "Valid" ;
VAL_ 1231 DslExhFluidLvlPrcntV 1 "Invalid" 0 "Valid" ;
VAL_ 963 CltTmpCntlMdEmRMAct 1 "true" 0 "false" ;
VAL_ 963 CTCMERDTC_SysDes 0 "P0-Powertrain Codes SAE Controlled" 1 "P1-Powertrain Codes MFG Controlled" 2 "P2-Powertrain Codes Reserved" 3 "P3-Powertrain Codes Reserved" 4 "C0-Chassis Codes SAE Controlled" 5 "C1-Chassis Codes MFG Controlled" 6 "C2-Chassis Codes Reserved" 7 "C3-Chassis Codes Reserved" 8 "B0-Body Codes SAE Controlled" 9 "B1-Body Codes MFG Controlled" 10 "B2-Body Codes Reserved" 11 "B3-Body Codes Reserved" 12 "U0-Network Codes SAE Controlled" 13 "U1-Network Codes MFG Controlled" 14 "U2- Network Codes Reserved" 15 "U3-Network Codes Reserved" ;
VAL_ 955 RHCS_RdctHtrCCurrV 1 "Invalid" 0 "Valid" ;
VAL_ 955 RHCS_RdctHtrBCurrV 1 "Invalid" 0 "Valid" ;
VAL_ 955 RHCS_RdctHtrACurrV 1 "Invalid" 0 "Valid" ;
VAL_ 423 TrnsInpDvcStat 7 "Unused and Reserved 5" 6 "Unused and Reserved 4" 5 "Unused and Reserved 3" 4 "Unused and Reserved 2" 3 "Unused and Reserved 1" 2 "Permanent Isolation" 1 "Temporary Isolation" 0 "Normal Control" ;
VAL_ 423 TrnsPTSysShtdwnRq 1 "true" 0 "false" ;
VAL_ 423 TransClch1FlAch 1 "true" 0 "false" ;
VAL_ 423 TransHydrlcDfltgAct 1 "true" 0 "false" ;
VAL_ 423 TCFS_Cltch5FltStat 0 "None" 1 "Failed Off Fault Active" 2 "Failed On Fault Active" 3 "Failed Off Fault Pending" 4 "Failed On Fault Pending" 5 "Mismatch" ;
VAL_ 423 TCFS_Cltch4FltStat 0 "None" 1 "Failed Off Fault Active" 2 "Failed On Fault Active" 3 "Failed Off Fault Pending" 4 "Failed On Fault Pending" 5 "Mismatch" ;
VAL_ 423 TCFS_Cltch3FltStat 0 "None" 1 "Failed Off Fault Active" 2 "Failed On Fault Active" 3 "Failed Off Fault Pending" 4 "Failed On Fault Pending" 5 "Mismatch" ;
VAL_ 423 TCFS_Cltch2FltStat 0 "None" 1 "Failed Off Fault Active" 2 "Failed On Fault Active" 3 "Failed Off Fault Pending" 4 "Failed On Fault Pending" 5 "Mismatch" ;
VAL_ 423 TCFS_Cltch1FltStat 0 "None" 1 "Failed Off Fault Active" 2 "Failed On Fault Active" 3 "Failed Off Fault Pending" 4 "Failed On Fault Pending" 5 "Mismatch" ;
VAL_ 423 TCAS_Cltch5AvlbltyStat 0 "Unavailable" 1 "Ready" 2 "Allowed" 3 "Unused and Reserved" ;
VAL_ 423 TCAS_Cltch4AvlbltyStat 0 "Unavailable" 1 "Ready" 2 "Allowed" 3 "Unused and Reserved" ;
VAL_ 423 TCAS_Cltch3AvlbltyStat 0 "Unavailable" 1 "Ready" 2 "Allowed" 3 "Unused and Reserved" ;
VAL_ 423 TCAS_Cltch2AvlbltyStat 0 "Unavailable" 1 "Ready" 2 "Allowed" 3 "Unused and Reserved" ;
VAL_ 423 TCAS_Cltch1AvlbltyStat 0 "Unavailable" 1 "Ready" 2 "Allowed" 3 "Unused and Reserved" ;
SIG_GROUP_ 872 ElcShftBrkgRq 1 : ESBR_AutoBrkgRqTyp ESBR_AutoBrkgRqd;
SIG_GROUP_ 1275 BrkSysCtl2EmnsRelDTC 1 : BSC2ERDTC_CdNum BSC2ERDTC_SysDes;
SIG_GROUP_ 1273 BrkSysCtl1EmnsRelDTC 1 : BSC1ERDTC_CdNum BSC1ERDTC_SysDes;
SIG_GROUP_ 1271 BatSvrMdCurrTrgr 1 : BSMCT_RawVal BSMCT_Mult;
SIG_GROUP_ 558 CmpDataPkt 1 : CDP_HVDevShtdnCdARCSt CDP_CmpSpdReqARCSt CDP_CmpLossCommOcc CDP_CmpWkUp CDP_CmpRunCrnk;
SIG_GROUP_ 558 CmpDevStPkt 1 : CDSP_CmpOvrTmpSt CDSP_CmpHVAbnrlOrVltSt CDSP_CmpHVUndrVltgSt CDSP_CmpHVOvrVltgSt CDSP_CmpHVOvrCrntSt CDSP_OvrTempWrnInd CDSP_CmpDgrdOp CDSP_CmpIntShdwnFltSt CDSP_CmpIntRecblFltSt CDSP_CmpOpOvrldSt CDSP_CmpDrCrctFltSt CDSP_CmpMtrPerfFltSt CDSP_CmpEEPROMFltSt CDSP_CmpROMFltSt CDSP_CmpRAMFltSt;
SIG_GROUP_ 558 CmpSnsrStPkt 1 : CSSP_CmpIGBTTpOtRgLSt CSSP_CmpIGBTTpOtRgHSt CSSP_CmpCPUTmpOtRgLSt CSSP_CmpCPUTmpOtRgHSt CSSP_CmpHVSnsOtRgLSt CSSP_CmpHVSnsOtRgHSt CSSP_CmpPhCrntOtRgLSt CSSP_CmpPhCrntOtRgHSt;
SIG_GROUP_ 1034 CurvRghtLine 1 : CRL_Cnfdnc CRL_ViewRng CRL_CoefdA CRL_CoefA;
SIG_GROUP_ 1033 CurvLftLine 1 : CLL_Cnfdnc CLL_ViewRng CLL_CoefdA CLL_CoefA;
SIG_GROUP_ 1013 TransRngDgFlt 1 : TRDF_TransPrkRgDgFlt TRDF_TrsFwDrvRgDgFlt TRDF_TransNeutRgDgFlt TRDF_TransRvsRgDgFlt;
SIG_GROUP_ 308 PedFrndlyAlrtStat 1 : PFAS_SrvPedAlrtIO PFAS_PFASysStat PFAS_PFASndVolCtrl PFAS_PFASndGenEn PFAS_PFARevSnd PFAS_PFAFwdSnd PFAS_PFACrsOvrSpd;
SIG_GROUP_ 426 EngVarTrqCapStat 1 : EVTCS_CmdTrqCapMd EVTCS_CrntTrqCapMd;
SIG_GROUP_ 963 CoolTmpCntlMdERDTC 1 : CTCMERDTC_SysDes CTCMERDTC_CdNum;
SIG_GROUP_ 955 RdctHtrCctStat 1 : RHCS_RdctHtrCCurrV RHCS_RdctHtrBCurrV RHCS_RdctHtrACurrV;
SIG_GROUP_ 423 TransCltchFltStat 1 : TCFS_Cltch5FltStat TCFS_Cltch4FltStat TCFS_Cltch3FltStat TCFS_Cltch2FltStat TCFS_Cltch1FltStat;
SIG_GROUP_ 423 TransCltchAvlbltyStat 1 : TCAS_Cltch5AvlbltyStat TCAS_Cltch4AvlbltyStat TCAS_Cltch3AvlbltyStat TCAS_Cltch2AvlbltyStat TCAS_Cltch1AvlbltyStat;
